VERSION ""

NS_ :

BS_:

BU_: GENERIC_GWMWakeup Generic_BCM TRM GWM _delete APIM SODL RTM FCIM PDM SCMH SCMG HSWM GPSM RSM SODR DDM RBM DSM SCME TSTR

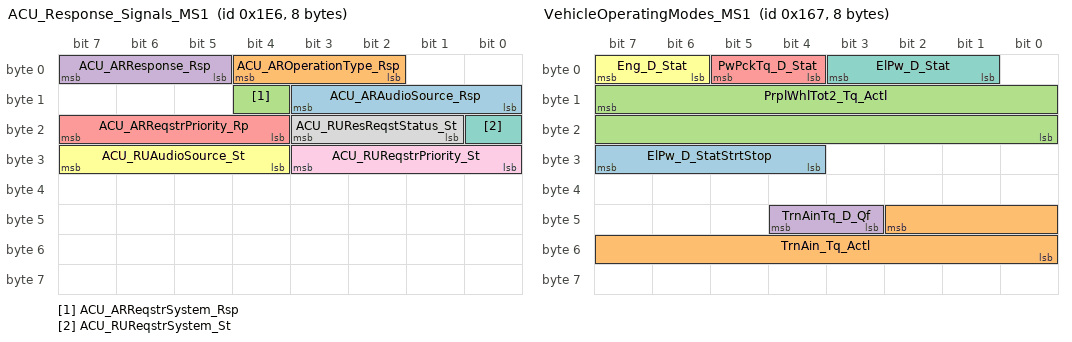
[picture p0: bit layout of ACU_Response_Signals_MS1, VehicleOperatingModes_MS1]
BO_ 486 ACU_Response_Signals_MS1: 8 GWM
 SG_ ACU_ARAudioSource_Rsp : 11|4@0+ (1,0) [0|15] "unitless"  FCIM
 SG_ ACU_AROperationType_Rsp : 4|3@0+ (1,0) [0|7] "unitless"  FCIM
 SG_ ACU_ARReqstrSystem_Rsp : 12|1@0+ (1,0) [0|1] "unitless"  FCIM
 SG_ ACU_ARResponse_Rsp : 7|3@0+ (1,0) [0|6] "unitless"  FCIM
 SG_ ACU_ARReqstrPriority_Rp : 23|4@0+ (1,0) [0|15] "unitless"  FCIM
 SG_ ACU_RUAudioSource_St : 31|4@0+ (1,0) [0|15] "unitless"  FCIM
 SG_ ACU_RUReqstrSystem_St : 16|1@0+ (1,0) [0|1] "unitless"  FCIM
 SG_ ACU_RUResReqstStatus_St : 19|3@0+ (1,0) [0|7] "unitless"  FCIM
 SG_ ACU_RUReqstrPriority_St : 27|4@0+ (1,0) [0|15] "unitless"  FCIM

BO_ 359 VehicleOperatingModes_MS1: 8 GWM
 SG_ ElPw_D_StatStrtStop : 31|4@0+ (1,0) [0|15] "SED" Vector__XXX
 SG_ TrnAin_Tq_Actl : 42|11@0+ (1,-500) [-500|1547] "Nm" Vector__XXX
 SG_ PrplWhlTot2_Tq_Actl : 15|16@0+ (4,-131072) [-131072|131060] "Nm" Vector__XXX
 SG_ TrnAinTq_D_Qf : 44|2@0+ (1,0) [0|3] "SED" Vector__XXX
 SG_ PwPckTq_D_Stat : 5|2@0+ (1,0) [0|3] "SED"  SCME,RSM,HSWM,TRM,SCMH,SCMG,RTM,RBM,PDM,GPSM,FCIM,DSM,DDM
 SG_ Eng_D_Stat : 7|2@0+ (1,0) [0|3] "SED"  FCIM
 SG_ ElPw_D_Stat : 3|3@0+ (1,0) [0|7] "SED"  SCMG,SCMH,TRM,DDM,DSM,FCIM,GPSM,PDM,RBM,RTM

BO_ 131 Yaw_Data_MS1: 8 GWM
 SG_ VehYaw_W_Actl_UB : 40|1@0+ (1,0) [0|1] "SED"  SODL,SODR,GPSM
 SG_ VehYaw_W_Actl : 55|16@0+ (0.0002,-6.5) [-6.5|6.6066] "rad/s"  SODL,SODR,GPSM

BO_ 990 Personality_DDM_Data: 8 DDM
 SG_ FeatNoDdm_No_Actl : 23|16@0+ (1,0) [0|65535] "Number"  GWM
 SG_ FeatConfigDdmActl : 7|16@0+ (1,0) [0|65535] "Undefined"  GWM

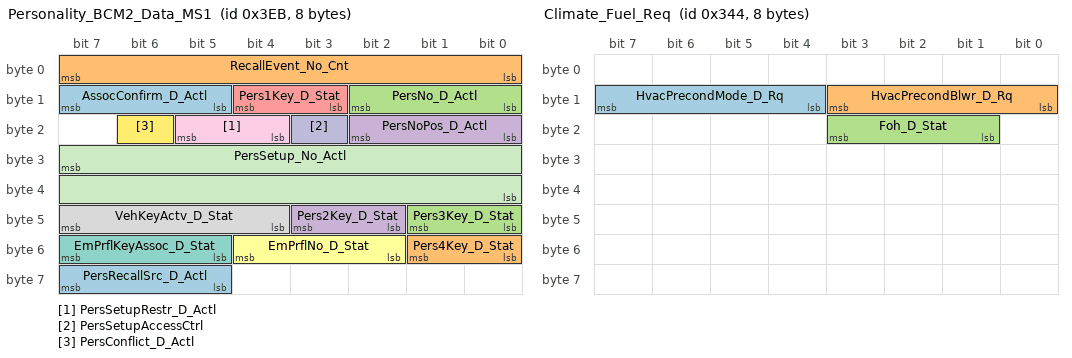
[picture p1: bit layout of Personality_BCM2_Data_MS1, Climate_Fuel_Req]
BO_ 1003 Personality_BCM2_Data_MS1: 8 GWM
 SG_ PersRecallSrc_D_Actl : 63|3@0+ (1,0) [0|7] "SED"  DSM
 SG_ Pers4Key_D_Stat : 49|2@0+ (1,0) [0|3] "SED" Vector__XXX
 SG_ Pers3Key_D_Stat : 41|2@0+ (1,0) [0|3] "SED" Vector__XXX
 SG_ Pers2Key_D_Stat : 43|2@0+ (1,0) [0|3] "SED" Vector__XXX
 SG_ Pers1Key_D_Stat : 12|2@0+ (1,0) [0|3] "SED" Vector__XXX
 SG_ EmPrflNo_D_Stat : 52|3@0+ (1,0) [0|7] "SED" Vector__XXX
 SG_ EmPrflKeyAssoc_D_Stat : 55|3@0+ (1,0) [0|7] "SED" Vector__XXX
 SG_ VehKeyActv_D_Stat : 47|4@0+ (1,0) [0|15] "SED" Vector__XXX
 SG_ PersSetupRestr_D_Actl : 21|2@0+ (1,0) [0|3] "SED"  DDM,DSM,FCIM
 SG_ PersSetupAccessCtrl : 19|1@0+ (1,0) [0|1] "SED"  DDM,FCIM,DSM
 SG_ PersSetup_No_Actl : 31|16@0+ (1,0) [0|65535] "Number"  DDM,DSM,FCIM
 SG_ PersConflict_D_Actl : 22|1@0+ (1,0) [0|1] "SED" Vector__XXX
 SG_ AssocConfirm_D_Actl : 15|3@0+ (1,0) [0|7] "SED" Vector__XXX
 SG_ RecallEvent_No_Cnt : 7|8@0+ (1,0) [0|255] "Counts"  SCMG,SCMH,DDM,DSM,FCIM
 SG_ PersNo_D_Actl : 10|3@0+ (1,0) [0|7] "SED"  DDM,DSM,FCIM,SCMG,SCMH
 SG_ PersNoPos_D_Actl : 18|3@0+ (1,0) [0|7] "SED"  SCMG,SCMH,DSM

BO_ 1945 TesterPhysicalResTRM: 8 TRM
 SG_ TesterPhysicalResTRM : 7|64@0+ (1,0) [0|1.84467E+019] "unitless"  TSTR

BO_ 836 Climate_Fuel_Req: 8 GENERIC_GWMWakeup
 SG_ HvacPrecondMode_D_Rq : 15|4@0+ (1,0) [0|15] "SED"  GWM
 SG_ HvacPrecondBlwr_D_Rq : 11|4@0+ (1,0) [0|15] "SED"  GWM
 SG_ Foh_D_Stat : 19|3@0+ (1,0) [0|7] "SED"  GWM

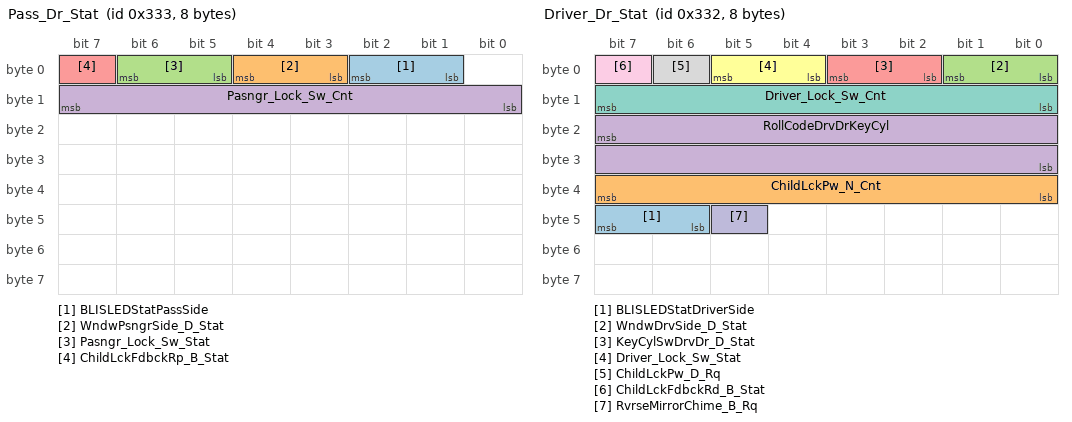
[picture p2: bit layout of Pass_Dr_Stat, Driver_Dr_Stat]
BO_ 819 Pass_Dr_Stat: 8 PDM
 SG_ BLISLEDStatPassSide : 2|2@0+ (1,0) [0|3] "SED"  SODL,SODR
 SG_ WndwPsngrSide_D_Stat : 4|2@0+ (1,0) [0|3] "SED"  GWM
 SG_ Pasngr_Lock_Sw_Stat : 6|2@0+ (1,0) [0|3] "SED"  GWM
 SG_ Pasngr_Lock_Sw_Cnt : 15|8@0+ (1,0) [0|255] "Cnt"  GWM
 SG_ ChildLckFdbckRp_B_Stat : 7|1@0+ (1,0) [0|1] "SED"  GWM

BO_ 818 Driver_Dr_Stat: 8 DDM
 SG_ BLISLEDStatDriverSide : 47|2@0+ (1,0) [0|3] "SED"  SODL,SODR
 SG_ ChildLckPw_N_Cnt : 39|8@0+ (1,0) [0|255] "unitless"  GWM
 SG_ WndwDrvSide_D_Stat : 1|2@0+ (1,0) [0|3] "SED"  GWM
 SG_ RollCodeDrvDrKeyCyl : 23|16@0+ (1,0) [0|65535] "Unitless"  GWM
 SG_ KeyCylSwDrvDr_D_Stat : 3|2@0+ (1,0) [0|3] "SED"  GWM
 SG_ Driver_Lock_Sw_Stat : 5|2@0+ (1,0) [0|3] "SED"  GWM
 SG_ Driver_Lock_Sw_Cnt : 15|8@0+ (1,0) [0|255] "Cnt"  GWM
 SG_ ChildLckPw_D_Rq : 6|1@0+ (1,0) [0|1] "SED"  GWM
 SG_ ChildLckFdbckRd_B_Stat : 7|1@0+ (1,0) [0|1] "SED"  GWM
 SG_ RvrseMirrorChime_B_Rq : 45|1@0+ (1,0) [0|1] "SED"  DSM,GWM

BO_ 817 Locking_Systems_2_MS1: 8 GWM
 SG_ R_Pwr_Sliding_Dr_Rqst : 36|1@0+ (1,0) [0|1] "SED" Vector__XXX
 SG_ L_Pwr_Sliding_Dr_Rqst : 3|1@0+ (1,0) [0|1] "SED" Vector__XXX
 SG_ ChildLckMde_B_Stat : 56|1@0+ (1,0) [0|1] "SED" Vector__XXX
 SG_ VehLckInd_D_Rq : 58|2@0+ (1,0) [0|3] "SED"  DDM,PDM
 SG_ DrTgateOpen_B_Rq : 59|1@0+ (1,0) [0|1] "SED" Vector__XXX
 SG_ DrTgateExtSwMde_B_Stat : 32|1@0+ (1,0) [0|1] "SED" Vector__XXX
 SG_ Remote_Device_Feedback : 50|3@0+ (1,0) [0|7] "SED"  RSM,RTM
 SG_ Power_Liftgate_Rqst : 0|1@0+ (1,0) [0|1] "SED" Vector__XXX
 SG_ Power_Decklid_Rqst : 1|1@0+ (1,0) [0|1] "SED" Vector__XXX
 SG_ Keyfob_Pad_Msg_Count : 15|8@0+ (1,0) [0|255] "Counts" Vector__XXX
 SG_ Veh_Lock_Requestor : 55|5@0+ (1,0) [0|31] "SED"  RSM,DDM,PDM
 SG_ Veh_Lock_EvNum : 47|8@0+ (1,0) [0|255] "unitless"  RSM,DDM,PDM
 SG_ Veh_Lock_Sub_Id : 63|4@0+ (1,0) [0|15] "SED"  RSM,DDM,PDM
 SG_ ChildLck_D_Dsply : 7|2@0+ (1,0) [0|3] "SED"  DDM
 SG_ WindowLockout_B_Stat : 35|1@0+ (1,0) [0|1] "SED"  DDM
 SG_ RollCodeUnlock : 23|16@0+ (1,0) [0|65535] "Unitless"  RSM,DDM
 SG_ Lockmsgtxt_D_Rq : 39|3@0+ (1,0) [0|7] "SED" Vector__XXX
 SG_ LockInhibit : 2|1@0+ (1,0) [0|1] "SED" Vector__XXX
 SG_ Veh_Lock_Status : 34|2@0+ (1,0) [0|3] "SED"  RSM,DDM,PDM
 SG_ FobComm_D_Stat : 5|2@0+ (1,0) [0|3] "SED"  RTM

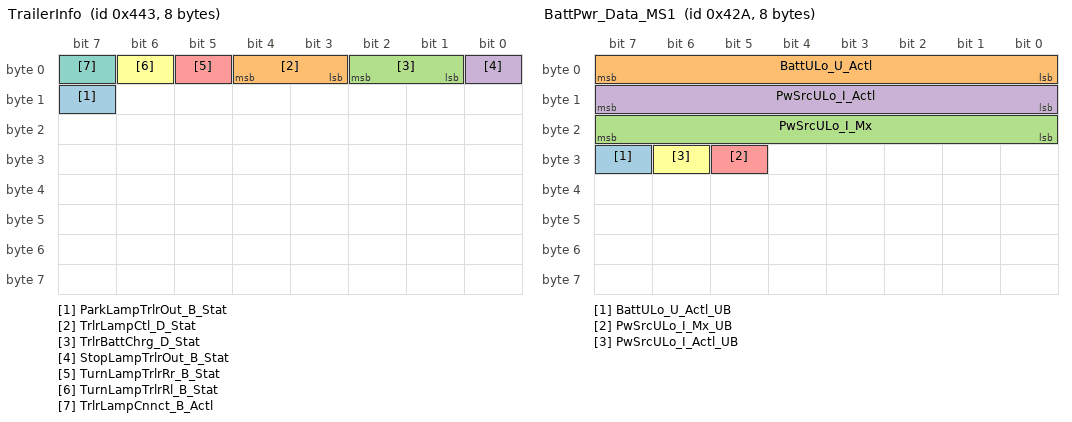
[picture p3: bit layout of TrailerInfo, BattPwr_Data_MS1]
BO_ 1091 TrailerInfo: 8 TRM
 SG_ ParkLampTrlrOut_B_Stat : 15|1@0+ (1,0) [0|1] "SED"  GWM
 SG_ TrlrLampCtl_D_Stat : 4|2@0+ (1,0) [0|3] "SED"  GWM
 SG_ TrlrBattChrg_D_Stat : 2|2@0+ (1,0) [0|3] "SED"  GWM
 SG_ StopLampTrlrOut_B_Stat : 0|1@0+ (1,0) [0|1] "SED"  GWM
 SG_ TurnLampTrlrRr_B_Stat : 5|1@0+ (1,0) [0|1] "SED"  GWM
 SG_ TurnLampTrlrRl_B_Stat : 6|1@0+ (1,0) [0|1] "SED"  GWM
 SG_ TrlrLampCnnct_B_Actl : 7|1@0+ (1,0) [0|1] "SED"  SODL,SODR,GWM

BO_ 1285 PDM_Network_MgmtM: 8 PDM
 SG_ PDM_Network_Mgmt : 7|64@0+ (1,0) [0|1.844674407371E+019] "unitless"  DDM,DSM,FCIM,GPSM,RBM,RTM,SCME,TRM,GWM,APIM

BO_ 1865 TesterPhysicalResPDM: 8 PDM
 SG_ TesterPhysicalResPDM : 7|64@0+ (1,0) [0|1.84467E+019] "unitless"  TSTR

BO_ 1857 TesterPhysicalReqPDM: 8 TSTR
 SG_ TesterPhysicalReqPDM : 7|64@0+ (1,0) [0|1.84467E+019] "unitless"  PDM

BO_ 1819 TesterPhysicalResSCMH: 8 SCMH
 SG_ TesterPhysicalResSCMH : 7|64@0+ (1,0) [0|1.84467E+019] "unitless"  TSTR

BO_ 1818 TesterPhysicalResSCMG: 8 SCMG
 SG_ TesterPhysicalResSCMG : 7|64@0+ (1,0) [0|1.84467E+019] "unitless"  TSTR

BO_ 1811 TesterPhysicalReqSCMH: 8 TSTR
 SG_ TesterPhysicalReqSCMH : 7|64@0+ (1,0) [0|1.84467E+019] "unitless"  SCMH

BO_ 1810 TesterPhysicalReqSCMG: 8 TSTR
 SG_ TesterPhysicalReqSCMG : 7|64@0+ (1,0) [0|1.84467E+019] "unitless"  SCMG

BO_ 1373 FCIM_Network_MgmtM: 8 FCIM
 SG_ FCIM_Network_Mgmt : 7|64@0+ (1,0) [0|1.844674407371E+019] "unitless"  DDM,DSM,GPSM,RBM,RTM,SCME,APIM,PDM,GWM,TRM

BO_ 1339 RTM_Network_MgmtM: 8 RTM
 SG_ RTM_Network_Mgmt : 7|64@0+ (1,0) [0|1.844674407371E+019] "unitless"  APIM,PDM,TRM,SCME,RBM,GPSM,FCIM,DSM,DDM

BO_ 1310 GWM_Network_MgmtM_MS1: 8 GWM
 SG_ GWM_Network_Mgmt_MS1 : 7|64@0+ (1,0) [0|1.844674407371E+019] "unitless"  DDM,DSM,FCIM,GPSM,PDM,RBM,RTM,SCME,TRM

BO_ 1066 BattPwr_Data_MS1: 8 GWM
 SG_ BattULo_U_Actl_UB : 31|1@0+ (1,0) [0|1] "SED"  FCIM
 SG_ BattULo_U_Actl : 7|8@0+ (0.0625,0) [0|15.875] "volt"  FCIM
 SG_ PwSrcULo_I_Mx : 23|8@0+ (1,0) [0|254] "ampere"  FCIM
 SG_ PwSrcULo_I_Actl : 15|8@0+ (1,0) [0|254] "ampere"  FCIM
 SG_ PwSrcULo_I_Mx_UB : 29|1@0+ (1,0) [0|1] "SED"  FCIM
 SG_ PwSrcULo_I_Actl_UB : 30|1@0+ (1,0) [0|1] "SED"  FCIM

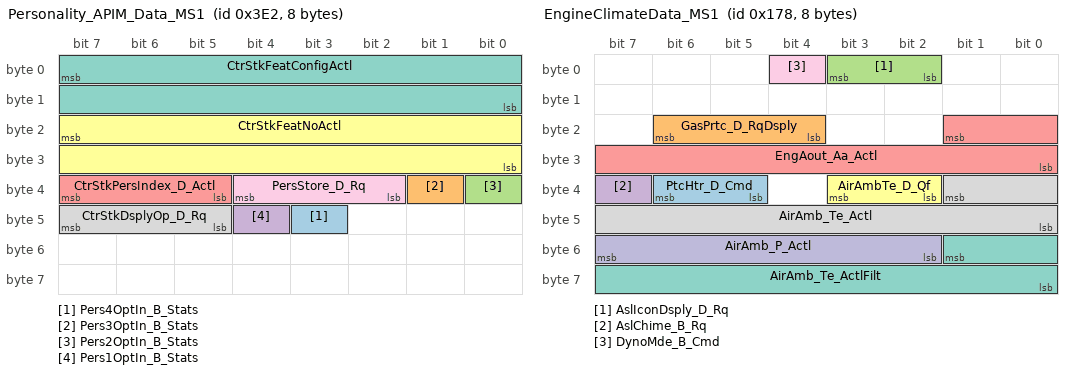
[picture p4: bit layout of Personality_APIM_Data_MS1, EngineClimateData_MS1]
BO_ 994 Personality_APIM_Data_MS1: 8 GWM
 SG_ Pers4OptIn_B_Stats : 43|1@0+ (1,0) [0|1] "SED" Vector__XXX
 SG_ Pers3OptIn_B_Stats : 33|1@0+ (1,0) [0|1] "SED" Vector__XXX
 SG_ Pers2OptIn_B_Stats : 32|1@0+ (1,0) [0|1] "SED" Vector__XXX
 SG_ Pers1OptIn_B_Stats : 44|1@0+ (1,0) [0|1] "SED" Vector__XXX
 SG_ CtrStkPersIndex_D_Actl : 39|3@0+ (1,0) [0|7] "SED"  DDM,DSM,FCIM,SCMG,SCMH
 SG_ CtrStkFeatNoActl : 23|16@0+ (1,0) [0|65535] "Undefined"  DDM,DSM,FCIM
 SG_ CtrStkFeatConfigActl : 7|16@0+ (1,0) [0|65535] "Undefined"  DDM,DSM,FCIM
 SG_ CtrStkDsplyOp_D_Rq : 47|3@0+ (1,0) [0|7] "SED"  DDM,DSM,FCIM,SCMG,SCMH
 SG_ PersStore_D_Rq : 36|3@0+ (1,0) [0|7] "SED"  DSM

BO_ 376 EngineClimateData_MS1: 8 GWM
 SG_ PtcHtr_D_Cmd : 38|2@0+ (1,0) [0|3] "SED" Vector__XXX
 SG_ GasPrtc_D_RqDsply : 22|3@0+ (1,0) [0|7] "SED" Vector__XXX
 SG_ AslIconDsply_D_Rq : 3|2@0+ (1,0) [0|3] "SED" Vector__XXX
 SG_ AslChime_B_Rq : 39|1@0+ (1,0) [0|1] "SED" Vector__XXX
 SG_ EngAout_Aa_Actl : 17|10@0+ (0.05,-25.6) [-25.6|25.55] "rpm/ms" Vector__XXX
 SG_ AirAmbTe_D_Qf : 35|2@0+ (1,0) [0|3] "SED"  FCIM
 SG_ AirAmb_Te_ActlFilt : 49|10@0+ (0.25,-128) [-128|127.75] "deg C"  FCIM
 SG_ AirAmb_Te_Actl : 33|10@0+ (0.25,-128) [-128|127.75] "degC"  FCIM
 SG_ DynoMde_B_Cmd : 4|1@0+ (1,0) [0|1] "SED" Vector__XXX
 SG_ AirAmb_P_Actl : 55|6@0+ (10,500) [500|1110] "mbar" Vector__XXX

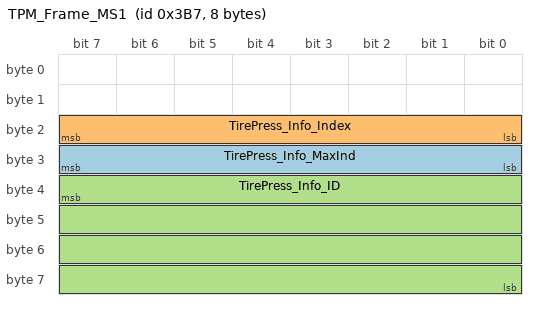
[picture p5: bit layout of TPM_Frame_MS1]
BO_ 951 TPM_Frame_MS1: 8 GWM
 SG_ TirePress_Info_MaxInd : 31|8@0+ (1,0) [0|255] "Unitless"  RTM
 SG_ TirePress_Info_Index : 23|8@0+ (1,0) [0|255] "Unitless"  RTM
 SG_ TirePress_Info_ID : 39|32@0+ (1,0) [0|4294967295] "Unitless"  RTM

BO_ 1068 Batt_Mgmt_Data_MS1: 8 GWM
 SG_ Batt_Lo_SoC_B_UB : 22|1@0+ (1,0) [0|1] "SED"  TRM,FCIM
 SG_ Batt_Lo_SoC_B : 23|1@0+ (1,0) [0|1] "SED"  TRM,FCIM
 SG_ Batt_Crit_SoC_B_UB : 14|1@0+ (1,0) [0|1] "SED"  TRM,FCIM
 SG_ Batt_Crit_SoC_B : 15|1@0+ (1,0) [0|1] "SED"  TRM,FCIM
 SG_ Shed_T_Eng_Off_B_UB : 12|1@0+ (1,0) [0|1] "SED"  TRM,FCIM
 SG_ Shed_T_Eng_Off_B : 13|1@0+ (1,0) [0|1] "SED"  TRM,FCIM
 SG_ Shed_Level_Req_UB : 8|1@0+ (1,0) [0|1] "SED"  DDM,PDM,TRM,FCIM
 SG_ Shed_Level_Req : 11|3@0+ (1,0) [0|7] "SED"  DDM,PDM,TRM,FCIM
 SG_ Shed_Feature_Group_ID_UB : 2|1@0+ (1,0) [0|1] "SED"  TRM,FCIM
 SG_ Shed_Feature_Group_ID : 7|5@0+ (1,0) [0|31] "SED"  TRM,FCIM
 SG_ Shed_Drain_Eng_Off_B_UB : 0|1@0+ (1,0) [0|1] "SED"  TRM,FCIM
 SG_ Shed_Drain_Eng_Off_B : 1|1@0+ (1,0) [0|1] "SED"  TRM,FCIM
 SG_ BSBattSOC_UB : 48|1@0+ (1,0) [0|1] "SED"  FCIM
 SG_ AirCondRec_B_Rq_UB : 44|1@0+ (1,0) [0|1] "SED"  FCIM
 SG_ AirCondFluidHi_P_Actl_UB : 45|1@0+ (1,0) [0|1] "SED"  FCIM
 SG_ BattULoState_D_Qlty_UB : 40|1@0+ (1,0) [0|1] "SED" Vector__XXX
 SG_ AirCondClutch_B_Stats_UB : 43|1@0+ (1,0) [0|1] "SED"  FCIM
 SG_ AirCondRec_B_Rq : 47|1@0+ (1,0) [0|1] "SED"  FCIM
 SG_ BSBattSOC : 55|7@0+ (1,0) [0|127] "%"  FCIM
 SG_ AirCondFluidHi_P_Actl : 39|8@0+ (0.125,0) [0|31.625] "bar"  FCIM
 SG_ AirCondClutch_B_Stats : 46|1@0+ (1,0) [0|1] "SED"  FCIM
 SG_ BattULoState_D_Qlty : 42|2@0+ (1,0) [0|3] "SED" Vector__XXX

BO_ 963 BCM_Lamp_Stat_MS1: 8 GWM
 SG_ WrlssAcsyChrgInhbt_B_Rq : 40|1@0+ (1,0) [0|1] "SED" Vector__XXX
 SG_ PudLampPsngr_D_Rq : 57|2@0+ (1,0) [0|3] "SED" Vector__XXX
 SG_ PudLampDrv_D_Rq : 59|2@0+ (1,0) [0|3] "SED" Vector__XXX
 SG_ DrTgateLck_D_Stat : 61|2@0+ (1,0) [0|3] "SED" Vector__XXX
 SG_ Illuminated_Entry_Stat : 63|2@0+ (1,0) [0|3] "SED" Vector__XXX
 SG_ Dr_Courtesy_Light_Stat : 49|2@0+ (1,0) [0|3] "SED" Vector__XXX
 SG_ ImpactEvntFdbck_D_Stat : 53|2@0+ (1,0) [0|3] "SED" Vector__XXX
 SG_ HeadLampLoOut_B_Stat : 32|1@0+ (1,0) [0|1] "SED" Vector__XXX
 SG_ CrnrLghtRight_Pc_Rq : 47|7@0+ (1,0) [0|100] "percent" Vector__XXX
 SG_ CrnrLghtLeft_Pc_Rq : 39|7@0+ (1,0) [0|100] "percent" Vector__XXX
 SG_ HeadLghtHiFdbck_D_Stat : 55|2@0+ (1,0) [0|3] "SED" Vector__XXX
 SG_ PrkLightChime_B_Rq : 25|1@0+ (1,0) [0|1] "SED" Vector__XXX
 SG_ TrnNotInPrkChime_B_Rq : 24|1@0+ (1,0) [0|1] "SED" Vector__XXX
 SG_ HomeSafeLtChime_B_Rq : 28|1@0+ (1,0) [0|1] "SED" Vector__XXX
 SG_ StopLghtOn_B_Stat : 8|1@0+ (1,0) [0|1] "SED"  RSM,TRM
 SG_ RvrseLghtOn_B_Stat : 9|1@0+ (1,0) [0|1] "SED"  TRM
 SG_ PrkLght_D_Stat : 13|2@0+ (1,0) [0|3] "SED"  TRM
 SG_ HeadLghtSwtch_D_Stat : 15|2@0+ (1,0) [0|3] "SED" Vector__XXX
 SG_ KeyInIgnWarn_B_Cmd : 27|1@0+ (1,0) [0|1] "SED" Vector__XXX
 SG_ HeadLampLoFrOn_B_Stat : 2|1@0+ (1,0) [0|1] "SED" Vector__XXX
 SG_ HeadLampLoFlOn_B_Stat : 3|1@0+ (1,0) [0|1] "SED" Vector__XXX
 SG_ Headlamp_On_Wrning_Cmd : 29|1@0+ (1,0) [0|1] "SED" Vector__XXX
 SG_ HeadLampLoActv_B_Stat : 4|1@0+ (1,0) [0|1] "SED" Vector__XXX
 SG_ HeadLghtHiOn_B_Stat : 1|1@0+ (1,0) [0|1] "SED" Vector__XXX
 SG_ Park_Brake_Chime_Rqst : 26|1@0+ (1,0) [0|1] "SED" Vector__XXX
 SG_ BrkWarnInd_B_Rq : 20|1@0+ (1,0) [0|1] "SED" Vector__XXX
 SG_ Brk_Fluid_Lvl_Low : 31|2@0+ (1,0) [0|3] "SED" Vector__XXX
 SG_ ReducedGuard_D_Stat : 19|2@0+ (1,0) [0|3] "SED" Vector__XXX
 SG_ Courtesy_BSave_Stat : 7|2@0+ (1,0) [0|3] "SED"  DDM,PDM
 SG_ DayRnngLampOn_B_Stat : 5|1@0+ (1,0) [0|1] "SED" Vector__XXX
 SG_ PerimeterAlarmChimeRq : 0|1@0+ (1,0) [0|1] "SED" Vector__XXX
 SG_ Courtesy_Delay_Status : 51|2@0+ (1,0) [0|3] "SED" Vector__XXX
 SG_ Perimeter_Alarm_Status : 17|2@0+ (1,0) [0|3] "SED"  RSM
 SG_ WndwGlbl_D_Cmd : 23|3@0+ (1,0) [0|7] "SED"  DDM,PDM
 SG_ PudLamp_D_Rq : 11|2@0+ (1,0) [0|3] "SED"  DDM,PDM

BO_ 964 BodyInfo_MS1: 8 GWM
 SG_ Cta_D_Rq_UB : 57|1@0+ (1,0) [0|1] "SED"  SODL,SODR
 SG_ Cta_D_Rq : 59|2@0+ (1,0) [0|3] "SED"  SODL,SODR
 SG_ GearRvrse_D_Actl_UB : 48|1@0+ (1,0) [0|1] "SED"  SODL,SODR
 SG_ GearRvrse_D_Actl : 51|3@0+ (1,0) [0|7] "SED"  SODL,SODR
 SG_ TurnLghtSwtch_D_Stat_UB : 52|1@0+ (1,0) [0|1] "SED"  SODL,SODR
 SG_ TurnLghtSwtch_D_Stat : 54|2@0+ (1,0) [0|3] "SED"  SODL,SODR
 SG_ Power_Liftgate_Mode_Cmd_UB : 6|1@0+ (1,0) [0|1] "SED" Vector__XXX
 SG_ Power_Liftgate_Mode_Cmd : 7|1@0+ (1,0) [0|1] "SED" Vector__XXX
 SG_ MetricActvTe_B_Actl_UB : 2|1@0+ (1,0) [0|1] "SED"  FCIM
 SG_ MetricActvTe_B_Actl : 3|1@0+ (1,0) [0|1] "SED"  FCIM
 SG_ EngClntTe_D_Qf : 22|2@0+ (1,0) [0|3] "SED"  FCIM
 SG_ Sod_D_Rq : 1|2@0+ (1,0) [0|3] "SED"  SODL,SODR
 SG_ MetricActv_B_Actl : 5|1@0+ (1,0) [0|1] "SED"  FCIM
 SG_ EngClnt_Te_Actl : 15|8@0+ (1,-60) [-60|195] "degC"  FCIM
 SG_ MetricActv_B_Actl_UB : 4|1@0+ (1,0) [0|1] "SED"  FCIM
 SG_ EngClnt_Te_Actl_UB : 23|1@0+ (1,0) [0|1] "SED"  FCIM
 SG_ OCSSensrDataUpperLim_UB : 28|1@0+ (1,0) [0|1] "SED"  SCMG,SCMH,FCIM
 SG_ OCSSensrDataUpperLim : 47|8@0+ (1,0) [0|254] "SED"  SCMG,SCMH,FCIM
 SG_ OCSSensrDataLowerLim_UB : 29|1@0+ (1,0) [0|1] "SED"  SCMG,SCMH,FCIM
 SG_ PrkAid_D_Falt : 18|3@0+ (1,0) [0|7] "SED" Vector__XXX
 SG_ OCSSensrDataLowerLim : 39|8@0+ (1,0) [0|254] "SED"  SCMG,SCMH,FCIM
 SG_ PrkAid_D_Falt_UB : 63|1@0+ (1,0) [0|1] "SED" Vector__XXX
 SG_ WiprFront_D_Stat_UB : 55|1@0+ (1,0) [0|1] "SED"  FCIM,SODL,SODR
 SG_ WiprFront_D_Stat : 27|4@0+ (1,0) [0|15] "SED"  FCIM,SODL,SODR
 SG_ CamraDefog_B_Req_UB : 30|1@0+ (1,0) [0|1] "SED" Vector__XXX
 SG_ Sod_D_Rq_UB : 19|1@0+ (1,0) [0|1] "SED"  SODL,SODR
 SG_ CamraDefog_B_Req : 31|1@0+ (1,0) [0|1] "SED" Vector__XXX

CM_ SG_ 486 ACU_ARAudioSource_Rsp "Object Audio Management AudioClient.AudioRequest.Requested Audio Source";
CM_ SG_ 486 ACU_AROperationType_Rsp "Object Audio Management AudioClient.AudioRequest.Operation Type";
CM_ SG_ 486 ACU_ARReqstrSystem_Rsp "Object Audio Management AudioClient.AudioRequest.Requester System";
CM_ SG_ 486 ACU_ARResponse_Rsp "Object Audio Management AudioClient.AudioRequest.Response";
CM_ SG_ 486 ACU_ARReqstrPriority_Rp "AR = Audio Request (this signal belongs to the logical signal AudioRequest.Rsp)
Object = AudioClient
Logical Signal = AudioRequest
Parameter = Requester Priority

Disc shall be used for both CD and MC";
CM_ SG_ 486 ACU_RUAudioSource_St "Object Audio Management Audio Client.ResourceUpdate.Requested Audio Source
";
CM_ SG_ 486 ACU_RUReqstrSystem_St "Object Audio Management Audio Client.ResourceUpdate.Requester System";
CM_ SG_ 486 ACU_RUResReqstStatus_St "Object Audio Management Audio Client.ResourceUpdate.Resource Request Status";
CM_ SG_ 486 ACU_RUReqstrPriority_St "Object Audio Management Audio Client.ResourceUpdate.Requester Priority";
CM_ SG_ 359 TrnAin_Tq_Actl "Signal not transmitted on HEV variances.";
CM_ SG_ 359 TrnAinTq_D_Qf "Signal not transmitted on HEV variances.";
CM_ SG_ 131 VehYaw_W_Actl "CCMGenSigTimeoutTime=1000";
CM_ SG_ 836 HvacPrecondMode_D_Rq "Signal not transmitted on vehicles that do not have the Fuel operated heater feature.";
CM_ SG_ 836 HvacPrecondBlwr_D_Rq "Signal not transmitted on vehicles that do not have the Fuel operated heater feature.";
CM_ SG_ 836 Foh_D_Stat "Signal not transmitted on vehicles that do not have the Fuel operated heater feature.";
CM_ SG_ 1091 TrlrLampCnnct_B_Actl "Not supported on CD4 M1";
CM_ SG_ 376 EngAout_Aa_Actl "Signal not transmitted on HEV variants.";
CM_ SG_ 1068 AirCondRec_B_Rq "Signal not transmitted on diesel variants.";
CM_ SG_ 1068 AirCondClutch_B_Stats "Signal not transmitted on diesel variants.";
CM_ SG_ 964 GearRvrse_D_Actl "Do not implement GearRvrse_D_Actl  until eTracker 8804151 is approved, 11/24/09";
CM_ SG_ 964 MetricActv_B_Actl "0 =Inactive(English), 1=Active(Metric)";
BA_DEF_ SG_  "U_V36X_MY18_5_Gas_Rx" ENUM  "No","Yes";
BA_DEF_ SG_  "U_V36X_MY18_5_Hev_Rx" ENUM  "No","Yes";
BA_DEF_ SG_  "U_U55x_MY18_Gas_Rx" ENUM  "No","Yes";
BA_DEF_ SG_  "U_V408_MY18_Gas_Rx" ENUM  "No","Yes";
BA_DEF_ SG_  "U_V408_MY18_Diesel_Rx" ENUM  "No","Yes";
BA_DEF_ SG_  "U_V36X_MY18_5_Diesel_Rx" ENUM  "No","Yes";
BA_DEF_ SG_  "U_V36X_MY19_5_Diesel_Rx" ENUM  "No","Yes";
BA_DEF_ SG_  "U_V363E_N_MY19_5_20_Gas_Rx" ENUM  "No","Yes";
BA_DEF_ SG_  "U_V363E_N_MY19_5_20_Diesel_Rx" ENUM  "No","Yes";
BA_DEF_ SG_  "U_U55x_MY18_Gas_Tx" ENUM  "No","Yes";
BA_DEF_ SG_  "GenSigTimeoutTime_SCMJ" INT 0 100000;
BA_DEF_ BO_  "FrameGatewayNetwork" STRING ;
BA_DEF_ SG_  "U_CD42_MY16_Diesel_Rx" ENUM  "No","Yes";
BA_DEF_ SG_  "U_CD42_MY16_Gas_Rx" ENUM  "No","Yes";
BA_DEF_ SG_  "U_CD43_MY17_Gas_Rx" ENUM  "No","Yes";
BA_DEF_ SG_  "U_P552_MY17_Gas_Rx" ENUM  "No","Yes";
BA_DEF_ SG_  "U_P552_MY17_Gas_Tx" ENUM  "No","Yes";
BA_DEF_ SG_  "GenSigTimeoutTime_SOBDMD_AHCM_F" INT 0 100000;
BA_DEF_ SG_  "GenSigTimeoutTime_SFMA" INT 0 100000;
BA_DEF_ SG_  "GenSigTimeoutTime_SFMB" INT 0 100000;
BA_DEF_ SG_  "GenSigTimeoutTime_SCMD" INT 0 100000;
BA_DEF_ SG_  "GenSigTimeoutTime_DCMH" INT 0 100000;
BA_DEF_ SG_  "GenSigTimeoutTime_DCMG" INT 0 100000;
BA_DEF_ SG_  "GenSigTimeoutTime_DCMF" INT 0 100000;
BA_DEF_ SG_  "GenSigTimeoutTime_DCME" INT 0 100000;
BA_DEF_ SG_  "GenSigTimeoutTime_BCMB_ABM" INT 0 100000;
BA_DEF_ SG_  "GenSigTimeoutTime_SCMC" INT 0 100000;
BA_DEF_ SG_  "GenSigTimeoutTime_BCMB_CAPM" INT 0 100000;
BA_DEF_ SG_  "GenSigTimeoutTime_GFM_ASM" INT 0 100000;
BA_DEF_ SG_  "GenSigTimeoutTime_SCMB_PSM" INT 0 100000;
BA_DEF_ SG_  "GenSigTimeoutTime_BCMB_ALCM" INT 0 100000;
BA_DEF_ SG_  "U_CD42_MY15_Diesel_Rx" ENUM  "No","Yes";
BA_DEF_ SG_  "U_CD42_MY15_Gas_Rx" ENUM  "No","Yes";
BA_DEF_ SG_  "U_U502_MY16_Gas_Rx" ENUM  "No","Yes";
BA_DEF_ SG_  "U_P558_MY17_Gas_Rx" ENUM  "No","Yes";
BA_DEF_ SG_  "U_P558_MY17_Diesel_Rx" ENUM  "No","Yes";
BA_DEF_ SG_  "U_CD42_MY15_Diesel_Tx" ENUM  "No","Yes";
BA_DEF_ SG_  "U_CD42_MY15_Gas_Tx" ENUM  "No","Yes";
BA_DEF_ SG_  "U_CD4_MY15_Diesel_Tx" ENUM  "No","Yes";
BA_DEF_ SG_  "U_CD4_MY15_Gas_Tx" ENUM  "No","Yes";
BA_DEF_ SG_  "U_CD4_MY15_Hev_Tx" ENUM  "No","Yes";
BA_DEF_ SG_  "U_CD4_MY15_Phev_Tx" ENUM  "No","Yes";
BA_DEF_ SG_  "U_P558_MY17_Gas_Tx" ENUM  "No","Yes";
BA_DEF_ SG_  "U_P558_MY17_Diesel_Tx" ENUM  "No","Yes";
BA_DEF_ SG_  "GenSigTimeoutTime_SCMF" INT 0 100000;
BA_DEF_ SG_  "GenSigTimeoutTime_RGTM" INT 0 100000;
BA_DEF_ SG_  "GenSigTimeoutTime_GENERIC" INT 0 100000;
BA_DEF_ SG_  "GenSigTimeoutTime_AHCM_FOH" INT 0 100000;
BA_DEF_ SG_  "GenSigTimeoutTime_RLCMA" INT 0 100000;
BA_DEF_ SG_  "GenSigTimeoutTime_BCMB" INT 0 100000;
BA_DEF_ SG_  "GenSigTimeoutTime_RHVAC" INT 0 100000;
BA_DEF_ SG_  "GenSigTimeoutTime_MRCMB" INT 0 100000;
BA_DEF_ SG_  "GenSigTimeoutTime_MRCMA" INT 0 100000;
BA_DEF_ SG_  "GenSigTimeoutTime_HVAC_RCCM" INT 0 100000;
BA_DEF_ SG_  "Gateway_ID" INT 0 0;
BA_DEF_ SG_  "GenSigTimeoutTime__delete" INT 0 100000;
BA_DEF_ SG_  "GenSigTimeoutTime_APIM" INT 0 100000;
BA_DEF_ SG_  "GenSigTimeoutTime_Generic_BCM" INT 0 100000;
BA_DEF_ SG_  "GenSigTimeoutTime_RSM" INT 0 100000;
BA_DEF_ SG_  "GenSigTimeoutTime_PDM" INT 0 100000;
BA_DEF_ SG_  "GenSigTimeoutTime_TRM" INT 0 100000;
BA_DEF_ SG_  "GenSigTimeoutTime_SCMG" INT 0 100000;
BA_DEF_ SG_  "GenSigTimeoutTime_SCMH" INT 0 100000;
BA_DEF_ SG_  "GenSigTimeoutTime_RTM" INT 0 100000;
BA_DEF_ SG_  "GenSigTimeoutTime_GWM" INT 0 100000;
BA_DEF_ SG_  "GenSigTimeoutTime_FCIM" INT 0 100000;
BA_DEF_ SG_  "GenSigTimeoutTime_HSWM" INT 0 100000;
BA_DEF_ SG_  "GenSigTimeoutTime_GPSM" INT 0 100000;
BA_DEF_ SG_  "GenSigTimeoutTime_RBM" INT 0 100000;
BA_DEF_ SG_  "GenSigTimeoutTime_DDM" INT 0 100000;
BA_DEF_ SG_  "GenSigTimeoutTime_DSM" INT 0 100000;
BA_DEF_ SG_  "GenSigTimeoutTime_SODR" INT 0 100000;
BA_DEF_ SG_  "GenSigTimeoutTime_SODL" INT 0 100000;
BA_DEF_ SG_  "GenSigTimeoutTime_TSTR" INT 0 100000;
BA_DEF_ SG_  "GenSigTimeoutTime_SCME" INT 0 100000;
BA_DEF_ BO_  "FrameGatewayMS1" HEX 0 1407;
BA_DEF_ BO_  "FrameGatewayHS3" HEX 0 1407;
BA_DEF_ BO_  "FrameGatewayHS2" HEX 0 1407;
BA_DEF_ BO_  "FrameGatewayHS1" HEX 0 1407;
BA_DEF_ BO_  "NetworkInitialization" ENUM  "No","Yes";
BA_DEF_ BO_  "FrameGatewayId" HEX 0 1407;
BA_DEF_ BO_  "EventRateOfChange" INT 10 10000;
BA_DEF_ BO_  "GenMsgStartDelayTime" INT 0 10000;
BA_DEF_ BO_  "GenMsgNrOfRepetition" INT 0 100;
BA_DEF_ BO_  "GenMsgDelayTime" INT 0 1000;
BA_DEF_ BO_  "GenMsgCycleTime" INT 0 100000;
BA_DEF_ BO_  "GenMsgSendType" ENUM  "FixedPeriodic","Event","EnabledPeriodic","NotUsed","NotUsed","EventPeriodic","NotUsed","NotUsed","NoMsgSendType";
BA_DEF_ SG_  "U_CD4_MY14_Phev_Tx" ENUM  "No","Yes";
BA_DEF_ SG_  "U_CD4_MY14_Hev_Tx" ENUM  "No","Yes";
BA_DEF_ SG_  "U_CD4_MY14_Gas_Tx" ENUM  "No","Yes";
BA_DEF_ SG_  "U_CD4_MY14_Diesel_Tx" ENUM  "No","Yes";
BA_DEF_ SG_  "U_CD43_MY16_Gas_Tx" ENUM  "No","Yes";
BA_DEF_ SG_  "U_UP375_MY15_Diesel_Tx" ENUM  "No","Yes";
BA_DEF_ SG_  "U_UP375_MY15_Gas_Tx" ENUM  "No","Yes";
BA_DEF_ SG_  "U_U502_MY15_Gas_Tx" ENUM  "No","Yes";
BA_DEF_ SG_  "U_B562LC_MY14_Gas_Tx" ENUM  "No","Yes";
BA_DEF_ SG_  "U_B562LC_MY14_Diesel_Tx" ENUM  "No","Yes";
BA_DEF_ SG_  "U_C489_MY14_Gas_Tx" ENUM  "No","Yes";
BA_DEF_ SG_  "U_S550_MY15_Gas_Tx" ENUM  "No","Yes";
BA_DEF_ SG_  "U_P552_MY15_Gas_Tx" ENUM  "No","Yes";
BA_DEF_ SG_  "U_CD42_MY14_Gas_Tx" ENUM  "No","Yes";
BA_DEF_ SG_  "U_CD42_MY14_Diesel_Tx" ENUM  "No","Yes";
BA_DEF_ SG_  "U_CD4_MY13_Phev_Tx" ENUM  "No","Yes";
BA_DEF_ SG_  "U_CD4_MY13_Hev_Tx" ENUM  "No","Yes";
BA_DEF_ SG_  "U_CD4_MY13_Gas_Tx" ENUM  "No","Yes";
BA_DEF_ SG_  "U_CD4_MY13_Diesel_Tx" ENUM  "No","Yes";
BA_DEF_ SG_  "U_CD4_MY14_Phev_Rx" ENUM  "No","Yes";
BA_DEF_ SG_  "U_CD4_MY14_Hev_Rx" ENUM  "No","Yes";
BA_DEF_ SG_  "U_CD4_MY14_Gas_Rx" ENUM  "No","Yes";
BA_DEF_ SG_  "U_CD4_MY14_Diesel_Rx" ENUM  "No","Yes";
BA_DEF_ SG_  "U_CD43_MY16_Gas_Rx" ENUM  "No","Yes";
BA_DEF_ SG_  "U_UP375_MY15_Diesel_Rx" ENUM  "No","Yes";
BA_DEF_ SG_  "U_UP375_MY15_Gas_Rx" ENUM  "No","Yes";
BA_DEF_ SG_  "U_B479_MY15_Gas_Rx" ENUM  "No","Yes";
BA_DEF_ SG_  "U_U502_MY15_Gas_Rx" ENUM  "No","Yes";
BA_DEF_ SG_  "U_B562LC_MY14_Gas_Rx" ENUM  "No","Yes";
BA_DEF_ SG_  "U_B562LC_MY14_Diesel_Rx" ENUM  "No","Yes";
BA_DEF_ SG_  "U_C489_MY14_Gas_Rx" ENUM  "No","Yes";
BA_DEF_ SG_  "U_S550_MY15_Gas_Rx" ENUM  "No","Yes";
BA_DEF_ SG_  "U_P552_MY15_Gas_Rx" ENUM  "No","Yes";
BA_DEF_ SG_  "U_CD42_MY14_Gas_Rx" ENUM  "No","Yes";
BA_DEF_ SG_  "U_CD42_MY14_Diesel_Rx" ENUM  "No","Yes";
BA_DEF_ SG_  "U_CD4_MY13_Phev_Rx" ENUM  "No","Yes";
BA_DEF_ SG_  "U_CD4_MY13_Hev_Rx" ENUM  "No","Yes";
BA_DEF_ SG_  "U_CD4_MY13_Gas_Rx" ENUM  "No","Yes";
BA_DEF_ SG_  "U_CD4_MY13_Diesel_Rx" ENUM  "No","Yes";
BA_DEF_ SG_  "ContentDependant" ENUM  "No","Yes";
BA_DEF_ SG_  "GenSigStartValue" INT 0 1000000000;
BA_DEF_ SG_  "UsedOnPgmDBC" ENUM  "No","Yes";
BA_DEF_ SG_  "CrossOver_LIN" ENUM  "No","Yes";
BA_DEF_ SG_  "CrossOver_InfoCAN" ENUM  "No","Yes";
BA_DEF_ SG_  "WakeupSignal" ENUM  "No","Yes";
BA_DEF_ SG_  "FMC_SIG_SSPEC" STRING ;
BA_DEF_ SG_  "GenSigMissingSourceValue" INT 0 1000000000;
BA_DEF_ SG_  "GenSigInactiveValue" INT 0 100000;
BA_DEF_ SG_  "GenSigSendType" ENUM  "Cyclic","OnWrite","vector_leerstring","OnChange","vector_leerstring","IfActive","vector_leerstring","NoSigSendType";
BA_DEF_ BO_  "DiagState" ENUM  "No","Yes";
BA_DEF_ BO_  "TpTxIndex" INT 0 255;
BA_DEF_ BO_  "DiagRequest" ENUM  "No","Yes";
BA_DEF_ BO_  "DiagResponse" ENUM  "No","Yes";
BA_DEF_ BO_  "NmMessage" ENUM  "No","Yes";
BA_DEF_ BO_  "GenMsgILSupport" ENUM  "No","Yes";
BA_DEF_DEF_  "U_V36X_MY18_5_Gas_Rx" "No";
BA_DEF_DEF_  "U_V36X_MY18_5_Hev_Rx" "No";
BA_DEF_DEF_  "U_U55x_MY18_Gas_Rx" "No";
BA_DEF_DEF_  "U_V408_MY18_Gas_Rx" "No";
BA_DEF_DEF_  "U_V408_MY18_Diesel_Rx" "No";
BA_DEF_DEF_  "U_V36X_MY18_5_Diesel_Rx" "No";
BA_DEF_DEF_  "U_V36X_MY19_5_Diesel_Rx" "No";
BA_DEF_DEF_  "U_V363E_N_MY19_5_20_Gas_Rx" "No";
BA_DEF_DEF_  "U_V363E_N_MY19_5_20_Diesel_Rx" "No";
BA_DEF_DEF_  "U_U55x_MY18_Gas_Tx" "No";
BA_DEF_DEF_  "GenSigTimeoutTime_SCMJ" 5000;
BA_DEF_DEF_  "FrameGatewayNetwork" "NONE";
BA_DEF_DEF_  "U_CD42_MY16_Diesel_Rx" "No";
BA_DEF_DEF_  "U_CD42_MY16_Gas_Rx" "No";
BA_DEF_DEF_  "U_CD43_MY17_Gas_Rx" "No";
BA_DEF_DEF_  "U_P552_MY17_Gas_Rx" "No";
BA_DEF_DEF_  "U_P552_MY17_Gas_Tx" "No";
BA_DEF_DEF_  "GenSigTimeoutTime_SOBDMD_AHCM_F" 5000;
BA_DEF_DEF_  "GenSigTimeoutTime_SFMA" 5000;
BA_DEF_DEF_  "GenSigTimeoutTime_SFMB" 5000;
BA_DEF_DEF_  "GenSigTimeoutTime_SCMD" 5000;
BA_DEF_DEF_  "GenSigTimeoutTime_DCMH" 5000;
BA_DEF_DEF_  "GenSigTimeoutTime_DCMG" 5000;
BA_DEF_DEF_  "GenSigTimeoutTime_DCMF" 5000;
BA_DEF_DEF_  "GenSigTimeoutTime_DCME" 5000;
BA_DEF_DEF_  "GenSigTimeoutTime_BCMB_ABM" 5000;
BA_DEF_DEF_  "GenSigTimeoutTime_SCMC" 5000;
BA_DEF_DEF_  "GenSigTimeoutTime_BCMB_CAPM" 5000;
BA_DEF_DEF_  "GenSigTimeoutTime_GFM_ASM" 5000;
BA_DEF_DEF_  "GenSigTimeoutTime_SCMB_PSM" 5000;
BA_DEF_DEF_  "GenSigTimeoutTime_BCMB_ALCM" 5000;
BA_DEF_DEF_  "U_CD42_MY15_Diesel_Rx" "No";
BA_DEF_DEF_  "U_CD42_MY15_Gas_Rx" "No";
BA_DEF_DEF_  "U_U502_MY16_Gas_Rx" "No";
BA_DEF_DEF_  "U_P558_MY17_Gas_Rx" "No";
BA_DEF_DEF_  "U_P558_MY17_Diesel_Rx" "No";
BA_DEF_DEF_  "U_CD42_MY15_Diesel_Tx" "No";
BA_DEF_DEF_  "U_CD42_MY15_Gas_Tx" "No";
BA_DEF_DEF_  "U_CD4_MY15_Diesel_Tx" "No";
BA_DEF_DEF_  "U_CD4_MY15_Gas_Tx" "No";
BA_DEF_DEF_  "U_CD4_MY15_Hev_Tx" "No";
BA_DEF_DEF_  "U_CD4_MY15_Phev_Tx" "No";
BA_DEF_DEF_  "U_P558_MY17_Gas_Tx" "No";
BA_DEF_DEF_  "U_P558_MY17_Diesel_Tx" "No";
BA_DEF_DEF_  "GenSigTimeoutTime_SCMF" 5000;
BA_DEF_DEF_  "GenSigTimeoutTime_RGTM" 5000;
BA_DEF_DEF_  "GenSigTimeoutTime_GENERIC" 5000;
BA_DEF_DEF_  "GenSigTimeoutTime_AHCM_FOH" 5000;
BA_DEF_DEF_  "GenSigTimeoutTime_RLCMA" 5000;
BA_DEF_DEF_  "GenSigTimeoutTime_BCMB" 5000;
BA_DEF_DEF_  "GenSigTimeoutTime_RHVAC" 5000;
BA_DEF_DEF_  "GenSigTimeoutTime_MRCMB" 5000;
BA_DEF_DEF_  "GenSigTimeoutTime_MRCMA" 5000;
BA_DEF_DEF_  "GenSigTimeoutTime_HVAC_RCCM" 5000;
BA_DEF_DEF_  "Gateway_ID" 0;
BA_DEF_DEF_  "GenSigTimeoutTime__delete" 5000;
BA_DEF_DEF_  "GenSigTimeoutTime_APIM" 5000;
BA_DEF_DEF_  "GenSigTimeoutTime_Generic_BCM" 5000;
BA_DEF_DEF_  "GenSigTimeoutTime_RSM" 5000;
BA_DEF_DEF_  "GenSigTimeoutTime_PDM" 5000;
BA_DEF_DEF_  "GenSigTimeoutTime_TRM" 5000;
BA_DEF_DEF_  "GenSigTimeoutTime_SCMG" 5000;
BA_DEF_DEF_  "GenSigTimeoutTime_SCMH" 5000;
BA_DEF_DEF_  "GenSigTimeoutTime_RTM" 5000;
BA_DEF_DEF_  "GenSigTimeoutTime_GWM" 5000;
BA_DEF_DEF_  "GenSigTimeoutTime_FCIM" 5000;
BA_DEF_DEF_  "GenSigTimeoutTime_HSWM" 5000;
BA_DEF_DEF_  "GenSigTimeoutTime_GPSM" 5000;
BA_DEF_DEF_  "GenSigTimeoutTime_RBM" 5000;
BA_DEF_DEF_  "GenSigTimeoutTime_DDM" 5000;
BA_DEF_DEF_  "GenSigTimeoutTime_DSM" 5000;
BA_DEF_DEF_  "GenSigTimeoutTime_SODR" 5000;
BA_DEF_DEF_  "GenSigTimeoutTime_SODL" 5000;
BA_DEF_DEF_  "GenSigTimeoutTime_TSTR" 5000;
BA_DEF_DEF_  "GenSigTimeoutTime_SCME" 5000;
BA_DEF_DEF_  "FrameGatewayMS1" 0;
BA_DEF_DEF_  "FrameGatewayHS3" 0;
BA_DEF_DEF_  "FrameGatewayHS2" 0;
BA_DEF_DEF_  "FrameGatewayHS1" 0;
BA_DEF_DEF_  "NetworkInitialization" "No";
BA_DEF_DEF_  "FrameGatewayId" 0;
BA_DEF_DEF_  "EventRateOfChange" 10000;
BA_DEF_DEF_  "GenMsgStartDelayTime" 0;
BA_DEF_DEF_  "GenMsgNrOfRepetition" 1;
BA_DEF_DEF_  "GenMsgDelayTime" 20;
BA_DEF_DEF_  "GenMsgCycleTime" 0;
BA_DEF_DEF_  "GenMsgSendType" "NoMsgSendType";
BA_DEF_DEF_  "U_CD4_MY14_Phev_Tx" "No";
BA_DEF_DEF_  "U_CD4_MY14_Hev_Tx" "No";
BA_DEF_DEF_  "U_CD4_MY14_Gas_Tx" "No";
BA_DEF_DEF_  "U_CD4_MY14_Diesel_Tx" "No";
BA_DEF_DEF_  "U_CD43_MY16_Gas_Tx" "No";
BA_DEF_DEF_  "U_UP375_MY15_Diesel_Tx" "No";
BA_DEF_DEF_  "U_UP375_MY15_Gas_Tx" "No";
BA_DEF_DEF_  "U_U502_MY15_Gas_Tx" "No";
BA_DEF_DEF_  "U_B562LC_MY14_Gas_Tx" "No";
BA_DEF_DEF_  "U_B562LC_MY14_Diesel_Tx" "No";
BA_DEF_DEF_  "U_C489_MY14_Gas_Tx" "No";
BA_DEF_DEF_  "U_S550_MY15_Gas_Tx" "No";
BA_DEF_DEF_  "U_P552_MY15_Gas_Tx" "No";
BA_DEF_DEF_  "U_CD42_MY14_Gas_Tx" "No";
BA_DEF_DEF_  "U_CD42_MY14_Diesel_Tx" "No";
BA_DEF_DEF_  "U_CD4_MY13_Phev_Tx" "No";
BA_DEF_DEF_  "U_CD4_MY13_Hev_Tx" "No";
BA_DEF_DEF_  "U_CD4_MY13_Gas_Tx" "No";
BA_DEF_DEF_  "U_CD4_MY13_Diesel_Tx" "No";
BA_DEF_DEF_  "U_CD4_MY14_Phev_Rx" "No";
BA_DEF_DEF_  "U_CD4_MY14_Hev_Rx" "No";
BA_DEF_DEF_  "U_CD4_MY14_Gas_Rx" "No";
BA_DEF_DEF_  "U_CD4_MY14_Diesel_Rx" "No";
BA_DEF_DEF_  "U_CD43_MY16_Gas_Rx" "No";
BA_DEF_DEF_  "U_UP375_MY15_Diesel_Rx" "No";
BA_DEF_DEF_  "U_UP375_MY15_Gas_Rx" "No";
BA_DEF_DEF_  "U_B479_MY15_Gas_Rx" "No";
BA_DEF_DEF_  "U_U502_MY15_Gas_Rx" "No";
BA_DEF_DEF_  "U_B562LC_MY14_Gas_Rx" "No";
BA_DEF_DEF_  "U_B562LC_MY14_Diesel_Rx" "No";
BA_DEF_DEF_  "U_C489_MY14_Gas_Rx" "No";
BA_DEF_DEF_  "U_S550_MY15_Gas_Rx" "No";
BA_DEF_DEF_  "U_P552_MY15_Gas_Rx" "No";
BA_DEF_DEF_  "U_CD42_MY14_Gas_Rx" "No";
BA_DEF_DEF_  "U_CD42_MY14_Diesel_Rx" "No";
BA_DEF_DEF_  "U_CD4_MY13_Phev_Rx" "No";
BA_DEF_DEF_  "U_CD4_MY13_Hev_Rx" "No";
BA_DEF_DEF_  "U_CD4_MY13_Gas_Rx" "No";
BA_DEF_DEF_  "U_CD4_MY13_Diesel_Rx" "No";
BA_DEF_DEF_  "ContentDependant" "No";
BA_DEF_DEF_  "GenSigStartValue" 0;
BA_DEF_DEF_  "UsedOnPgmDBC" "Yes";
BA_DEF_DEF_  "CrossOver_LIN" "No";
BA_DEF_DEF_  "CrossOver_InfoCAN" "No";
BA_DEF_DEF_  "WakeupSignal" "No";
BA_DEF_DEF_  "FMC_SIG_SSPEC" "Unknown";
BA_DEF_DEF_  "GenSigMissingSourceValue" 0;
BA_DEF_DEF_  "GenSigInactiveValue" 0;
BA_DEF_DEF_  "GenSigSendType" "NoSigSendType";
BA_DEF_DEF_  "DiagState" "No";
BA_DEF_DEF_  "TpTxIndex" 0;
BA_DEF_DEF_  "DiagRequest" "No";
BA_DEF_DEF_  "DiagResponse" "No";
BA_DEF_DEF_  "NmMessage" "No";
BA_DEF_DEF_  "GenMsgILSupport" "Yes";
BA_ "FrameGatewayNetwork" BO_ 486 "HS3_CAN";
BA_ "FrameGatewayId" BO_ 486 486;
BA_ "FrameGatewayHS3" BO_ 486 486;
BA_ "FrameGatewayNetwork" BO_ 359 "HS1_CAN";
BA_ "FrameGatewayId" BO_ 359 359;
BA_ "FrameGatewayHS1" BO_ 359 359;
BA_ "GenMsgSendType" BO_ 131 0;
BA_ "GenMsgCycleTime" BO_ 131 50;
BA_ "GenMsgSendType" BO_ 990 5;
BA_ "GenMsgCycleTime" BO_ 990 1000;
BA_ "FrameGatewayNetwork" BO_ 1003 "HS1_CAN";
BA_ "FrameGatewayId" BO_ 1003 1003;
BA_ "FrameGatewayHS1" BO_ 1003 1003;
BA_ "NetworkInitialization" BO_ 1003 1;
BA_ "GenMsgILSupport" BO_ 1945 0;
BA_ "DiagResponse" BO_ 1945 1;
BA_ "GenMsgSendType" BO_ 1945 1;
BA_ "GenMsgDelayTime" BO_ 1945 0;
BA_ "GenMsgSendType" BO_ 836 0;
BA_ "GenMsgCycleTime" BO_ 836 1000;
BA_ "GenMsgSendType" BO_ 819 5;
BA_ "GenMsgCycleTime" BO_ 819 100;
BA_ "GenMsgSendType" BO_ 818 5;
BA_ "GenMsgCycleTime" BO_ 818 100;
BA_ "GenMsgStartDelayTime" BO_ 818 100;
BA_ "FrameGatewayNetwork" BO_ 817 "HS1_CAN";
BA_ "FrameGatewayId" BO_ 817 817;
BA_ "FrameGatewayHS1" BO_ 817 817;
BA_ "NetworkInitialization" BO_ 817 1;
BA_ "GenMsgSendType" BO_ 1091 5;
BA_ "GenMsgCycleTime" BO_ 1091 1000;
BA_ "GenMsgILSupport" BO_ 1285 0;
BA_ "NmMessage" BO_ 1285 1;
BA_ "GenMsgSendType" BO_ 1285 1;
BA_ "GenMsgILSupport" BO_ 1865 0;
BA_ "DiagResponse" BO_ 1865 1;
BA_ "GenMsgSendType" BO_ 1865 1;
BA_ "GenMsgDelayTime" BO_ 1865 0;
BA_ "GenMsgILSupport" BO_ 1857 0;
BA_ "DiagRequest" BO_ 1857 1;
BA_ "GenMsgSendType" BO_ 1857 1;
BA_ "GenMsgDelayTime" BO_ 1857 0;
BA_ "GenMsgILSupport" BO_ 1819 0;
BA_ "DiagResponse" BO_ 1819 1;
BA_ "GenMsgSendType" BO_ 1819 1;
BA_ "GenMsgDelayTime" BO_ 1819 0;
BA_ "GenMsgILSupport" BO_ 1818 0;
BA_ "DiagResponse" BO_ 1818 1;
BA_ "GenMsgSendType" BO_ 1818 1;
BA_ "GenMsgDelayTime" BO_ 1818 0;
BA_ "GenMsgILSupport" BO_ 1811 0;
BA_ "DiagRequest" BO_ 1811 1;
BA_ "GenMsgSendType" BO_ 1811 1;
BA_ "GenMsgDelayTime" BO_ 1811 0;
BA_ "GenMsgILSupport" BO_ 1810 0;
BA_ "DiagRequest" BO_ 1810 1;
BA_ "GenMsgSendType" BO_ 1810 1;
BA_ "GenMsgDelayTime" BO_ 1810 0;
BA_ "GenMsgILSupport" BO_ 1373 0;
BA_ "NmMessage" BO_ 1373 1;
BA_ "GenMsgSendType" BO_ 1373 1;
BA_ "GenMsgILSupport" BO_ 1339 0;
BA_ "NmMessage" BO_ 1339 1;
BA_ "GenMsgSendType" BO_ 1339 1;
BA_ "GenMsgILSupport" BO_ 1310 0;
BA_ "NmMessage" BO_ 1310 1;
BA_ "GenMsgSendType" BO_ 1310 1;
BA_ "GenMsgSendType" BO_ 1066 0;
BA_ "GenMsgCycleTime" BO_ 1066 50;
BA_ "FrameGatewayHS3" BO_ 994 987;
BA_ "FrameGatewayHS1" BO_ 994 994;
BA_ "NetworkInitialization" BO_ 994 1;
BA_ "NetworkInitialization" BO_ 376 1;
BA_ "FrameGatewayNetwork" BO_ 376 "HS1_CAN";
BA_ "FrameGatewayId" BO_ 376 376;
BA_ "FrameGatewayHS1" BO_ 376 376;
BA_ "FrameGatewayNetwork" BO_ 951 "HS1_CAN";
BA_ "FrameGatewayId" BO_ 951 951;
BA_ "FrameGatewayHS1" BO_ 951 951;
BA_ "GenMsgSendType" BO_ 1068 0;
BA_ "GenMsgCycleTime" BO_ 1068 50;
BA_ "NetworkInitialization" BO_ 963 1;
BA_ "FrameGatewayNetwork" BO_ 963 "HS1_CAN";
BA_ "GenMsgStartDelayTime" BO_ 963 50;
BA_ "FrameGatewayId" BO_ 963 963;
BA_ "FrameGatewayHS1" BO_ 963 963;
BA_ "GenMsgSendType" BO_ 964 5;
BA_ "GenMsgCycleTime" BO_ 964 200;
BA_ "CrossOver_InfoCAN" SG_ 486 ACU_ARAudioSource_Rsp 1;
BA_ "U_CD4_MY13_Diesel_Rx" SG_ 486 ACU_ARAudioSource_Rsp 1;
BA_ "U_CD4_MY13_Gas_Rx" SG_ 486 ACU_ARAudioSource_Rsp 1;
BA_ "U_CD4_MY13_Hev_Rx" SG_ 486 ACU_ARAudioSource_Rsp 1;
BA_ "U_CD4_MY13_Phev_Rx" SG_ 486 ACU_ARAudioSource_Rsp 1;
BA_ "U_CD42_MY14_Diesel_Rx" SG_ 486 ACU_ARAudioSource_Rsp 1;
BA_ "U_CD42_MY14_Gas_Rx" SG_ 486 ACU_ARAudioSource_Rsp 1;
BA_ "U_P552_MY15_Gas_Rx" SG_ 486 ACU_ARAudioSource_Rsp 1;
BA_ "U_S550_MY15_Gas_Rx" SG_ 486 ACU_ARAudioSource_Rsp 1;
BA_ "U_C489_MY14_Gas_Rx" SG_ 486 ACU_ARAudioSource_Rsp 1;
BA_ "U_U502_MY15_Gas_Rx" SG_ 486 ACU_ARAudioSource_Rsp 1;
BA_ "U_UP375_MY15_Gas_Rx" SG_ 486 ACU_ARAudioSource_Rsp 1;
BA_ "U_UP375_MY15_Diesel_Rx" SG_ 486 ACU_ARAudioSource_Rsp 1;
BA_ "U_CD43_MY16_Gas_Rx" SG_ 486 ACU_ARAudioSource_Rsp 1;
BA_ "CrossOver_InfoCAN" SG_ 486 ACU_AROperationType_Rsp 1;
BA_ "U_CD4_MY13_Diesel_Rx" SG_ 486 ACU_AROperationType_Rsp 1;
BA_ "U_CD4_MY13_Gas_Rx" SG_ 486 ACU_AROperationType_Rsp 1;
BA_ "U_CD4_MY13_Hev_Rx" SG_ 486 ACU_AROperationType_Rsp 1;
BA_ "U_CD4_MY13_Phev_Rx" SG_ 486 ACU_AROperationType_Rsp 1;
BA_ "U_CD42_MY14_Diesel_Rx" SG_ 486 ACU_AROperationType_Rsp 1;
BA_ "U_CD42_MY14_Gas_Rx" SG_ 486 ACU_AROperationType_Rsp 1;
BA_ "U_P552_MY15_Gas_Rx" SG_ 486 ACU_AROperationType_Rsp 1;
BA_ "U_S550_MY15_Gas_Rx" SG_ 486 ACU_AROperationType_Rsp 1;
BA_ "U_C489_MY14_Gas_Rx" SG_ 486 ACU_AROperationType_Rsp 1;
BA_ "U_U502_MY15_Gas_Rx" SG_ 486 ACU_AROperationType_Rsp 1;
BA_ "U_UP375_MY15_Gas_Rx" SG_ 486 ACU_AROperationType_Rsp 1;
BA_ "U_UP375_MY15_Diesel_Rx" SG_ 486 ACU_AROperationType_Rsp 1;
BA_ "U_CD43_MY16_Gas_Rx" SG_ 486 ACU_AROperationType_Rsp 1;
BA_ "CrossOver_InfoCAN" SG_ 486 ACU_ARReqstrSystem_Rsp 1;
BA_ "U_CD4_MY13_Diesel_Rx" SG_ 486 ACU_ARReqstrSystem_Rsp 1;
BA_ "U_CD4_MY13_Gas_Rx" SG_ 486 ACU_ARReqstrSystem_Rsp 1;
BA_ "U_CD4_MY13_Hev_Rx" SG_ 486 ACU_ARReqstrSystem_Rsp 1;
BA_ "U_CD4_MY13_Phev_Rx" SG_ 486 ACU_ARReqstrSystem_Rsp 1;
BA_ "U_CD42_MY14_Diesel_Rx" SG_ 486 ACU_ARReqstrSystem_Rsp 1;
BA_ "U_CD42_MY14_Gas_Rx" SG_ 486 ACU_ARReqstrSystem_Rsp 1;
BA_ "U_P552_MY15_Gas_Rx" SG_ 486 ACU_ARReqstrSystem_Rsp 1;
BA_ "U_S550_MY15_Gas_Rx" SG_ 486 ACU_ARReqstrSystem_Rsp 1;
BA_ "U_C489_MY14_Gas_Rx" SG_ 486 ACU_ARReqstrSystem_Rsp 1;
BA_ "U_U502_MY15_Gas_Rx" SG_ 486 ACU_ARReqstrSystem_Rsp 1;
BA_ "U_UP375_MY15_Gas_Rx" SG_ 486 ACU_ARReqstrSystem_Rsp 1;
BA_ "U_UP375_MY15_Diesel_Rx" SG_ 486 ACU_ARReqstrSystem_Rsp 1;
BA_ "U_CD43_MY16_Gas_Rx" SG_ 486 ACU_ARReqstrSystem_Rsp 1;
BA_ "CrossOver_InfoCAN" SG_ 486 ACU_ARResponse_Rsp 1;
BA_ "U_CD4_MY13_Diesel_Rx" SG_ 486 ACU_ARResponse_Rsp 1;
BA_ "U_CD4_MY13_Gas_Rx" SG_ 486 ACU_ARResponse_Rsp 1;
BA_ "U_CD4_MY13_Hev_Rx" SG_ 486 ACU_ARResponse_Rsp 1;
BA_ "U_CD4_MY13_Phev_Rx" SG_ 486 ACU_ARResponse_Rsp 1;
BA_ "U_CD42_MY14_Diesel_Rx" SG_ 486 ACU_ARResponse_Rsp 1;
BA_ "U_CD42_MY14_Gas_Rx" SG_ 486 ACU_ARResponse_Rsp 1;
BA_ "U_P552_MY15_Gas_Rx" SG_ 486 ACU_ARResponse_Rsp 1;
BA_ "U_S550_MY15_Gas_Rx" SG_ 486 ACU_ARResponse_Rsp 1;
BA_ "U_C489_MY14_Gas_Rx" SG_ 486 ACU_ARResponse_Rsp 1;
BA_ "U_U502_MY15_Gas_Rx" SG_ 486 ACU_ARResponse_Rsp 1;
BA_ "U_UP375_MY15_Gas_Rx" SG_ 486 ACU_ARResponse_Rsp 1;
BA_ "U_UP375_MY15_Diesel_Rx" SG_ 486 ACU_ARResponse_Rsp 1;
BA_ "U_CD43_MY16_Gas_Rx" SG_ 486 ACU_ARResponse_Rsp 1;
BA_ "CrossOver_InfoCAN" SG_ 486 ACU_ARReqstrPriority_Rp 1;
BA_ "U_CD4_MY13_Diesel_Rx" SG_ 486 ACU_ARReqstrPriority_Rp 1;
BA_ "U_CD4_MY13_Gas_Rx" SG_ 486 ACU_ARReqstrPriority_Rp 1;
BA_ "U_CD4_MY13_Hev_Rx" SG_ 486 ACU_ARReqstrPriority_Rp 1;
BA_ "U_CD4_MY13_Phev_Rx" SG_ 486 ACU_ARReqstrPriority_Rp 1;
BA_ "U_CD42_MY14_Diesel_Rx" SG_ 486 ACU_ARReqstrPriority_Rp 1;
BA_ "U_CD42_MY14_Gas_Rx" SG_ 486 ACU_ARReqstrPriority_Rp 1;
BA_ "U_P552_MY15_Gas_Rx" SG_ 486 ACU_ARReqstrPriority_Rp 1;
BA_ "U_S550_MY15_Gas_Rx" SG_ 486 ACU_ARReqstrPriority_Rp 1;
BA_ "U_C489_MY14_Gas_Rx" SG_ 486 ACU_ARReqstrPriority_Rp 1;
BA_ "U_U502_MY15_Gas_Rx" SG_ 486 ACU_ARReqstrPriority_Rp 1;
BA_ "U_UP375_MY15_Gas_Rx" SG_ 486 ACU_ARReqstrPriority_Rp 1;
BA_ "U_UP375_MY15_Diesel_Rx" SG_ 486 ACU_ARReqstrPriority_Rp 1;
BA_ "U_CD43_MY16_Gas_Rx" SG_ 486 ACU_ARReqstrPriority_Rp 1;
BA_ "CrossOver_InfoCAN" SG_ 486 ACU_RUAudioSource_St 1;
BA_ "U_CD4_MY13_Diesel_Rx" SG_ 486 ACU_RUAudioSource_St 1;
BA_ "U_CD4_MY13_Gas_Rx" SG_ 486 ACU_RUAudioSource_St 1;
BA_ "U_CD4_MY13_Hev_Rx" SG_ 486 ACU_RUAudioSource_St 1;
BA_ "U_CD4_MY13_Phev_Rx" SG_ 486 ACU_RUAudioSource_St 1;
BA_ "U_CD42_MY14_Diesel_Rx" SG_ 486 ACU_RUAudioSource_St 1;
BA_ "U_CD42_MY14_Gas_Rx" SG_ 486 ACU_RUAudioSource_St 1;
BA_ "U_P552_MY15_Gas_Rx" SG_ 486 ACU_RUAudioSource_St 1;
BA_ "U_S550_MY15_Gas_Rx" SG_ 486 ACU_RUAudioSource_St 1;
BA_ "U_C489_MY14_Gas_Rx" SG_ 486 ACU_RUAudioSource_St 1;
BA_ "U_U502_MY15_Gas_Rx" SG_ 486 ACU_RUAudioSource_St 1;
BA_ "U_UP375_MY15_Gas_Rx" SG_ 486 ACU_RUAudioSource_St 1;
BA_ "U_UP375_MY15_Diesel_Rx" SG_ 486 ACU_RUAudioSource_St 1;
BA_ "U_CD43_MY16_Gas_Rx" SG_ 486 ACU_RUAudioSource_St 1;
BA_ "CrossOver_InfoCAN" SG_ 486 ACU_RUReqstrSystem_St 1;
BA_ "U_CD4_MY13_Diesel_Rx" SG_ 486 ACU_RUReqstrSystem_St 1;
BA_ "U_CD4_MY13_Gas_Rx" SG_ 486 ACU_RUReqstrSystem_St 1;
BA_ "U_CD4_MY13_Hev_Rx" SG_ 486 ACU_RUReqstrSystem_St 1;
BA_ "U_CD4_MY13_Phev_Rx" SG_ 486 ACU_RUReqstrSystem_St 1;
BA_ "U_CD42_MY14_Diesel_Rx" SG_ 486 ACU_RUReqstrSystem_St 1;
BA_ "U_CD42_MY14_Gas_Rx" SG_ 486 ACU_RUReqstrSystem_St 1;
BA_ "U_P552_MY15_Gas_Rx" SG_ 486 ACU_RUReqstrSystem_St 1;
BA_ "U_S550_MY15_Gas_Rx" SG_ 486 ACU_RUReqstrSystem_St 1;
BA_ "U_C489_MY14_Gas_Rx" SG_ 486 ACU_RUReqstrSystem_St 1;
BA_ "U_U502_MY15_Gas_Rx" SG_ 486 ACU_RUReqstrSystem_St 1;
BA_ "U_UP375_MY15_Gas_Rx" SG_ 486 ACU_RUReqstrSystem_St 1;
BA_ "U_UP375_MY15_Diesel_Rx" SG_ 486 ACU_RUReqstrSystem_St 1;
BA_ "U_CD43_MY16_Gas_Rx" SG_ 486 ACU_RUReqstrSystem_St 1;
BA_ "CrossOver_InfoCAN" SG_ 486 ACU_RUResReqstStatus_St 1;
BA_ "U_CD4_MY13_Diesel_Rx" SG_ 486 ACU_RUResReqstStatus_St 1;
BA_ "U_CD4_MY13_Gas_Rx" SG_ 486 ACU_RUResReqstStatus_St 1;
BA_ "U_CD4_MY13_Hev_Rx" SG_ 486 ACU_RUResReqstStatus_St 1;
BA_ "U_CD4_MY13_Phev_Rx" SG_ 486 ACU_RUResReqstStatus_St 1;
BA_ "U_CD42_MY14_Diesel_Rx" SG_ 486 ACU_RUResReqstStatus_St 1;
BA_ "U_CD42_MY14_Gas_Rx" SG_ 486 ACU_RUResReqstStatus_St 1;
BA_ "U_P552_MY15_Gas_Rx" SG_ 486 ACU_RUResReqstStatus_St 1;
BA_ "U_S550_MY15_Gas_Rx" SG_ 486 ACU_RUResReqstStatus_St 1;
BA_ "U_C489_MY14_Gas_Rx" SG_ 486 ACU_RUResReqstStatus_St 1;
BA_ "U_U502_MY15_Gas_Rx" SG_ 486 ACU_RUResReqstStatus_St 1;
BA_ "U_UP375_MY15_Gas_Rx" SG_ 486 ACU_RUResReqstStatus_St 1;
BA_ "U_UP375_MY15_Diesel_Rx" SG_ 486 ACU_RUResReqstStatus_St 1;
BA_ "U_CD43_MY16_Gas_Rx" SG_ 486 ACU_RUResReqstStatus_St 1;
BA_ "CrossOver_InfoCAN" SG_ 486 ACU_RUReqstrPriority_St 1;
BA_ "U_CD4_MY13_Diesel_Rx" SG_ 486 ACU_RUReqstrPriority_St 1;
BA_ "U_CD4_MY13_Gas_Rx" SG_ 486 ACU_RUReqstrPriority_St 1;
BA_ "U_CD4_MY13_Hev_Rx" SG_ 486 ACU_RUReqstrPriority_St 1;
BA_ "U_CD4_MY13_Phev_Rx" SG_ 486 ACU_RUReqstrPriority_St 1;
BA_ "U_CD42_MY14_Diesel_Rx" SG_ 486 ACU_RUReqstrPriority_St 1;
BA_ "U_CD42_MY14_Gas_Rx" SG_ 486 ACU_RUReqstrPriority_St 1;
BA_ "U_P552_MY15_Gas_Rx" SG_ 486 ACU_RUReqstrPriority_St 1;
BA_ "U_S550_MY15_Gas_Rx" SG_ 486 ACU_RUReqstrPriority_St 1;
BA_ "U_C489_MY14_Gas_Rx" SG_ 486 ACU_RUReqstrPriority_St 1;
BA_ "U_U502_MY15_Gas_Rx" SG_ 486 ACU_RUReqstrPriority_St 1;
BA_ "U_UP375_MY15_Gas_Rx" SG_ 486 ACU_RUReqstrPriority_St 1;
BA_ "U_UP375_MY15_Diesel_Rx" SG_ 486 ACU_RUReqstrPriority_St 1;
BA_ "U_CD43_MY16_Gas_Rx" SG_ 486 ACU_RUReqstrPriority_St 1;
BA_ "CrossOver_InfoCAN" SG_ 359 ElPw_D_StatStrtStop 1;
BA_ "CrossOver_InfoCAN" SG_ 359 TrnAin_Tq_Actl 1;
BA_ "ContentDependant" SG_ 359 TrnAin_Tq_Actl 1;
BA_ "CrossOver_InfoCAN" SG_ 359 PrplWhlTot2_Tq_Actl 1;
BA_ "CrossOver_InfoCAN" SG_ 359 TrnAinTq_D_Qf 1;
BA_ "ContentDependant" SG_ 359 TrnAinTq_D_Qf 1;
BA_ "CrossOver_InfoCAN" SG_ 359 PwPckTq_D_Stat 1;
BA_ "U_CD4_MY13_Diesel_Rx" SG_ 359 PwPckTq_D_Stat 1;
BA_ "U_CD4_MY13_Gas_Rx" SG_ 359 PwPckTq_D_Stat 1;
BA_ "U_CD4_MY13_Hev_Rx" SG_ 359 PwPckTq_D_Stat 1;
BA_ "U_CD4_MY13_Phev_Rx" SG_ 359 PwPckTq_D_Stat 1;
BA_ "U_CD42_MY14_Diesel_Rx" SG_ 359 PwPckTq_D_Stat 1;
BA_ "U_CD42_MY14_Gas_Rx" SG_ 359 PwPckTq_D_Stat 1;
BA_ "U_P552_MY15_Gas_Rx" SG_ 359 PwPckTq_D_Stat 1;
BA_ "U_S550_MY15_Gas_Rx" SG_ 359 PwPckTq_D_Stat 1;
BA_ "U_C489_MY14_Gas_Rx" SG_ 359 PwPckTq_D_Stat 1;
BA_ "U_U502_MY15_Gas_Rx" SG_ 359 PwPckTq_D_Stat 1;
BA_ "U_UP375_MY15_Gas_Rx" SG_ 359 PwPckTq_D_Stat 1;
BA_ "U_UP375_MY15_Diesel_Rx" SG_ 359 PwPckTq_D_Stat 1;
BA_ "U_CD43_MY16_Gas_Rx" SG_ 359 PwPckTq_D_Stat 1;
BA_ "U_CD4_MY14_Diesel_Rx" SG_ 359 PwPckTq_D_Stat 1;
BA_ "U_CD4_MY14_Gas_Rx" SG_ 359 PwPckTq_D_Stat 1;
BA_ "U_CD4_MY14_Hev_Rx" SG_ 359 PwPckTq_D_Stat 1;
BA_ "U_CD4_MY14_Phev_Rx" SG_ 359 PwPckTq_D_Stat 1;
BA_ "CrossOver_InfoCAN" SG_ 359 Eng_D_Stat 1;
BA_ "U_CD4_MY13_Diesel_Rx" SG_ 359 Eng_D_Stat 1;
BA_ "U_CD4_MY13_Gas_Rx" SG_ 359 Eng_D_Stat 1;
BA_ "U_CD4_MY13_Hev_Rx" SG_ 359 Eng_D_Stat 1;
BA_ "U_CD4_MY13_Phev_Rx" SG_ 359 Eng_D_Stat 1;
BA_ "U_CD42_MY14_Diesel_Rx" SG_ 359 Eng_D_Stat 1;
BA_ "U_CD42_MY14_Gas_Rx" SG_ 359 Eng_D_Stat 1;
BA_ "U_P552_MY15_Gas_Rx" SG_ 359 Eng_D_Stat 1;
BA_ "U_S550_MY15_Gas_Rx" SG_ 359 Eng_D_Stat 1;
BA_ "U_C489_MY14_Gas_Rx" SG_ 359 Eng_D_Stat 1;
BA_ "U_U502_MY15_Gas_Rx" SG_ 359 Eng_D_Stat 1;
BA_ "U_UP375_MY15_Gas_Rx" SG_ 359 Eng_D_Stat 1;
BA_ "U_UP375_MY15_Diesel_Rx" SG_ 359 Eng_D_Stat 1;
BA_ "U_CD43_MY16_Gas_Rx" SG_ 359 Eng_D_Stat 1;
BA_ "CrossOver_InfoCAN" SG_ 359 ElPw_D_Stat 1;
BA_ "U_CD4_MY13_Diesel_Rx" SG_ 359 ElPw_D_Stat 1;
BA_ "U_CD4_MY13_Gas_Rx" SG_ 359 ElPw_D_Stat 1;
BA_ "U_CD4_MY13_Hev_Rx" SG_ 359 ElPw_D_Stat 1;
BA_ "U_CD4_MY13_Phev_Rx" SG_ 359 ElPw_D_Stat 1;
BA_ "U_CD42_MY14_Diesel_Rx" SG_ 359 ElPw_D_Stat 1;
BA_ "U_CD42_MY14_Gas_Rx" SG_ 359 ElPw_D_Stat 1;
BA_ "U_P552_MY15_Gas_Rx" SG_ 359 ElPw_D_Stat 1;
BA_ "U_S550_MY15_Gas_Rx" SG_ 359 ElPw_D_Stat 1;
BA_ "U_U502_MY15_Gas_Rx" SG_ 359 ElPw_D_Stat 1;
BA_ "U_UP375_MY15_Gas_Rx" SG_ 359 ElPw_D_Stat 1;
BA_ "U_UP375_MY15_Diesel_Rx" SG_ 359 ElPw_D_Stat 1;
BA_ "U_CD43_MY16_Gas_Rx" SG_ 359 ElPw_D_Stat 1;
BA_ "U_CD4_MY14_Diesel_Rx" SG_ 359 ElPw_D_Stat 1;
BA_ "U_CD4_MY14_Gas_Rx" SG_ 359 ElPw_D_Stat 1;
BA_ "U_CD4_MY14_Hev_Rx" SG_ 359 ElPw_D_Stat 1;
BA_ "U_CD4_MY14_Phev_Rx" SG_ 359 ElPw_D_Stat 1;
BA_ "U_CD4_MY13_Diesel_Rx" SG_ 131 VehYaw_W_Actl_UB 1;
BA_ "U_CD4_MY13_Gas_Rx" SG_ 131 VehYaw_W_Actl_UB 1;
BA_ "U_CD4_MY13_Hev_Rx" SG_ 131 VehYaw_W_Actl_UB 1;
BA_ "U_CD4_MY13_Phev_Rx" SG_ 131 VehYaw_W_Actl_UB 1;
BA_ "U_CD42_MY14_Diesel_Rx" SG_ 131 VehYaw_W_Actl_UB 1;
BA_ "U_CD42_MY14_Gas_Rx" SG_ 131 VehYaw_W_Actl_UB 1;
BA_ "U_P552_MY15_Gas_Rx" SG_ 131 VehYaw_W_Actl_UB 1;
BA_ "U_S550_MY15_Gas_Rx" SG_ 131 VehYaw_W_Actl_UB 1;
BA_ "U_C489_MY14_Gas_Rx" SG_ 131 VehYaw_W_Actl_UB 1;
BA_ "U_U502_MY15_Gas_Rx" SG_ 131 VehYaw_W_Actl_UB 1;
BA_ "U_UP375_MY15_Gas_Rx" SG_ 131 VehYaw_W_Actl_UB 1;
BA_ "U_UP375_MY15_Diesel_Rx" SG_ 131 VehYaw_W_Actl_UB 1;
BA_ "U_CD43_MY16_Gas_Rx" SG_ 131 VehYaw_W_Actl_UB 1;
BA_ "GenSigStartValue" SG_ 131 VehYaw_W_Actl 65534;
BA_ "U_CD4_MY13_Diesel_Rx" SG_ 131 VehYaw_W_Actl 1;
BA_ "U_CD4_MY13_Gas_Rx" SG_ 131 VehYaw_W_Actl 1;
BA_ "U_CD4_MY13_Hev_Rx" SG_ 131 VehYaw_W_Actl 1;
BA_ "U_CD4_MY13_Phev_Rx" SG_ 131 VehYaw_W_Actl 1;
BA_ "U_CD42_MY14_Diesel_Rx" SG_ 131 VehYaw_W_Actl 1;
BA_ "U_CD42_MY14_Gas_Rx" SG_ 131 VehYaw_W_Actl 1;
BA_ "U_P552_MY15_Gas_Rx" SG_ 131 VehYaw_W_Actl 1;
BA_ "U_S550_MY15_Gas_Rx" SG_ 131 VehYaw_W_Actl 1;
BA_ "U_C489_MY14_Gas_Rx" SG_ 131 VehYaw_W_Actl 1;
BA_ "U_U502_MY15_Gas_Rx" SG_ 131 VehYaw_W_Actl 1;
BA_ "U_UP375_MY15_Gas_Rx" SG_ 131 VehYaw_W_Actl 1;
BA_ "U_UP375_MY15_Diesel_Rx" SG_ 131 VehYaw_W_Actl 1;
BA_ "U_CD43_MY16_Gas_Rx" SG_ 131 VehYaw_W_Actl 1;
BA_ "CrossOver_InfoCAN" SG_ 990 FeatNoDdm_No_Actl 1;
BA_ "GenSigSendType" SG_ 990 FeatNoDdm_No_Actl 3;
BA_ "U_CD4_MY13_Diesel_Tx" SG_ 990 FeatNoDdm_No_Actl 1;
BA_ "U_CD4_MY13_Gas_Tx" SG_ 990 FeatNoDdm_No_Actl 1;
BA_ "U_CD4_MY13_Hev_Tx" SG_ 990 FeatNoDdm_No_Actl 1;
BA_ "U_CD4_MY13_Phev_Tx" SG_ 990 FeatNoDdm_No_Actl 1;
BA_ "U_CD42_MY14_Diesel_Tx" SG_ 990 FeatNoDdm_No_Actl 1;
BA_ "U_CD42_MY14_Gas_Tx" SG_ 990 FeatNoDdm_No_Actl 1;
BA_ "U_P552_MY15_Gas_Tx" SG_ 990 FeatNoDdm_No_Actl 1;
BA_ "U_S550_MY15_Gas_Tx" SG_ 990 FeatNoDdm_No_Actl 1;
BA_ "U_C489_MY14_Gas_Tx" SG_ 990 FeatNoDdm_No_Actl 1;
BA_ "U_U502_MY15_Gas_Tx" SG_ 990 FeatNoDdm_No_Actl 1;
BA_ "U_UP375_MY15_Gas_Tx" SG_ 990 FeatNoDdm_No_Actl 1;
BA_ "U_UP375_MY15_Diesel_Tx" SG_ 990 FeatNoDdm_No_Actl 1;
BA_ "U_CD43_MY16_Gas_Tx" SG_ 990 FeatNoDdm_No_Actl 1;
BA_ "U_CD4_MY14_Diesel_Tx" SG_ 990 FeatNoDdm_No_Actl 1;
BA_ "U_CD4_MY14_Gas_Tx" SG_ 990 FeatNoDdm_No_Actl 1;
BA_ "U_CD4_MY14_Hev_Tx" SG_ 990 FeatNoDdm_No_Actl 1;
BA_ "U_CD4_MY14_Phev_Tx" SG_ 990 FeatNoDdm_No_Actl 1;
BA_ "CrossOver_InfoCAN" SG_ 990 FeatConfigDdmActl 1;
BA_ "GenSigSendType" SG_ 990 FeatConfigDdmActl 3;
BA_ "U_CD4_MY13_Diesel_Tx" SG_ 990 FeatConfigDdmActl 1;
BA_ "U_CD4_MY13_Gas_Tx" SG_ 990 FeatConfigDdmActl 1;
BA_ "U_CD4_MY13_Hev_Tx" SG_ 990 FeatConfigDdmActl 1;
BA_ "U_CD4_MY13_Phev_Tx" SG_ 990 FeatConfigDdmActl 1;
BA_ "U_CD42_MY14_Diesel_Tx" SG_ 990 FeatConfigDdmActl 1;
BA_ "U_CD42_MY14_Gas_Tx" SG_ 990 FeatConfigDdmActl 1;
BA_ "U_P552_MY15_Gas_Tx" SG_ 990 FeatConfigDdmActl 1;
BA_ "U_S550_MY15_Gas_Tx" SG_ 990 FeatConfigDdmActl 1;
BA_ "U_C489_MY14_Gas_Tx" SG_ 990 FeatConfigDdmActl 1;
BA_ "U_U502_MY15_Gas_Tx" SG_ 990 FeatConfigDdmActl 1;
BA_ "U_UP375_MY15_Gas_Tx" SG_ 990 FeatConfigDdmActl 1;
BA_ "U_UP375_MY15_Diesel_Tx" SG_ 990 FeatConfigDdmActl 1;
BA_ "U_CD43_MY16_Gas_Tx" SG_ 990 FeatConfigDdmActl 1;
BA_ "U_CD4_MY14_Diesel_Tx" SG_ 990 FeatConfigDdmActl 1;
BA_ "U_CD4_MY14_Gas_Tx" SG_ 990 FeatConfigDdmActl 1;
BA_ "U_CD4_MY14_Hev_Tx" SG_ 990 FeatConfigDdmActl 1;
BA_ "U_CD4_MY14_Phev_Tx" SG_ 990 FeatConfigDdmActl 1;
BA_ "U_U55x_MY18_Gas_Rx" SG_ 1003 PersRecallSrc_D_Actl 1;
BA_ "CrossOver_InfoCAN" SG_ 1003 PersSetupRestr_D_Actl 1;
BA_ "U_CD4_MY13_Diesel_Rx" SG_ 1003 PersSetupRestr_D_Actl 1;
BA_ "U_CD4_MY13_Gas_Rx" SG_ 1003 PersSetupRestr_D_Actl 1;
BA_ "U_CD4_MY13_Hev_Rx" SG_ 1003 PersSetupRestr_D_Actl 1;
BA_ "U_CD4_MY13_Phev_Rx" SG_ 1003 PersSetupRestr_D_Actl 1;
BA_ "U_CD42_MY14_Diesel_Rx" SG_ 1003 PersSetupRestr_D_Actl 1;
BA_ "U_CD42_MY14_Gas_Rx" SG_ 1003 PersSetupRestr_D_Actl 1;
BA_ "U_P552_MY15_Gas_Rx" SG_ 1003 PersSetupRestr_D_Actl 1;
BA_ "U_S550_MY15_Gas_Rx" SG_ 1003 PersSetupRestr_D_Actl 1;
BA_ "U_C489_MY14_Gas_Rx" SG_ 1003 PersSetupRestr_D_Actl 1;
BA_ "U_U502_MY15_Gas_Rx" SG_ 1003 PersSetupRestr_D_Actl 1;
BA_ "U_UP375_MY15_Gas_Rx" SG_ 1003 PersSetupRestr_D_Actl 1;
BA_ "U_UP375_MY15_Diesel_Rx" SG_ 1003 PersSetupRestr_D_Actl 1;
BA_ "U_CD43_MY16_Gas_Rx" SG_ 1003 PersSetupRestr_D_Actl 1;
BA_ "U_CD4_MY14_Diesel_Rx" SG_ 1003 PersSetupRestr_D_Actl 1;
BA_ "U_CD4_MY14_Gas_Rx" SG_ 1003 PersSetupRestr_D_Actl 1;
BA_ "U_CD4_MY14_Hev_Rx" SG_ 1003 PersSetupRestr_D_Actl 1;
BA_ "U_CD4_MY14_Phev_Rx" SG_ 1003 PersSetupRestr_D_Actl 1;
BA_ "CrossOver_InfoCAN" SG_ 1003 PersSetupAccessCtrl 1;
BA_ "U_CD4_MY13_Diesel_Rx" SG_ 1003 PersSetupAccessCtrl 1;
BA_ "U_CD4_MY13_Gas_Rx" SG_ 1003 PersSetupAccessCtrl 1;
BA_ "U_CD4_MY13_Hev_Rx" SG_ 1003 PersSetupAccessCtrl 1;
BA_ "U_CD4_MY13_Phev_Rx" SG_ 1003 PersSetupAccessCtrl 1;
BA_ "U_CD42_MY14_Diesel_Rx" SG_ 1003 PersSetupAccessCtrl 1;
BA_ "U_CD42_MY14_Gas_Rx" SG_ 1003 PersSetupAccessCtrl 1;
BA_ "U_P552_MY15_Gas_Rx" SG_ 1003 PersSetupAccessCtrl 1;
BA_ "U_S550_MY15_Gas_Rx" SG_ 1003 PersSetupAccessCtrl 1;
BA_ "U_C489_MY14_Gas_Rx" SG_ 1003 PersSetupAccessCtrl 1;
BA_ "U_U502_MY15_Gas_Rx" SG_ 1003 PersSetupAccessCtrl 1;
BA_ "U_UP375_MY15_Gas_Rx" SG_ 1003 PersSetupAccessCtrl 1;
BA_ "U_UP375_MY15_Diesel_Rx" SG_ 1003 PersSetupAccessCtrl 1;
BA_ "U_CD43_MY16_Gas_Rx" SG_ 1003 PersSetupAccessCtrl 1;
BA_ "U_CD4_MY14_Diesel_Rx" SG_ 1003 PersSetupAccessCtrl 1;
BA_ "U_CD4_MY14_Gas_Rx" SG_ 1003 PersSetupAccessCtrl 1;
BA_ "U_CD4_MY14_Hev_Rx" SG_ 1003 PersSetupAccessCtrl 1;
BA_ "U_CD4_MY14_Phev_Rx" SG_ 1003 PersSetupAccessCtrl 1;
BA_ "CrossOver_InfoCAN" SG_ 1003 PersSetup_No_Actl 1;
BA_ "U_CD4_MY13_Diesel_Rx" SG_ 1003 PersSetup_No_Actl 1;
BA_ "U_CD4_MY13_Gas_Rx" SG_ 1003 PersSetup_No_Actl 1;
BA_ "U_CD4_MY13_Hev_Rx" SG_ 1003 PersSetup_No_Actl 1;
BA_ "U_CD4_MY13_Phev_Rx" SG_ 1003 PersSetup_No_Actl 1;
BA_ "U_CD42_MY14_Diesel_Rx" SG_ 1003 PersSetup_No_Actl 1;
BA_ "U_CD42_MY14_Gas_Rx" SG_ 1003 PersSetup_No_Actl 1;
BA_ "U_P552_MY15_Gas_Rx" SG_ 1003 PersSetup_No_Actl 1;
BA_ "U_S550_MY15_Gas_Rx" SG_ 1003 PersSetup_No_Actl 1;
BA_ "U_C489_MY14_Gas_Rx" SG_ 1003 PersSetup_No_Actl 1;
BA_ "U_U502_MY15_Gas_Rx" SG_ 1003 PersSetup_No_Actl 1;
BA_ "U_UP375_MY15_Gas_Rx" SG_ 1003 PersSetup_No_Actl 1;
BA_ "U_UP375_MY15_Diesel_Rx" SG_ 1003 PersSetup_No_Actl 1;
BA_ "U_CD43_MY16_Gas_Rx" SG_ 1003 PersSetup_No_Actl 1;
BA_ "U_CD4_MY14_Diesel_Rx" SG_ 1003 PersSetup_No_Actl 1;
BA_ "U_CD4_MY14_Gas_Rx" SG_ 1003 PersSetup_No_Actl 1;
BA_ "U_CD4_MY14_Hev_Rx" SG_ 1003 PersSetup_No_Actl 1;
BA_ "U_CD4_MY14_Phev_Rx" SG_ 1003 PersSetup_No_Actl 1;
BA_ "CrossOver_InfoCAN" SG_ 1003 PersConflict_D_Actl 1;
BA_ "GenSigStartValue" SG_ 1003 PersConflict_D_Actl 1;
BA_ "CrossOver_InfoCAN" SG_ 1003 AssocConfirm_D_Actl 1;
BA_ "CrossOver_InfoCAN" SG_ 1003 RecallEvent_No_Cnt 1;
BA_ "U_CD4_MY13_Diesel_Rx" SG_ 1003 RecallEvent_No_Cnt 1;
BA_ "U_CD4_MY13_Gas_Rx" SG_ 1003 RecallEvent_No_Cnt 1;
BA_ "U_CD4_MY13_Hev_Rx" SG_ 1003 RecallEvent_No_Cnt 1;
BA_ "U_CD4_MY13_Phev_Rx" SG_ 1003 RecallEvent_No_Cnt 1;
BA_ "U_CD42_MY14_Diesel_Rx" SG_ 1003 RecallEvent_No_Cnt 1;
BA_ "U_CD42_MY14_Gas_Rx" SG_ 1003 RecallEvent_No_Cnt 1;
BA_ "U_P552_MY15_Gas_Rx" SG_ 1003 RecallEvent_No_Cnt 1;
BA_ "U_S550_MY15_Gas_Rx" SG_ 1003 RecallEvent_No_Cnt 1;
BA_ "U_U502_MY15_Gas_Rx" SG_ 1003 RecallEvent_No_Cnt 1;
BA_ "U_UP375_MY15_Gas_Rx" SG_ 1003 RecallEvent_No_Cnt 1;
BA_ "U_UP375_MY15_Diesel_Rx" SG_ 1003 RecallEvent_No_Cnt 1;
BA_ "U_CD43_MY16_Gas_Rx" SG_ 1003 RecallEvent_No_Cnt 1;
BA_ "U_CD4_MY14_Diesel_Rx" SG_ 1003 RecallEvent_No_Cnt 1;
BA_ "U_CD4_MY14_Gas_Rx" SG_ 1003 RecallEvent_No_Cnt 1;
BA_ "U_CD4_MY14_Hev_Rx" SG_ 1003 RecallEvent_No_Cnt 1;
BA_ "U_CD4_MY14_Phev_Rx" SG_ 1003 RecallEvent_No_Cnt 1;
BA_ "CrossOver_InfoCAN" SG_ 1003 PersNo_D_Actl 1;
BA_ "GenSigStartValue" SG_ 1003 PersNo_D_Actl 4;
BA_ "U_CD4_MY13_Diesel_Rx" SG_ 1003 PersNo_D_Actl 1;
BA_ "U_CD4_MY13_Gas_Rx" SG_ 1003 PersNo_D_Actl 1;
BA_ "U_CD4_MY13_Hev_Rx" SG_ 1003 PersNo_D_Actl 1;
BA_ "U_CD4_MY13_Phev_Rx" SG_ 1003 PersNo_D_Actl 1;
BA_ "U_CD42_MY14_Diesel_Rx" SG_ 1003 PersNo_D_Actl 1;
BA_ "U_CD42_MY14_Gas_Rx" SG_ 1003 PersNo_D_Actl 1;
BA_ "U_P552_MY15_Gas_Rx" SG_ 1003 PersNo_D_Actl 1;
BA_ "U_C489_MY14_Gas_Rx" SG_ 1003 PersNo_D_Actl 1;
BA_ "U_U502_MY15_Gas_Rx" SG_ 1003 PersNo_D_Actl 1;
BA_ "U_CD43_MY16_Gas_Rx" SG_ 1003 PersNo_D_Actl 1;
BA_ "U_S550_MY15_Gas_Rx" SG_ 1003 PersNo_D_Actl 1;
BA_ "U_UP375_MY15_Gas_Rx" SG_ 1003 PersNo_D_Actl 1;
BA_ "U_UP375_MY15_Diesel_Rx" SG_ 1003 PersNo_D_Actl 1;
BA_ "U_CD4_MY14_Diesel_Rx" SG_ 1003 PersNo_D_Actl 1;
BA_ "U_CD4_MY14_Gas_Rx" SG_ 1003 PersNo_D_Actl 1;
BA_ "U_CD4_MY14_Hev_Rx" SG_ 1003 PersNo_D_Actl 1;
BA_ "U_CD4_MY14_Phev_Rx" SG_ 1003 PersNo_D_Actl 1;
BA_ "CrossOver_InfoCAN" SG_ 1003 PersNoPos_D_Actl 1;
BA_ "GenSigStartValue" SG_ 1003 PersNoPos_D_Actl 4;
BA_ "U_CD4_MY13_Diesel_Rx" SG_ 1003 PersNoPos_D_Actl 1;
BA_ "U_CD4_MY13_Gas_Rx" SG_ 1003 PersNoPos_D_Actl 1;
BA_ "U_CD4_MY13_Hev_Rx" SG_ 1003 PersNoPos_D_Actl 1;
BA_ "U_CD4_MY13_Phev_Rx" SG_ 1003 PersNoPos_D_Actl 1;
BA_ "U_CD42_MY14_Diesel_Rx" SG_ 1003 PersNoPos_D_Actl 1;
BA_ "U_CD42_MY14_Gas_Rx" SG_ 1003 PersNoPos_D_Actl 1;
BA_ "U_P552_MY15_Gas_Rx" SG_ 1003 PersNoPos_D_Actl 1;
BA_ "U_S550_MY15_Gas_Rx" SG_ 1003 PersNoPos_D_Actl 1;
BA_ "U_U502_MY15_Gas_Rx" SG_ 1003 PersNoPos_D_Actl 1;
BA_ "U_CD43_MY16_Gas_Rx" SG_ 1003 PersNoPos_D_Actl 1;
BA_ "GenSigSendType" SG_ 1945 TesterPhysicalResTRM 3;
BA_ "U_CD4_MY13_Diesel_Tx" SG_ 1945 TesterPhysicalResTRM 1;
BA_ "U_CD4_MY13_Gas_Tx" SG_ 1945 TesterPhysicalResTRM 1;
BA_ "U_CD4_MY13_Hev_Tx" SG_ 1945 TesterPhysicalResTRM 1;
BA_ "U_CD4_MY13_Phev_Tx" SG_ 1945 TesterPhysicalResTRM 1;
BA_ "U_CD42_MY14_Diesel_Tx" SG_ 1945 TesterPhysicalResTRM 1;
BA_ "U_CD42_MY14_Gas_Tx" SG_ 1945 TesterPhysicalResTRM 1;
BA_ "U_P552_MY15_Gas_Tx" SG_ 1945 TesterPhysicalResTRM 1;
BA_ "U_C489_MY14_Gas_Tx" SG_ 1945 TesterPhysicalResTRM 1;
BA_ "U_UP375_MY15_Gas_Tx" SG_ 1945 TesterPhysicalResTRM 1;
BA_ "U_UP375_MY15_Diesel_Tx" SG_ 1945 TesterPhysicalResTRM 1;
BA_ "WakeupSignal" SG_ 836 HvacPrecondMode_D_Rq 1;
BA_ "ContentDependant" SG_ 836 HvacPrecondMode_D_Rq 1;
BA_ "U_CD4_MY13_Diesel_Rx" SG_ 836 HvacPrecondMode_D_Rq 1;
BA_ "U_CD4_MY13_Gas_Rx" SG_ 836 HvacPrecondMode_D_Rq 1;
BA_ "U_CD4_MY13_Hev_Rx" SG_ 836 HvacPrecondMode_D_Rq 1;
BA_ "U_CD4_MY13_Phev_Rx" SG_ 836 HvacPrecondMode_D_Rq 1;
BA_ "U_CD42_MY14_Diesel_Rx" SG_ 836 HvacPrecondMode_D_Rq 1;
BA_ "U_CD42_MY14_Gas_Rx" SG_ 836 HvacPrecondMode_D_Rq 1;
BA_ "U_P552_MY15_Gas_Rx" SG_ 836 HvacPrecondMode_D_Rq 1;
BA_ "U_S550_MY15_Gas_Rx" SG_ 836 HvacPrecondMode_D_Rq 1;
BA_ "U_C489_MY14_Gas_Rx" SG_ 836 HvacPrecondMode_D_Rq 1;
BA_ "U_U502_MY15_Gas_Rx" SG_ 836 HvacPrecondMode_D_Rq 1;
BA_ "U_B479_MY15_Gas_Rx" SG_ 836 HvacPrecondMode_D_Rq 1;
BA_ "U_UP375_MY15_Gas_Rx" SG_ 836 HvacPrecondMode_D_Rq 1;
BA_ "U_UP375_MY15_Diesel_Rx" SG_ 836 HvacPrecondMode_D_Rq 1;
BA_ "WakeupSignal" SG_ 836 HvacPrecondBlwr_D_Rq 1;
BA_ "ContentDependant" SG_ 836 HvacPrecondBlwr_D_Rq 1;
BA_ "U_CD4_MY13_Diesel_Rx" SG_ 836 HvacPrecondBlwr_D_Rq 1;
BA_ "U_CD4_MY13_Gas_Rx" SG_ 836 HvacPrecondBlwr_D_Rq 1;
BA_ "U_CD4_MY13_Hev_Rx" SG_ 836 HvacPrecondBlwr_D_Rq 1;
BA_ "U_CD4_MY13_Phev_Rx" SG_ 836 HvacPrecondBlwr_D_Rq 1;
BA_ "U_CD42_MY14_Diesel_Rx" SG_ 836 HvacPrecondBlwr_D_Rq 1;
BA_ "U_CD42_MY14_Gas_Rx" SG_ 836 HvacPrecondBlwr_D_Rq 1;
BA_ "U_P552_MY15_Gas_Rx" SG_ 836 HvacPrecondBlwr_D_Rq 1;
BA_ "U_S550_MY15_Gas_Rx" SG_ 836 HvacPrecondBlwr_D_Rq 1;
BA_ "U_C489_MY14_Gas_Rx" SG_ 836 HvacPrecondBlwr_D_Rq 1;
BA_ "U_U502_MY15_Gas_Rx" SG_ 836 HvacPrecondBlwr_D_Rq 1;
BA_ "U_B479_MY15_Gas_Rx" SG_ 836 HvacPrecondBlwr_D_Rq 1;
BA_ "U_UP375_MY15_Gas_Rx" SG_ 836 HvacPrecondBlwr_D_Rq 1;
BA_ "U_UP375_MY15_Diesel_Rx" SG_ 836 HvacPrecondBlwr_D_Rq 1;
BA_ "WakeupSignal" SG_ 836 Foh_D_Stat 1;
BA_ "ContentDependant" SG_ 836 Foh_D_Stat 1;
BA_ "U_CD4_MY13_Diesel_Rx" SG_ 836 Foh_D_Stat 1;
BA_ "U_CD4_MY13_Gas_Rx" SG_ 836 Foh_D_Stat 1;
BA_ "U_CD4_MY13_Hev_Rx" SG_ 836 Foh_D_Stat 1;
BA_ "U_CD4_MY13_Phev_Rx" SG_ 836 Foh_D_Stat 1;
BA_ "U_CD42_MY14_Diesel_Rx" SG_ 836 Foh_D_Stat 1;
BA_ "U_CD42_MY14_Gas_Rx" SG_ 836 Foh_D_Stat 1;
BA_ "U_P552_MY15_Gas_Rx" SG_ 836 Foh_D_Stat 1;
BA_ "U_S550_MY15_Gas_Rx" SG_ 836 Foh_D_Stat 1;
BA_ "U_C489_MY14_Gas_Rx" SG_ 836 Foh_D_Stat 1;
BA_ "U_U502_MY15_Gas_Rx" SG_ 836 Foh_D_Stat 1;
BA_ "U_B479_MY15_Gas_Rx" SG_ 836 Foh_D_Stat 1;
BA_ "U_UP375_MY15_Gas_Rx" SG_ 836 Foh_D_Stat 1;
BA_ "U_UP375_MY15_Diesel_Rx" SG_ 836 Foh_D_Stat 1;
BA_ "GenSigSendType" SG_ 819 BLISLEDStatPassSide 3;
BA_ "U_CD4_MY13_Diesel_Rx" SG_ 819 BLISLEDStatPassSide 1;
BA_ "U_CD4_MY13_Gas_Rx" SG_ 819 BLISLEDStatPassSide 1;
BA_ "U_CD4_MY13_Hev_Rx" SG_ 819 BLISLEDStatPassSide 1;
BA_ "U_CD4_MY13_Phev_Rx" SG_ 819 BLISLEDStatPassSide 1;
BA_ "U_CD42_MY14_Diesel_Rx" SG_ 819 BLISLEDStatPassSide 1;
BA_ "U_CD42_MY14_Gas_Rx" SG_ 819 BLISLEDStatPassSide 1;
BA_ "U_P552_MY15_Gas_Rx" SG_ 819 BLISLEDStatPassSide 1;
BA_ "U_C489_MY14_Gas_Rx" SG_ 819 BLISLEDStatPassSide 1;
BA_ "U_B562LC_MY14_Gas_Rx" SG_ 819 BLISLEDStatPassSide 1;
BA_ "U_U502_MY15_Gas_Rx" SG_ 819 BLISLEDStatPassSide 1;
BA_ "U_UP375_MY15_Gas_Rx" SG_ 819 BLISLEDStatPassSide 1;
BA_ "U_UP375_MY15_Diesel_Rx" SG_ 819 BLISLEDStatPassSide 1;
BA_ "U_CD43_MY16_Gas_Rx" SG_ 819 BLISLEDStatPassSide 1;
BA_ "U_CD4_MY13_Diesel_Tx" SG_ 819 BLISLEDStatPassSide 1;
BA_ "U_CD4_MY13_Gas_Tx" SG_ 819 BLISLEDStatPassSide 1;
BA_ "U_CD4_MY13_Hev_Tx" SG_ 819 BLISLEDStatPassSide 1;
BA_ "U_CD4_MY13_Phev_Tx" SG_ 819 BLISLEDStatPassSide 1;
BA_ "U_CD42_MY14_Diesel_Tx" SG_ 819 BLISLEDStatPassSide 1;
BA_ "U_CD42_MY14_Gas_Tx" SG_ 819 BLISLEDStatPassSide 1;
BA_ "U_P552_MY15_Gas_Tx" SG_ 819 BLISLEDStatPassSide 1;
BA_ "U_S550_MY15_Gas_Tx" SG_ 819 BLISLEDStatPassSide 1;
BA_ "U_C489_MY14_Gas_Tx" SG_ 819 BLISLEDStatPassSide 1;
BA_ "U_U502_MY15_Gas_Tx" SG_ 819 BLISLEDStatPassSide 1;
BA_ "U_UP375_MY15_Gas_Tx" SG_ 819 BLISLEDStatPassSide 1;
BA_ "U_UP375_MY15_Diesel_Tx" SG_ 819 BLISLEDStatPassSide 1;
BA_ "U_CD43_MY16_Gas_Tx" SG_ 819 BLISLEDStatPassSide 1;
BA_ "U_CD4_MY14_Diesel_Tx" SG_ 819 BLISLEDStatPassSide 1;
BA_ "U_CD4_MY14_Gas_Tx" SG_ 819 BLISLEDStatPassSide 1;
BA_ "U_CD4_MY14_Hev_Tx" SG_ 819 BLISLEDStatPassSide 1;
BA_ "U_CD4_MY14_Phev_Tx" SG_ 819 BLISLEDStatPassSide 1;
BA_ "GenSigSendType" SG_ 819 WndwPsngrSide_D_Stat 3;
BA_ "U_CD4_MY13_Diesel_Tx" SG_ 819 WndwPsngrSide_D_Stat 1;
BA_ "U_CD4_MY13_Gas_Tx" SG_ 819 WndwPsngrSide_D_Stat 1;
BA_ "U_CD4_MY13_Hev_Tx" SG_ 819 WndwPsngrSide_D_Stat 1;
BA_ "U_CD4_MY13_Phev_Tx" SG_ 819 WndwPsngrSide_D_Stat 1;
BA_ "U_CD42_MY14_Diesel_Tx" SG_ 819 WndwPsngrSide_D_Stat 1;
BA_ "U_CD42_MY14_Gas_Tx" SG_ 819 WndwPsngrSide_D_Stat 1;
BA_ "U_P552_MY15_Gas_Tx" SG_ 819 WndwPsngrSide_D_Stat 1;
BA_ "U_S550_MY15_Gas_Tx" SG_ 819 WndwPsngrSide_D_Stat 1;
BA_ "U_C489_MY14_Gas_Tx" SG_ 819 WndwPsngrSide_D_Stat 1;
BA_ "U_U502_MY15_Gas_Tx" SG_ 819 WndwPsngrSide_D_Stat 1;
BA_ "U_UP375_MY15_Gas_Tx" SG_ 819 WndwPsngrSide_D_Stat 1;
BA_ "U_UP375_MY15_Diesel_Tx" SG_ 819 WndwPsngrSide_D_Stat 1;
BA_ "U_CD43_MY16_Gas_Tx" SG_ 819 WndwPsngrSide_D_Stat 1;
BA_ "U_CD4_MY14_Diesel_Tx" SG_ 819 WndwPsngrSide_D_Stat 1;
BA_ "U_CD4_MY14_Gas_Tx" SG_ 819 WndwPsngrSide_D_Stat 1;
BA_ "U_CD4_MY14_Hev_Tx" SG_ 819 WndwPsngrSide_D_Stat 1;
BA_ "U_CD4_MY14_Phev_Tx" SG_ 819 WndwPsngrSide_D_Stat 1;
BA_ "WakeupSignal" SG_ 819 Pasngr_Lock_Sw_Stat 1;
BA_ "GenSigSendType" SG_ 819 Pasngr_Lock_Sw_Stat 3;
BA_ "U_CD4_MY13_Diesel_Rx" SG_ 819 Pasngr_Lock_Sw_Stat 1;
BA_ "U_CD4_MY13_Gas_Rx" SG_ 819 Pasngr_Lock_Sw_Stat 1;
BA_ "U_CD4_MY13_Hev_Rx" SG_ 819 Pasngr_Lock_Sw_Stat 1;
BA_ "U_CD4_MY13_Phev_Rx" SG_ 819 Pasngr_Lock_Sw_Stat 1;
BA_ "U_CD42_MY14_Diesel_Rx" SG_ 819 Pasngr_Lock_Sw_Stat 1;
BA_ "U_CD42_MY14_Gas_Rx" SG_ 819 Pasngr_Lock_Sw_Stat 1;
BA_ "U_P552_MY15_Gas_Rx" SG_ 819 Pasngr_Lock_Sw_Stat 1;
BA_ "U_S550_MY15_Gas_Rx" SG_ 819 Pasngr_Lock_Sw_Stat 1;
BA_ "U_C489_MY14_Gas_Rx" SG_ 819 Pasngr_Lock_Sw_Stat 1;
BA_ "U_U502_MY15_Gas_Rx" SG_ 819 Pasngr_Lock_Sw_Stat 1;
BA_ "U_B479_MY15_Gas_Rx" SG_ 819 Pasngr_Lock_Sw_Stat 1;
BA_ "U_UP375_MY15_Gas_Rx" SG_ 819 Pasngr_Lock_Sw_Stat 1;
BA_ "U_UP375_MY15_Diesel_Rx" SG_ 819 Pasngr_Lock_Sw_Stat 1;
BA_ "U_CD4_MY13_Diesel_Tx" SG_ 819 Pasngr_Lock_Sw_Stat 1;
BA_ "U_CD4_MY13_Gas_Tx" SG_ 819 Pasngr_Lock_Sw_Stat 1;
BA_ "U_CD4_MY13_Hev_Tx" SG_ 819 Pasngr_Lock_Sw_Stat 1;
BA_ "U_CD4_MY13_Phev_Tx" SG_ 819 Pasngr_Lock_Sw_Stat 1;
BA_ "U_CD42_MY14_Diesel_Tx" SG_ 819 Pasngr_Lock_Sw_Stat 1;
BA_ "U_CD42_MY14_Gas_Tx" SG_ 819 Pasngr_Lock_Sw_Stat 1;
BA_ "U_P552_MY15_Gas_Tx" SG_ 819 Pasngr_Lock_Sw_Stat 1;
BA_ "U_S550_MY15_Gas_Tx" SG_ 819 Pasngr_Lock_Sw_Stat 1;
BA_ "U_C489_MY14_Gas_Tx" SG_ 819 Pasngr_Lock_Sw_Stat 1;
BA_ "U_U502_MY15_Gas_Tx" SG_ 819 Pasngr_Lock_Sw_Stat 1;
BA_ "U_UP375_MY15_Gas_Tx" SG_ 819 Pasngr_Lock_Sw_Stat 1;
BA_ "U_UP375_MY15_Diesel_Tx" SG_ 819 Pasngr_Lock_Sw_Stat 1;
BA_ "U_CD43_MY16_Gas_Tx" SG_ 819 Pasngr_Lock_Sw_Stat 1;
BA_ "U_CD4_MY14_Diesel_Tx" SG_ 819 Pasngr_Lock_Sw_Stat 1;
BA_ "U_CD4_MY14_Gas_Tx" SG_ 819 Pasngr_Lock_Sw_Stat 1;
BA_ "U_CD4_MY14_Hev_Tx" SG_ 819 Pasngr_Lock_Sw_Stat 1;
BA_ "U_CD4_MY14_Phev_Tx" SG_ 819 Pasngr_Lock_Sw_Stat 1;
BA_ "WakeupSignal" SG_ 819 Pasngr_Lock_Sw_Cnt 1;
BA_ "GenSigSendType" SG_ 819 Pasngr_Lock_Sw_Cnt 3;
BA_ "U_CD4_MY13_Diesel_Rx" SG_ 819 Pasngr_Lock_Sw_Cnt 1;
BA_ "U_CD4_MY13_Gas_Rx" SG_ 819 Pasngr_Lock_Sw_Cnt 1;
BA_ "U_CD4_MY13_Hev_Rx" SG_ 819 Pasngr_Lock_Sw_Cnt 1;
BA_ "U_CD4_MY13_Phev_Rx" SG_ 819 Pasngr_Lock_Sw_Cnt 1;
BA_ "U_CD42_MY14_Diesel_Rx" SG_ 819 Pasngr_Lock_Sw_Cnt 1;
BA_ "U_CD42_MY14_Gas_Rx" SG_ 819 Pasngr_Lock_Sw_Cnt 1;
BA_ "U_P552_MY15_Gas_Rx" SG_ 819 Pasngr_Lock_Sw_Cnt 1;
BA_ "U_S550_MY15_Gas_Rx" SG_ 819 Pasngr_Lock_Sw_Cnt 1;
BA_ "U_C489_MY14_Gas_Rx" SG_ 819 Pasngr_Lock_Sw_Cnt 1;
BA_ "U_U502_MY15_Gas_Rx" SG_ 819 Pasngr_Lock_Sw_Cnt 1;
BA_ "U_B479_MY15_Gas_Rx" SG_ 819 Pasngr_Lock_Sw_Cnt 1;
BA_ "U_UP375_MY15_Gas_Rx" SG_ 819 Pasngr_Lock_Sw_Cnt 1;
BA_ "U_UP375_MY15_Diesel_Rx" SG_ 819 Pasngr_Lock_Sw_Cnt 1;
BA_ "U_CD4_MY13_Diesel_Tx" SG_ 819 Pasngr_Lock_Sw_Cnt 1;
BA_ "U_CD4_MY13_Gas_Tx" SG_ 819 Pasngr_Lock_Sw_Cnt 1;
BA_ "U_CD4_MY13_Hev_Tx" SG_ 819 Pasngr_Lock_Sw_Cnt 1;
BA_ "U_CD4_MY13_Phev_Tx" SG_ 819 Pasngr_Lock_Sw_Cnt 1;
BA_ "U_CD42_MY14_Diesel_Tx" SG_ 819 Pasngr_Lock_Sw_Cnt 1;
BA_ "U_CD42_MY14_Gas_Tx" SG_ 819 Pasngr_Lock_Sw_Cnt 1;
BA_ "U_P552_MY15_Gas_Tx" SG_ 819 Pasngr_Lock_Sw_Cnt 1;
BA_ "U_S550_MY15_Gas_Tx" SG_ 819 Pasngr_Lock_Sw_Cnt 1;
BA_ "U_C489_MY14_Gas_Tx" SG_ 819 Pasngr_Lock_Sw_Cnt 1;
BA_ "U_U502_MY15_Gas_Tx" SG_ 819 Pasngr_Lock_Sw_Cnt 1;
BA_ "U_UP375_MY15_Gas_Tx" SG_ 819 Pasngr_Lock_Sw_Cnt 1;
BA_ "U_UP375_MY15_Diesel_Tx" SG_ 819 Pasngr_Lock_Sw_Cnt 1;
BA_ "U_CD43_MY16_Gas_Tx" SG_ 819 Pasngr_Lock_Sw_Cnt 1;
BA_ "U_CD4_MY14_Diesel_Tx" SG_ 819 Pasngr_Lock_Sw_Cnt 1;
BA_ "U_CD4_MY14_Gas_Tx" SG_ 819 Pasngr_Lock_Sw_Cnt 1;
BA_ "U_CD4_MY14_Hev_Tx" SG_ 819 Pasngr_Lock_Sw_Cnt 1;
BA_ "U_CD4_MY14_Phev_Tx" SG_ 819 Pasngr_Lock_Sw_Cnt 1;
BA_ "WakeupSignal" SG_ 819 ChildLckFdbckRp_B_Stat 1;
BA_ "GenSigSendType" SG_ 819 ChildLckFdbckRp_B_Stat 3;
BA_ "U_CD4_MY13_Diesel_Rx" SG_ 819 ChildLckFdbckRp_B_Stat 1;
BA_ "U_CD4_MY13_Gas_Rx" SG_ 819 ChildLckFdbckRp_B_Stat 1;
BA_ "U_CD4_MY13_Hev_Rx" SG_ 819 ChildLckFdbckRp_B_Stat 1;
BA_ "U_CD4_MY13_Phev_Rx" SG_ 819 ChildLckFdbckRp_B_Stat 1;
BA_ "U_CD42_MY14_Diesel_Rx" SG_ 819 ChildLckFdbckRp_B_Stat 1;
BA_ "U_CD42_MY14_Gas_Rx" SG_ 819 ChildLckFdbckRp_B_Stat 1;
BA_ "U_P552_MY15_Gas_Rx" SG_ 819 ChildLckFdbckRp_B_Stat 1;
BA_ "U_S550_MY15_Gas_Rx" SG_ 819 ChildLckFdbckRp_B_Stat 1;
BA_ "U_C489_MY14_Gas_Rx" SG_ 819 ChildLckFdbckRp_B_Stat 1;
BA_ "U_U502_MY15_Gas_Rx" SG_ 819 ChildLckFdbckRp_B_Stat 1;
BA_ "U_B479_MY15_Gas_Rx" SG_ 819 ChildLckFdbckRp_B_Stat 1;
BA_ "U_UP375_MY15_Gas_Rx" SG_ 819 ChildLckFdbckRp_B_Stat 1;
BA_ "U_UP375_MY15_Diesel_Rx" SG_ 819 ChildLckFdbckRp_B_Stat 1;
BA_ "U_CD4_MY13_Diesel_Tx" SG_ 819 ChildLckFdbckRp_B_Stat 1;
BA_ "U_CD4_MY13_Gas_Tx" SG_ 819 ChildLckFdbckRp_B_Stat 1;
BA_ "U_CD4_MY13_Hev_Tx" SG_ 819 ChildLckFdbckRp_B_Stat 1;
BA_ "U_CD4_MY13_Phev_Tx" SG_ 819 ChildLckFdbckRp_B_Stat 1;
BA_ "U_CD42_MY14_Diesel_Tx" SG_ 819 ChildLckFdbckRp_B_Stat 1;
BA_ "U_CD42_MY14_Gas_Tx" SG_ 819 ChildLckFdbckRp_B_Stat 1;
BA_ "U_P552_MY15_Gas_Tx" SG_ 819 ChildLckFdbckRp_B_Stat 1;
BA_ "U_S550_MY15_Gas_Tx" SG_ 819 ChildLckFdbckRp_B_Stat 1;
BA_ "U_C489_MY14_Gas_Tx" SG_ 819 ChildLckFdbckRp_B_Stat 1;
BA_ "U_U502_MY15_Gas_Tx" SG_ 819 ChildLckFdbckRp_B_Stat 1;
BA_ "U_UP375_MY15_Gas_Tx" SG_ 819 ChildLckFdbckRp_B_Stat 1;
BA_ "U_UP375_MY15_Diesel_Tx" SG_ 819 ChildLckFdbckRp_B_Stat 1;
BA_ "U_CD43_MY16_Gas_Tx" SG_ 819 ChildLckFdbckRp_B_Stat 1;
BA_ "U_CD4_MY14_Diesel_Tx" SG_ 819 ChildLckFdbckRp_B_Stat 1;
BA_ "U_CD4_MY14_Gas_Tx" SG_ 819 ChildLckFdbckRp_B_Stat 1;
BA_ "U_CD4_MY14_Hev_Tx" SG_ 819 ChildLckFdbckRp_B_Stat 1;
BA_ "U_CD4_MY14_Phev_Tx" SG_ 819 ChildLckFdbckRp_B_Stat 1;
BA_ "GenSigSendType" SG_ 818 BLISLEDStatDriverSide 3;
BA_ "U_CD4_MY13_Diesel_Rx" SG_ 818 BLISLEDStatDriverSide 1;
BA_ "U_CD4_MY13_Gas_Rx" SG_ 818 BLISLEDStatDriverSide 1;
BA_ "U_CD4_MY13_Hev_Rx" SG_ 818 BLISLEDStatDriverSide 1;
BA_ "U_CD4_MY13_Phev_Rx" SG_ 818 BLISLEDStatDriverSide 1;
BA_ "U_CD42_MY14_Diesel_Rx" SG_ 818 BLISLEDStatDriverSide 1;
BA_ "U_CD42_MY14_Gas_Rx" SG_ 818 BLISLEDStatDriverSide 1;
BA_ "U_P552_MY15_Gas_Rx" SG_ 818 BLISLEDStatDriverSide 1;
BA_ "U_C489_MY14_Gas_Rx" SG_ 818 BLISLEDStatDriverSide 1;
BA_ "U_B562LC_MY14_Gas_Rx" SG_ 818 BLISLEDStatDriverSide 1;
BA_ "U_U502_MY15_Gas_Rx" SG_ 818 BLISLEDStatDriverSide 1;
BA_ "U_UP375_MY15_Gas_Rx" SG_ 818 BLISLEDStatDriverSide 1;
BA_ "U_UP375_MY15_Diesel_Rx" SG_ 818 BLISLEDStatDriverSide 1;
BA_ "U_CD43_MY16_Gas_Rx" SG_ 818 BLISLEDStatDriverSide 1;
BA_ "U_CD4_MY13_Diesel_Tx" SG_ 818 BLISLEDStatDriverSide 1;
BA_ "U_CD4_MY13_Gas_Tx" SG_ 818 BLISLEDStatDriverSide 1;
BA_ "U_CD4_MY13_Hev_Tx" SG_ 818 BLISLEDStatDriverSide 1;
BA_ "U_CD4_MY13_Phev_Tx" SG_ 818 BLISLEDStatDriverSide 1;
BA_ "U_CD42_MY14_Diesel_Tx" SG_ 818 BLISLEDStatDriverSide 1;
BA_ "U_CD42_MY14_Gas_Tx" SG_ 818 BLISLEDStatDriverSide 1;
BA_ "U_P552_MY15_Gas_Tx" SG_ 818 BLISLEDStatDriverSide 1;
BA_ "U_S550_MY15_Gas_Tx" SG_ 818 BLISLEDStatDriverSide 1;
BA_ "U_C489_MY14_Gas_Tx" SG_ 818 BLISLEDStatDriverSide 1;
BA_ "U_U502_MY15_Gas_Tx" SG_ 818 BLISLEDStatDriverSide 1;
BA_ "U_UP375_MY15_Gas_Tx" SG_ 818 BLISLEDStatDriverSide 1;
BA_ "U_UP375_MY15_Diesel_Tx" SG_ 818 BLISLEDStatDriverSide 1;
BA_ "U_CD43_MY16_Gas_Tx" SG_ 818 BLISLEDStatDriverSide 1;
BA_ "U_CD4_MY14_Diesel_Tx" SG_ 818 BLISLEDStatDriverSide 1;
BA_ "U_CD4_MY14_Gas_Tx" SG_ 818 BLISLEDStatDriverSide 1;
BA_ "U_CD4_MY14_Hev_Tx" SG_ 818 BLISLEDStatDriverSide 1;
BA_ "U_CD4_MY14_Phev_Tx" SG_ 818 BLISLEDStatDriverSide 1;
BA_ "WakeupSignal" SG_ 818 ChildLckPw_N_Cnt 1;
BA_ "GenSigSendType" SG_ 818 ChildLckPw_N_Cnt 3;
BA_ "U_CD4_MY13_Diesel_Rx" SG_ 818 ChildLckPw_N_Cnt 1;
BA_ "U_CD4_MY13_Gas_Rx" SG_ 818 ChildLckPw_N_Cnt 1;
BA_ "U_CD4_MY13_Hev_Rx" SG_ 818 ChildLckPw_N_Cnt 1;
BA_ "U_CD4_MY13_Phev_Rx" SG_ 818 ChildLckPw_N_Cnt 1;
BA_ "U_CD42_MY14_Diesel_Rx" SG_ 818 ChildLckPw_N_Cnt 1;
BA_ "U_CD42_MY14_Gas_Rx" SG_ 818 ChildLckPw_N_Cnt 1;
BA_ "U_P552_MY15_Gas_Rx" SG_ 818 ChildLckPw_N_Cnt 1;
BA_ "U_S550_MY15_Gas_Rx" SG_ 818 ChildLckPw_N_Cnt 1;
BA_ "U_C489_MY14_Gas_Rx" SG_ 818 ChildLckPw_N_Cnt 1;
BA_ "U_U502_MY15_Gas_Rx" SG_ 818 ChildLckPw_N_Cnt 1;
BA_ "U_B479_MY15_Gas_Rx" SG_ 818 ChildLckPw_N_Cnt 1;
BA_ "U_UP375_MY15_Gas_Rx" SG_ 818 ChildLckPw_N_Cnt 1;
BA_ "U_UP375_MY15_Diesel_Rx" SG_ 818 ChildLckPw_N_Cnt 1;
BA_ "U_CD4_MY13_Diesel_Tx" SG_ 818 ChildLckPw_N_Cnt 1;
BA_ "U_CD4_MY13_Gas_Tx" SG_ 818 ChildLckPw_N_Cnt 1;
BA_ "U_CD4_MY13_Hev_Tx" SG_ 818 ChildLckPw_N_Cnt 1;
BA_ "U_CD4_MY13_Phev_Tx" SG_ 818 ChildLckPw_N_Cnt 1;
BA_ "U_CD42_MY14_Diesel_Tx" SG_ 818 ChildLckPw_N_Cnt 1;
BA_ "U_CD42_MY14_Gas_Tx" SG_ 818 ChildLckPw_N_Cnt 1;
BA_ "U_P552_MY15_Gas_Tx" SG_ 818 ChildLckPw_N_Cnt 1;
BA_ "U_S550_MY15_Gas_Tx" SG_ 818 ChildLckPw_N_Cnt 1;
BA_ "U_C489_MY14_Gas_Tx" SG_ 818 ChildLckPw_N_Cnt 1;
BA_ "U_U502_MY15_Gas_Tx" SG_ 818 ChildLckPw_N_Cnt 1;
BA_ "U_UP375_MY15_Gas_Tx" SG_ 818 ChildLckPw_N_Cnt 1;
BA_ "U_UP375_MY15_Diesel_Tx" SG_ 818 ChildLckPw_N_Cnt 1;
BA_ "U_CD43_MY16_Gas_Tx" SG_ 818 ChildLckPw_N_Cnt 1;
BA_ "U_CD4_MY14_Diesel_Tx" SG_ 818 ChildLckPw_N_Cnt 1;
BA_ "U_CD4_MY14_Gas_Tx" SG_ 818 ChildLckPw_N_Cnt 1;
BA_ "U_CD4_MY14_Hev_Tx" SG_ 818 ChildLckPw_N_Cnt 1;
BA_ "U_CD4_MY14_Phev_Tx" SG_ 818 ChildLckPw_N_Cnt 1;
BA_ "GenSigSendType" SG_ 818 WndwDrvSide_D_Stat 3;
BA_ "U_CD4_MY13_Diesel_Tx" SG_ 818 WndwDrvSide_D_Stat 1;
BA_ "U_CD4_MY13_Gas_Tx" SG_ 818 WndwDrvSide_D_Stat 1;
BA_ "U_CD4_MY13_Hev_Tx" SG_ 818 WndwDrvSide_D_Stat 1;
BA_ "U_CD4_MY13_Phev_Tx" SG_ 818 WndwDrvSide_D_Stat 1;
BA_ "U_CD42_MY14_Diesel_Tx" SG_ 818 WndwDrvSide_D_Stat 1;
BA_ "U_CD42_MY14_Gas_Tx" SG_ 818 WndwDrvSide_D_Stat 1;
BA_ "U_P552_MY15_Gas_Tx" SG_ 818 WndwDrvSide_D_Stat 1;
BA_ "U_S550_MY15_Gas_Tx" SG_ 818 WndwDrvSide_D_Stat 1;
BA_ "U_C489_MY14_Gas_Tx" SG_ 818 WndwDrvSide_D_Stat 1;
BA_ "U_U502_MY15_Gas_Tx" SG_ 818 WndwDrvSide_D_Stat 1;
BA_ "U_UP375_MY15_Gas_Tx" SG_ 818 WndwDrvSide_D_Stat 1;
BA_ "U_UP375_MY15_Diesel_Tx" SG_ 818 WndwDrvSide_D_Stat 1;
BA_ "U_CD43_MY16_Gas_Tx" SG_ 818 WndwDrvSide_D_Stat 1;
BA_ "U_CD4_MY14_Diesel_Tx" SG_ 818 WndwDrvSide_D_Stat 1;
BA_ "U_CD4_MY14_Gas_Tx" SG_ 818 WndwDrvSide_D_Stat 1;
BA_ "U_CD4_MY14_Hev_Tx" SG_ 818 WndwDrvSide_D_Stat 1;
BA_ "U_CD4_MY14_Phev_Tx" SG_ 818 WndwDrvSide_D_Stat 1;
BA_ "GenSigSendType" SG_ 818 RollCodeDrvDrKeyCyl 3;
BA_ "U_CD4_MY13_Diesel_Tx" SG_ 818 RollCodeDrvDrKeyCyl 1;
BA_ "U_CD4_MY13_Gas_Tx" SG_ 818 RollCodeDrvDrKeyCyl 1;
BA_ "U_CD4_MY13_Hev_Tx" SG_ 818 RollCodeDrvDrKeyCyl 1;
BA_ "U_CD4_MY13_Phev_Tx" SG_ 818 RollCodeDrvDrKeyCyl 1;
BA_ "U_CD42_MY14_Diesel_Tx" SG_ 818 RollCodeDrvDrKeyCyl 1;
BA_ "U_CD42_MY14_Gas_Tx" SG_ 818 RollCodeDrvDrKeyCyl 1;
BA_ "U_P552_MY15_Gas_Tx" SG_ 818 RollCodeDrvDrKeyCyl 1;
BA_ "U_S550_MY15_Gas_Tx" SG_ 818 RollCodeDrvDrKeyCyl 1;
BA_ "U_C489_MY14_Gas_Tx" SG_ 818 RollCodeDrvDrKeyCyl 1;
BA_ "U_U502_MY15_Gas_Tx" SG_ 818 RollCodeDrvDrKeyCyl 1;
BA_ "U_UP375_MY15_Gas_Tx" SG_ 818 RollCodeDrvDrKeyCyl 1;
BA_ "U_UP375_MY15_Diesel_Tx" SG_ 818 RollCodeDrvDrKeyCyl 1;
BA_ "U_CD43_MY16_Gas_Tx" SG_ 818 RollCodeDrvDrKeyCyl 1;
BA_ "U_CD4_MY14_Diesel_Tx" SG_ 818 RollCodeDrvDrKeyCyl 1;
BA_ "U_CD4_MY14_Gas_Tx" SG_ 818 RollCodeDrvDrKeyCyl 1;
BA_ "U_CD4_MY14_Hev_Tx" SG_ 818 RollCodeDrvDrKeyCyl 1;
BA_ "U_CD4_MY14_Phev_Tx" SG_ 818 RollCodeDrvDrKeyCyl 1;
BA_ "WakeupSignal" SG_ 818 KeyCylSwDrvDr_D_Stat 1;
BA_ "GenSigSendType" SG_ 818 KeyCylSwDrvDr_D_Stat 3;
BA_ "U_CD4_MY13_Diesel_Rx" SG_ 818 KeyCylSwDrvDr_D_Stat 1;
BA_ "U_CD4_MY13_Gas_Rx" SG_ 818 KeyCylSwDrvDr_D_Stat 1;
BA_ "U_CD4_MY13_Hev_Rx" SG_ 818 KeyCylSwDrvDr_D_Stat 1;
BA_ "U_CD4_MY13_Phev_Rx" SG_ 818 KeyCylSwDrvDr_D_Stat 1;
BA_ "U_CD42_MY14_Diesel_Rx" SG_ 818 KeyCylSwDrvDr_D_Stat 1;
BA_ "U_CD42_MY14_Gas_Rx" SG_ 818 KeyCylSwDrvDr_D_Stat 1;
BA_ "U_P552_MY15_Gas_Rx" SG_ 818 KeyCylSwDrvDr_D_Stat 1;
BA_ "U_S550_MY15_Gas_Rx" SG_ 818 KeyCylSwDrvDr_D_Stat 1;
BA_ "U_C489_MY14_Gas_Rx" SG_ 818 KeyCylSwDrvDr_D_Stat 1;
BA_ "U_U502_MY15_Gas_Rx" SG_ 818 KeyCylSwDrvDr_D_Stat 1;
BA_ "U_B479_MY15_Gas_Rx" SG_ 818 KeyCylSwDrvDr_D_Stat 1;
BA_ "U_UP375_MY15_Gas_Rx" SG_ 818 KeyCylSwDrvDr_D_Stat 1;
BA_ "U_UP375_MY15_Diesel_Rx" SG_ 818 KeyCylSwDrvDr_D_Stat 1;
BA_ "U_CD4_MY13_Diesel_Tx" SG_ 818 KeyCylSwDrvDr_D_Stat 1;
BA_ "U_CD4_MY13_Gas_Tx" SG_ 818 KeyCylSwDrvDr_D_Stat 1;
BA_ "U_CD4_MY13_Hev_Tx" SG_ 818 KeyCylSwDrvDr_D_Stat 1;
BA_ "U_CD4_MY13_Phev_Tx" SG_ 818 KeyCylSwDrvDr_D_Stat 1;
BA_ "U_CD42_MY14_Diesel_Tx" SG_ 818 KeyCylSwDrvDr_D_Stat 1;
BA_ "U_CD42_MY14_Gas_Tx" SG_ 818 KeyCylSwDrvDr_D_Stat 1;
BA_ "U_P552_MY15_Gas_Tx" SG_ 818 KeyCylSwDrvDr_D_Stat 1;
BA_ "U_S550_MY15_Gas_Tx" SG_ 818 KeyCylSwDrvDr_D_Stat 1;
BA_ "U_C489_MY14_Gas_Tx" SG_ 818 KeyCylSwDrvDr_D_Stat 1;
BA_ "U_U502_MY15_Gas_Tx" SG_ 818 KeyCylSwDrvDr_D_Stat 1;
BA_ "U_UP375_MY15_Gas_Tx" SG_ 818 KeyCylSwDrvDr_D_Stat 1;
BA_ "U_UP375_MY15_Diesel_Tx" SG_ 818 KeyCylSwDrvDr_D_Stat 1;
BA_ "U_CD43_MY16_Gas_Tx" SG_ 818 KeyCylSwDrvDr_D_Stat 1;
BA_ "U_CD4_MY14_Diesel_Tx" SG_ 818 KeyCylSwDrvDr_D_Stat 1;
BA_ "U_CD4_MY14_Gas_Tx" SG_ 818 KeyCylSwDrvDr_D_Stat 1;
BA_ "U_CD4_MY14_Hev_Tx" SG_ 818 KeyCylSwDrvDr_D_Stat 1;
BA_ "U_CD4_MY14_Phev_Tx" SG_ 818 KeyCylSwDrvDr_D_Stat 1;
BA_ "WakeupSignal" SG_ 818 Driver_Lock_Sw_Stat 1;
BA_ "GenSigSendType" SG_ 818 Driver_Lock_Sw_Stat 3;
BA_ "U_CD4_MY13_Diesel_Rx" SG_ 818 Driver_Lock_Sw_Stat 1;
BA_ "U_CD4_MY13_Gas_Rx" SG_ 818 Driver_Lock_Sw_Stat 1;
BA_ "U_CD4_MY13_Hev_Rx" SG_ 818 Driver_Lock_Sw_Stat 1;
BA_ "U_CD4_MY13_Phev_Rx" SG_ 818 Driver_Lock_Sw_Stat 1;
BA_ "U_CD42_MY14_Diesel_Rx" SG_ 818 Driver_Lock_Sw_Stat 1;
BA_ "U_CD42_MY14_Gas_Rx" SG_ 818 Driver_Lock_Sw_Stat 1;
BA_ "U_P552_MY15_Gas_Rx" SG_ 818 Driver_Lock_Sw_Stat 1;
BA_ "U_S550_MY15_Gas_Rx" SG_ 818 Driver_Lock_Sw_Stat 1;
BA_ "U_C489_MY14_Gas_Rx" SG_ 818 Driver_Lock_Sw_Stat 1;
BA_ "U_U502_MY15_Gas_Rx" SG_ 818 Driver_Lock_Sw_Stat 1;
BA_ "U_B479_MY15_Gas_Rx" SG_ 818 Driver_Lock_Sw_Stat 1;
BA_ "U_UP375_MY15_Gas_Rx" SG_ 818 Driver_Lock_Sw_Stat 1;
BA_ "U_UP375_MY15_Diesel_Rx" SG_ 818 Driver_Lock_Sw_Stat 1;
BA_ "U_CD4_MY13_Diesel_Tx" SG_ 818 Driver_Lock_Sw_Stat 1;
BA_ "U_CD4_MY13_Gas_Tx" SG_ 818 Driver_Lock_Sw_Stat 1;
BA_ "U_CD4_MY13_Hev_Tx" SG_ 818 Driver_Lock_Sw_Stat 1;
BA_ "U_CD4_MY13_Phev_Tx" SG_ 818 Driver_Lock_Sw_Stat 1;
BA_ "U_CD42_MY14_Diesel_Tx" SG_ 818 Driver_Lock_Sw_Stat 1;
BA_ "U_CD42_MY14_Gas_Tx" SG_ 818 Driver_Lock_Sw_Stat 1;
BA_ "U_P552_MY15_Gas_Tx" SG_ 818 Driver_Lock_Sw_Stat 1;
BA_ "U_S550_MY15_Gas_Tx" SG_ 818 Driver_Lock_Sw_Stat 1;
BA_ "U_C489_MY14_Gas_Tx" SG_ 818 Driver_Lock_Sw_Stat 1;
BA_ "U_U502_MY15_Gas_Tx" SG_ 818 Driver_Lock_Sw_Stat 1;
BA_ "U_UP375_MY15_Gas_Tx" SG_ 818 Driver_Lock_Sw_Stat 1;
BA_ "U_UP375_MY15_Diesel_Tx" SG_ 818 Driver_Lock_Sw_Stat 1;
BA_ "U_CD43_MY16_Gas_Tx" SG_ 818 Driver_Lock_Sw_Stat 1;
BA_ "U_CD4_MY14_Diesel_Tx" SG_ 818 Driver_Lock_Sw_Stat 1;
BA_ "U_CD4_MY14_Gas_Tx" SG_ 818 Driver_Lock_Sw_Stat 1;
BA_ "U_CD4_MY14_Hev_Tx" SG_ 818 Driver_Lock_Sw_Stat 1;
BA_ "U_CD4_MY14_Phev_Tx" SG_ 818 Driver_Lock_Sw_Stat 1;
BA_ "WakeupSignal" SG_ 818 Driver_Lock_Sw_Cnt 1;
BA_ "GenSigSendType" SG_ 818 Driver_Lock_Sw_Cnt 3;
BA_ "U_CD4_MY13_Diesel_Rx" SG_ 818 Driver_Lock_Sw_Cnt 1;
BA_ "U_CD4_MY13_Gas_Rx" SG_ 818 Driver_Lock_Sw_Cnt 1;
BA_ "U_CD4_MY13_Hev_Rx" SG_ 818 Driver_Lock_Sw_Cnt 1;
BA_ "U_CD4_MY13_Phev_Rx" SG_ 818 Driver_Lock_Sw_Cnt 1;
BA_ "U_CD42_MY14_Diesel_Rx" SG_ 818 Driver_Lock_Sw_Cnt 1;
BA_ "U_CD42_MY14_Gas_Rx" SG_ 818 Driver_Lock_Sw_Cnt 1;
BA_ "U_P552_MY15_Gas_Rx" SG_ 818 Driver_Lock_Sw_Cnt 1;
BA_ "U_S550_MY15_Gas_Rx" SG_ 818 Driver_Lock_Sw_Cnt 1;
BA_ "U_C489_MY14_Gas_Rx" SG_ 818 Driver_Lock_Sw_Cnt 1;
BA_ "U_U502_MY15_Gas_Rx" SG_ 818 Driver_Lock_Sw_Cnt 1;
BA_ "U_B479_MY15_Gas_Rx" SG_ 818 Driver_Lock_Sw_Cnt 1;
BA_ "U_UP375_MY15_Gas_Rx" SG_ 818 Driver_Lock_Sw_Cnt 1;
BA_ "U_UP375_MY15_Diesel_Rx" SG_ 818 Driver_Lock_Sw_Cnt 1;
BA_ "U_CD4_MY13_Diesel_Tx" SG_ 818 Driver_Lock_Sw_Cnt 1;
BA_ "U_CD4_MY13_Gas_Tx" SG_ 818 Driver_Lock_Sw_Cnt 1;
BA_ "U_CD4_MY13_Hev_Tx" SG_ 818 Driver_Lock_Sw_Cnt 1;
BA_ "U_CD4_MY13_Phev_Tx" SG_ 818 Driver_Lock_Sw_Cnt 1;
BA_ "U_CD42_MY14_Diesel_Tx" SG_ 818 Driver_Lock_Sw_Cnt 1;
BA_ "U_CD42_MY14_Gas_Tx" SG_ 818 Driver_Lock_Sw_Cnt 1;
BA_ "U_P552_MY15_Gas_Tx" SG_ 818 Driver_Lock_Sw_Cnt 1;
BA_ "U_S550_MY15_Gas_Tx" SG_ 818 Driver_Lock_Sw_Cnt 1;
BA_ "U_C489_MY14_Gas_Tx" SG_ 818 Driver_Lock_Sw_Cnt 1;
BA_ "U_U502_MY15_Gas_Tx" SG_ 818 Driver_Lock_Sw_Cnt 1;
BA_ "U_UP375_MY15_Gas_Tx" SG_ 818 Driver_Lock_Sw_Cnt 1;
BA_ "U_UP375_MY15_Diesel_Tx" SG_ 818 Driver_Lock_Sw_Cnt 1;
BA_ "U_CD43_MY16_Gas_Tx" SG_ 818 Driver_Lock_Sw_Cnt 1;
BA_ "U_CD4_MY14_Diesel_Tx" SG_ 818 Driver_Lock_Sw_Cnt 1;
BA_ "U_CD4_MY14_Gas_Tx" SG_ 818 Driver_Lock_Sw_Cnt 1;
BA_ "U_CD4_MY14_Hev_Tx" SG_ 818 Driver_Lock_Sw_Cnt 1;
BA_ "U_CD4_MY14_Phev_Tx" SG_ 818 Driver_Lock_Sw_Cnt 1;
BA_ "WakeupSignal" SG_ 818 ChildLckPw_D_Rq 1;
BA_ "GenSigSendType" SG_ 818 ChildLckPw_D_Rq 3;
BA_ "U_CD4_MY13_Diesel_Rx" SG_ 818 ChildLckPw_D_Rq 1;
BA_ "U_CD4_MY13_Gas_Rx" SG_ 818 ChildLckPw_D_Rq 1;
BA_ "U_CD4_MY13_Hev_Rx" SG_ 818 ChildLckPw_D_Rq 1;
BA_ "U_CD4_MY13_Phev_Rx" SG_ 818 ChildLckPw_D_Rq 1;
BA_ "U_CD42_MY14_Diesel_Rx" SG_ 818 ChildLckPw_D_Rq 1;
BA_ "U_CD42_MY14_Gas_Rx" SG_ 818 ChildLckPw_D_Rq 1;
BA_ "U_P552_MY15_Gas_Rx" SG_ 818 ChildLckPw_D_Rq 1;
BA_ "U_S550_MY15_Gas_Rx" SG_ 818 ChildLckPw_D_Rq 1;
BA_ "U_C489_MY14_Gas_Rx" SG_ 818 ChildLckPw_D_Rq 1;
BA_ "U_U502_MY15_Gas_Rx" SG_ 818 ChildLckPw_D_Rq 1;
BA_ "U_B479_MY15_Gas_Rx" SG_ 818 ChildLckPw_D_Rq 1;
BA_ "U_UP375_MY15_Gas_Rx" SG_ 818 ChildLckPw_D_Rq 1;
BA_ "U_UP375_MY15_Diesel_Rx" SG_ 818 ChildLckPw_D_Rq 1;
BA_ "U_CD4_MY13_Diesel_Tx" SG_ 818 ChildLckPw_D_Rq 1;
BA_ "U_CD4_MY13_Gas_Tx" SG_ 818 ChildLckPw_D_Rq 1;
BA_ "U_CD4_MY13_Hev_Tx" SG_ 818 ChildLckPw_D_Rq 1;
BA_ "U_CD4_MY13_Phev_Tx" SG_ 818 ChildLckPw_D_Rq 1;
BA_ "U_CD42_MY14_Diesel_Tx" SG_ 818 ChildLckPw_D_Rq 1;
BA_ "U_CD42_MY14_Gas_Tx" SG_ 818 ChildLckPw_D_Rq 1;
BA_ "U_P552_MY15_Gas_Tx" SG_ 818 ChildLckPw_D_Rq 1;
BA_ "U_S550_MY15_Gas_Tx" SG_ 818 ChildLckPw_D_Rq 1;
BA_ "U_C489_MY14_Gas_Tx" SG_ 818 ChildLckPw_D_Rq 1;
BA_ "U_U502_MY15_Gas_Tx" SG_ 818 ChildLckPw_D_Rq 1;
BA_ "U_UP375_MY15_Gas_Tx" SG_ 818 ChildLckPw_D_Rq 1;
BA_ "U_UP375_MY15_Diesel_Tx" SG_ 818 ChildLckPw_D_Rq 1;
BA_ "U_CD43_MY16_Gas_Tx" SG_ 818 ChildLckPw_D_Rq 1;
BA_ "U_CD4_MY14_Diesel_Tx" SG_ 818 ChildLckPw_D_Rq 1;
BA_ "U_CD4_MY14_Gas_Tx" SG_ 818 ChildLckPw_D_Rq 1;
BA_ "U_CD4_MY14_Hev_Tx" SG_ 818 ChildLckPw_D_Rq 1;
BA_ "U_CD4_MY14_Phev_Tx" SG_ 818 ChildLckPw_D_Rq 1;
BA_ "WakeupSignal" SG_ 818 ChildLckFdbckRd_B_Stat 1;
BA_ "GenSigSendType" SG_ 818 ChildLckFdbckRd_B_Stat 3;
BA_ "U_CD4_MY13_Diesel_Rx" SG_ 818 ChildLckFdbckRd_B_Stat 1;
BA_ "U_CD4_MY13_Gas_Rx" SG_ 818 ChildLckFdbckRd_B_Stat 1;
BA_ "U_CD4_MY13_Hev_Rx" SG_ 818 ChildLckFdbckRd_B_Stat 1;
BA_ "U_CD4_MY13_Phev_Rx" SG_ 818 ChildLckFdbckRd_B_Stat 1;
BA_ "U_CD42_MY14_Diesel_Rx" SG_ 818 ChildLckFdbckRd_B_Stat 1;
BA_ "U_CD42_MY14_Gas_Rx" SG_ 818 ChildLckFdbckRd_B_Stat 1;
BA_ "U_P552_MY15_Gas_Rx" SG_ 818 ChildLckFdbckRd_B_Stat 1;
BA_ "U_S550_MY15_Gas_Rx" SG_ 818 ChildLckFdbckRd_B_Stat 1;
BA_ "U_C489_MY14_Gas_Rx" SG_ 818 ChildLckFdbckRd_B_Stat 1;
BA_ "U_U502_MY15_Gas_Rx" SG_ 818 ChildLckFdbckRd_B_Stat 1;
BA_ "U_B479_MY15_Gas_Rx" SG_ 818 ChildLckFdbckRd_B_Stat 1;
BA_ "U_UP375_MY15_Gas_Rx" SG_ 818 ChildLckFdbckRd_B_Stat 1;
BA_ "U_UP375_MY15_Diesel_Rx" SG_ 818 ChildLckFdbckRd_B_Stat 1;
BA_ "U_CD4_MY13_Diesel_Tx" SG_ 818 ChildLckFdbckRd_B_Stat 1;
BA_ "U_CD4_MY13_Gas_Tx" SG_ 818 ChildLckFdbckRd_B_Stat 1;
BA_ "U_CD4_MY13_Hev_Tx" SG_ 818 ChildLckFdbckRd_B_Stat 1;
BA_ "U_CD4_MY13_Phev_Tx" SG_ 818 ChildLckFdbckRd_B_Stat 1;
BA_ "U_CD42_MY14_Diesel_Tx" SG_ 818 ChildLckFdbckRd_B_Stat 1;
BA_ "U_CD42_MY14_Gas_Tx" SG_ 818 ChildLckFdbckRd_B_Stat 1;
BA_ "U_P552_MY15_Gas_Tx" SG_ 818 ChildLckFdbckRd_B_Stat 1;
BA_ "U_S550_MY15_Gas_Tx" SG_ 818 ChildLckFdbckRd_B_Stat 1;
BA_ "U_C489_MY14_Gas_Tx" SG_ 818 ChildLckFdbckRd_B_Stat 1;
BA_ "U_U502_MY15_Gas_Tx" SG_ 818 ChildLckFdbckRd_B_Stat 1;
BA_ "U_UP375_MY15_Gas_Tx" SG_ 818 ChildLckFdbckRd_B_Stat 1;
BA_ "U_UP375_MY15_Diesel_Tx" SG_ 818 ChildLckFdbckRd_B_Stat 1;
BA_ "U_CD43_MY16_Gas_Tx" SG_ 818 ChildLckFdbckRd_B_Stat 1;
BA_ "U_CD4_MY14_Diesel_Tx" SG_ 818 ChildLckFdbckRd_B_Stat 1;
BA_ "U_CD4_MY14_Gas_Tx" SG_ 818 ChildLckFdbckRd_B_Stat 1;
BA_ "U_CD4_MY14_Hev_Tx" SG_ 818 ChildLckFdbckRd_B_Stat 1;
BA_ "U_CD4_MY14_Phev_Tx" SG_ 818 ChildLckFdbckRd_B_Stat 1;
BA_ "CrossOver_InfoCAN" SG_ 818 RvrseMirrorChime_B_Rq 1;
BA_ "GenSigSendType" SG_ 818 RvrseMirrorChime_B_Rq 3;
BA_ "U_CD4_MY13_Diesel_Tx" SG_ 818 RvrseMirrorChime_B_Rq 1;
BA_ "U_CD4_MY13_Gas_Tx" SG_ 818 RvrseMirrorChime_B_Rq 1;
BA_ "U_CD4_MY13_Hev_Tx" SG_ 818 RvrseMirrorChime_B_Rq 1;
BA_ "U_CD4_MY13_Phev_Tx" SG_ 818 RvrseMirrorChime_B_Rq 1;
BA_ "U_CD42_MY14_Diesel_Tx" SG_ 818 RvrseMirrorChime_B_Rq 1;
BA_ "U_CD42_MY14_Gas_Tx" SG_ 818 RvrseMirrorChime_B_Rq 1;
BA_ "U_P552_MY15_Gas_Tx" SG_ 818 RvrseMirrorChime_B_Rq 1;
BA_ "U_S550_MY15_Gas_Tx" SG_ 818 RvrseMirrorChime_B_Rq 1;
BA_ "U_C489_MY14_Gas_Tx" SG_ 818 RvrseMirrorChime_B_Rq 1;
BA_ "U_U502_MY15_Gas_Tx" SG_ 818 RvrseMirrorChime_B_Rq 1;
BA_ "U_UP375_MY15_Gas_Tx" SG_ 818 RvrseMirrorChime_B_Rq 1;
BA_ "U_UP375_MY15_Diesel_Tx" SG_ 818 RvrseMirrorChime_B_Rq 1;
BA_ "U_CD43_MY16_Gas_Tx" SG_ 818 RvrseMirrorChime_B_Rq 1;
BA_ "U_CD4_MY14_Diesel_Tx" SG_ 818 RvrseMirrorChime_B_Rq 1;
BA_ "U_CD4_MY14_Gas_Tx" SG_ 818 RvrseMirrorChime_B_Rq 1;
BA_ "U_CD4_MY14_Hev_Tx" SG_ 818 RvrseMirrorChime_B_Rq 1;
BA_ "U_CD4_MY14_Phev_Tx" SG_ 818 RvrseMirrorChime_B_Rq 1;
BA_ "WakeupSignal" SG_ 817 R_Pwr_Sliding_Dr_Rqst 1;
BA_ "WakeupSignal" SG_ 817 L_Pwr_Sliding_Dr_Rqst 1;
BA_ "U_CD43_MY17_Gas_Rx" SG_ 817 ChildLckMde_B_Stat 1;
BA_ "WakeupSignal" SG_ 817 ChildLckMde_B_Stat 1;
BA_ "U_P552_MY15_Gas_Rx" SG_ 817 VehLckInd_D_Rq 1;
BA_ "U_S550_MY15_Gas_Rx" SG_ 817 VehLckInd_D_Rq 1;
BA_ "U_C489_MY14_Gas_Rx" SG_ 817 VehLckInd_D_Rq 1;
BA_ "U_UP375_MY15_Gas_Rx" SG_ 817 VehLckInd_D_Rq 1;
BA_ "U_UP375_MY15_Diesel_Rx" SG_ 817 VehLckInd_D_Rq 1;
BA_ "WakeupSignal" SG_ 817 DrTgateOpen_B_Rq 1;
BA_ "WakeupSignal" SG_ 817 DrTgateExtSwMde_B_Stat 1;
BA_ "WakeupSignal" SG_ 817 Remote_Device_Feedback 1;
BA_ "U_CD4_MY13_Diesel_Rx" SG_ 817 Remote_Device_Feedback 1;
BA_ "U_CD4_MY13_Gas_Rx" SG_ 817 Remote_Device_Feedback 1;
BA_ "U_CD4_MY13_Hev_Rx" SG_ 817 Remote_Device_Feedback 1;
BA_ "U_CD4_MY13_Phev_Rx" SG_ 817 Remote_Device_Feedback 1;
BA_ "U_CD42_MY14_Diesel_Rx" SG_ 817 Remote_Device_Feedback 1;
BA_ "U_CD42_MY14_Gas_Rx" SG_ 817 Remote_Device_Feedback 1;
BA_ "U_P552_MY15_Gas_Rx" SG_ 817 Remote_Device_Feedback 1;
BA_ "U_S550_MY15_Gas_Rx" SG_ 817 Remote_Device_Feedback 1;
BA_ "U_C489_MY14_Gas_Rx" SG_ 817 Remote_Device_Feedback 1;
BA_ "U_U502_MY15_Gas_Rx" SG_ 817 Remote_Device_Feedback 1;
BA_ "U_UP375_MY15_Gas_Rx" SG_ 817 Remote_Device_Feedback 1;
BA_ "U_UP375_MY15_Diesel_Rx" SG_ 817 Remote_Device_Feedback 1;
BA_ "U_CD43_MY16_Gas_Rx" SG_ 817 Remote_Device_Feedback 1;
BA_ "U_CD4_MY14_Diesel_Rx" SG_ 817 Remote_Device_Feedback 1;
BA_ "U_CD4_MY14_Gas_Rx" SG_ 817 Remote_Device_Feedback 1;
BA_ "U_CD4_MY14_Hev_Rx" SG_ 817 Remote_Device_Feedback 1;
BA_ "U_CD4_MY14_Phev_Rx" SG_ 817 Remote_Device_Feedback 1;
BA_ "WakeupSignal" SG_ 817 Power_Liftgate_Rqst 1;
BA_ "WakeupSignal" SG_ 817 Power_Decklid_Rqst 1;
BA_ "WakeupSignal" SG_ 817 Keyfob_Pad_Msg_Count 1;
BA_ "WakeupSignal" SG_ 817 Veh_Lock_Requestor 1;
BA_ "U_CD4_MY13_Diesel_Rx" SG_ 817 Veh_Lock_Requestor 1;
BA_ "U_CD4_MY13_Gas_Rx" SG_ 817 Veh_Lock_Requestor 1;
BA_ "U_CD4_MY13_Hev_Rx" SG_ 817 Veh_Lock_Requestor 1;
BA_ "U_CD4_MY13_Phev_Rx" SG_ 817 Veh_Lock_Requestor 1;
BA_ "U_CD42_MY14_Diesel_Rx" SG_ 817 Veh_Lock_Requestor 1;
BA_ "U_CD42_MY14_Gas_Rx" SG_ 817 Veh_Lock_Requestor 1;
BA_ "U_P552_MY15_Gas_Rx" SG_ 817 Veh_Lock_Requestor 1;
BA_ "U_S550_MY15_Gas_Rx" SG_ 817 Veh_Lock_Requestor 1;
BA_ "U_C489_MY14_Gas_Rx" SG_ 817 Veh_Lock_Requestor 1;
BA_ "U_U502_MY15_Gas_Rx" SG_ 817 Veh_Lock_Requestor 1;
BA_ "U_UP375_MY15_Gas_Rx" SG_ 817 Veh_Lock_Requestor 1;
BA_ "U_UP375_MY15_Diesel_Rx" SG_ 817 Veh_Lock_Requestor 1;
BA_ "U_CD43_MY16_Gas_Rx" SG_ 817 Veh_Lock_Requestor 1;
BA_ "U_CD4_MY14_Diesel_Rx" SG_ 817 Veh_Lock_Requestor 1;
BA_ "U_CD4_MY14_Gas_Rx" SG_ 817 Veh_Lock_Requestor 1;
BA_ "U_CD4_MY14_Hev_Rx" SG_ 817 Veh_Lock_Requestor 1;
BA_ "U_CD4_MY14_Phev_Rx" SG_ 817 Veh_Lock_Requestor 1;
BA_ "WakeupSignal" SG_ 817 Veh_Lock_EvNum 1;
BA_ "U_CD4_MY13_Diesel_Rx" SG_ 817 Veh_Lock_EvNum 1;
BA_ "U_CD4_MY13_Gas_Rx" SG_ 817 Veh_Lock_EvNum 1;
BA_ "U_CD4_MY13_Hev_Rx" SG_ 817 Veh_Lock_EvNum 1;
BA_ "U_CD4_MY13_Phev_Rx" SG_ 817 Veh_Lock_EvNum 1;
BA_ "U_CD42_MY14_Diesel_Rx" SG_ 817 Veh_Lock_EvNum 1;
BA_ "U_CD42_MY14_Gas_Rx" SG_ 817 Veh_Lock_EvNum 1;
BA_ "U_P552_MY15_Gas_Rx" SG_ 817 Veh_Lock_EvNum 1;
BA_ "U_S550_MY15_Gas_Rx" SG_ 817 Veh_Lock_EvNum 1;
BA_ "U_C489_MY14_Gas_Rx" SG_ 817 Veh_Lock_EvNum 1;
BA_ "U_U502_MY15_Gas_Rx" SG_ 817 Veh_Lock_EvNum 1;
BA_ "U_UP375_MY15_Gas_Rx" SG_ 817 Veh_Lock_EvNum 1;
BA_ "U_UP375_MY15_Diesel_Rx" SG_ 817 Veh_Lock_EvNum 1;
BA_ "U_CD43_MY16_Gas_Rx" SG_ 817 Veh_Lock_EvNum 1;
BA_ "U_CD4_MY14_Diesel_Rx" SG_ 817 Veh_Lock_EvNum 1;
BA_ "U_CD4_MY14_Gas_Rx" SG_ 817 Veh_Lock_EvNum 1;
BA_ "U_CD4_MY14_Hev_Rx" SG_ 817 Veh_Lock_EvNum 1;
BA_ "U_CD4_MY14_Phev_Rx" SG_ 817 Veh_Lock_EvNum 1;
BA_ "U_CD4_MY13_Diesel_Rx" SG_ 817 Veh_Lock_Sub_Id 1;
BA_ "U_CD4_MY13_Gas_Rx" SG_ 817 Veh_Lock_Sub_Id 1;
BA_ "U_CD4_MY13_Hev_Rx" SG_ 817 Veh_Lock_Sub_Id 1;
BA_ "U_CD4_MY13_Phev_Rx" SG_ 817 Veh_Lock_Sub_Id 1;
BA_ "U_CD42_MY14_Diesel_Rx" SG_ 817 Veh_Lock_Sub_Id 1;
BA_ "U_CD42_MY14_Gas_Rx" SG_ 817 Veh_Lock_Sub_Id 1;
BA_ "U_P552_MY15_Gas_Rx" SG_ 817 Veh_Lock_Sub_Id 1;
BA_ "U_S550_MY15_Gas_Rx" SG_ 817 Veh_Lock_Sub_Id 1;
BA_ "U_C489_MY14_Gas_Rx" SG_ 817 Veh_Lock_Sub_Id 1;
BA_ "U_U502_MY15_Gas_Rx" SG_ 817 Veh_Lock_Sub_Id 1;
BA_ "U_UP375_MY15_Gas_Rx" SG_ 817 Veh_Lock_Sub_Id 1;
BA_ "U_UP375_MY15_Diesel_Rx" SG_ 817 Veh_Lock_Sub_Id 1;
BA_ "U_CD43_MY16_Gas_Rx" SG_ 817 Veh_Lock_Sub_Id 1;
BA_ "U_CD4_MY14_Diesel_Rx" SG_ 817 Veh_Lock_Sub_Id 1;
BA_ "U_CD4_MY14_Gas_Rx" SG_ 817 Veh_Lock_Sub_Id 1;
BA_ "U_CD4_MY14_Hev_Rx" SG_ 817 Veh_Lock_Sub_Id 1;
BA_ "U_CD4_MY14_Phev_Rx" SG_ 817 Veh_Lock_Sub_Id 1;
BA_ "WakeupSignal" SG_ 817 ChildLck_D_Dsply 1;
BA_ "GenSigStartValue" SG_ 817 ChildLck_D_Dsply 1;
BA_ "U_CD4_MY13_Diesel_Rx" SG_ 817 ChildLck_D_Dsply 1;
BA_ "U_CD4_MY13_Gas_Rx" SG_ 817 ChildLck_D_Dsply 1;
BA_ "U_CD4_MY13_Hev_Rx" SG_ 817 ChildLck_D_Dsply 1;
BA_ "U_CD4_MY13_Phev_Rx" SG_ 817 ChildLck_D_Dsply 1;
BA_ "U_CD42_MY14_Diesel_Rx" SG_ 817 ChildLck_D_Dsply 1;
BA_ "U_CD42_MY14_Gas_Rx" SG_ 817 ChildLck_D_Dsply 1;
BA_ "U_P552_MY15_Gas_Rx" SG_ 817 ChildLck_D_Dsply 1;
BA_ "U_S550_MY15_Gas_Rx" SG_ 817 ChildLck_D_Dsply 1;
BA_ "U_C489_MY14_Gas_Rx" SG_ 817 ChildLck_D_Dsply 1;
BA_ "U_U502_MY15_Gas_Rx" SG_ 817 ChildLck_D_Dsply 1;
BA_ "U_UP375_MY15_Gas_Rx" SG_ 817 ChildLck_D_Dsply 1;
BA_ "U_UP375_MY15_Diesel_Rx" SG_ 817 ChildLck_D_Dsply 1;
BA_ "U_CD43_MY16_Gas_Rx" SG_ 817 ChildLck_D_Dsply 1;
BA_ "U_CD4_MY14_Diesel_Rx" SG_ 817 ChildLck_D_Dsply 1;
BA_ "U_CD4_MY14_Gas_Rx" SG_ 817 ChildLck_D_Dsply 1;
BA_ "U_CD4_MY14_Hev_Rx" SG_ 817 ChildLck_D_Dsply 1;
BA_ "U_CD4_MY14_Phev_Rx" SG_ 817 ChildLck_D_Dsply 1;
BA_ "U_CD4_MY13_Diesel_Rx" SG_ 817 WindowLockout_B_Stat 1;
BA_ "U_CD4_MY13_Gas_Rx" SG_ 817 WindowLockout_B_Stat 1;
BA_ "U_CD4_MY13_Hev_Rx" SG_ 817 WindowLockout_B_Stat 1;
BA_ "U_CD4_MY13_Phev_Rx" SG_ 817 WindowLockout_B_Stat 1;
BA_ "U_CD42_MY14_Diesel_Rx" SG_ 817 WindowLockout_B_Stat 1;
BA_ "U_CD42_MY14_Gas_Rx" SG_ 817 WindowLockout_B_Stat 1;
BA_ "U_P552_MY15_Gas_Rx" SG_ 817 WindowLockout_B_Stat 1;
BA_ "U_S550_MY15_Gas_Rx" SG_ 817 WindowLockout_B_Stat 1;
BA_ "U_C489_MY14_Gas_Rx" SG_ 817 WindowLockout_B_Stat 1;
BA_ "U_U502_MY15_Gas_Rx" SG_ 817 WindowLockout_B_Stat 1;
BA_ "U_UP375_MY15_Gas_Rx" SG_ 817 WindowLockout_B_Stat 1;
BA_ "U_UP375_MY15_Diesel_Rx" SG_ 817 WindowLockout_B_Stat 1;
BA_ "U_CD43_MY16_Gas_Rx" SG_ 817 WindowLockout_B_Stat 1;
BA_ "U_CD4_MY14_Diesel_Rx" SG_ 817 WindowLockout_B_Stat 1;
BA_ "U_CD4_MY14_Gas_Rx" SG_ 817 WindowLockout_B_Stat 1;
BA_ "U_CD4_MY14_Hev_Rx" SG_ 817 WindowLockout_B_Stat 1;
BA_ "U_CD4_MY14_Phev_Rx" SG_ 817 WindowLockout_B_Stat 1;
BA_ "CrossOver_InfoCAN" SG_ 817 RollCodeUnlock 1;
BA_ "U_CD4_MY13_Diesel_Rx" SG_ 817 RollCodeUnlock 1;
BA_ "U_CD4_MY13_Gas_Rx" SG_ 817 RollCodeUnlock 1;
BA_ "U_CD4_MY13_Hev_Rx" SG_ 817 RollCodeUnlock 1;
BA_ "U_CD4_MY13_Phev_Rx" SG_ 817 RollCodeUnlock 1;
BA_ "U_CD42_MY14_Diesel_Rx" SG_ 817 RollCodeUnlock 1;
BA_ "U_CD42_MY14_Gas_Rx" SG_ 817 RollCodeUnlock 1;
BA_ "U_P552_MY15_Gas_Rx" SG_ 817 RollCodeUnlock 1;
BA_ "U_S550_MY15_Gas_Rx" SG_ 817 RollCodeUnlock 1;
BA_ "U_C489_MY14_Gas_Rx" SG_ 817 RollCodeUnlock 1;
BA_ "U_U502_MY15_Gas_Rx" SG_ 817 RollCodeUnlock 1;
BA_ "U_UP375_MY15_Gas_Rx" SG_ 817 RollCodeUnlock 1;
BA_ "U_UP375_MY15_Diesel_Rx" SG_ 817 RollCodeUnlock 1;
BA_ "U_CD43_MY16_Gas_Rx" SG_ 817 RollCodeUnlock 1;
BA_ "U_CD4_MY14_Diesel_Rx" SG_ 817 RollCodeUnlock 1;
BA_ "U_CD4_MY14_Gas_Rx" SG_ 817 RollCodeUnlock 1;
BA_ "U_CD4_MY14_Hev_Rx" SG_ 817 RollCodeUnlock 1;
BA_ "U_CD4_MY14_Phev_Rx" SG_ 817 RollCodeUnlock 1;
BA_ "WakeupSignal" SG_ 817 Lockmsgtxt_D_Rq 1;
BA_ "CrossOver_InfoCAN" SG_ 817 Lockmsgtxt_D_Rq 1;
BA_ "WakeupSignal" SG_ 817 LockInhibit 1;
BA_ "WakeupSignal" SG_ 817 Veh_Lock_Status 1;
BA_ "GenSigStartValue" SG_ 817 Veh_Lock_Status 1;
BA_ "U_CD4_MY13_Diesel_Rx" SG_ 817 Veh_Lock_Status 1;
BA_ "U_CD4_MY13_Gas_Rx" SG_ 817 Veh_Lock_Status 1;
BA_ "U_CD4_MY13_Hev_Rx" SG_ 817 Veh_Lock_Status 1;
BA_ "U_CD4_MY13_Phev_Rx" SG_ 817 Veh_Lock_Status 1;
BA_ "U_CD42_MY14_Diesel_Rx" SG_ 817 Veh_Lock_Status 1;
BA_ "U_CD42_MY14_Gas_Rx" SG_ 817 Veh_Lock_Status 1;
BA_ "U_P552_MY15_Gas_Rx" SG_ 817 Veh_Lock_Status 1;
BA_ "U_S550_MY15_Gas_Rx" SG_ 817 Veh_Lock_Status 1;
BA_ "U_C489_MY14_Gas_Rx" SG_ 817 Veh_Lock_Status 1;
BA_ "U_U502_MY15_Gas_Rx" SG_ 817 Veh_Lock_Status 1;
BA_ "U_UP375_MY15_Gas_Rx" SG_ 817 Veh_Lock_Status 1;
BA_ "U_UP375_MY15_Diesel_Rx" SG_ 817 Veh_Lock_Status 1;
BA_ "U_CD43_MY16_Gas_Rx" SG_ 817 Veh_Lock_Status 1;
BA_ "U_CD4_MY14_Diesel_Rx" SG_ 817 Veh_Lock_Status 1;
BA_ "U_CD4_MY14_Gas_Rx" SG_ 817 Veh_Lock_Status 1;
BA_ "U_CD4_MY14_Hev_Rx" SG_ 817 Veh_Lock_Status 1;
BA_ "U_CD4_MY14_Phev_Rx" SG_ 817 Veh_Lock_Status 1;
BA_ "U_CD4_MY13_Diesel_Rx" SG_ 817 FobComm_D_Stat 1;
BA_ "U_CD4_MY13_Gas_Rx" SG_ 817 FobComm_D_Stat 1;
BA_ "U_CD4_MY13_Hev_Rx" SG_ 817 FobComm_D_Stat 1;
BA_ "U_CD4_MY13_Phev_Rx" SG_ 817 FobComm_D_Stat 1;
BA_ "U_CD42_MY14_Diesel_Rx" SG_ 817 FobComm_D_Stat 1;
BA_ "U_CD42_MY14_Gas_Rx" SG_ 817 FobComm_D_Stat 1;
BA_ "U_P552_MY15_Gas_Rx" SG_ 817 FobComm_D_Stat 1;
BA_ "U_S550_MY15_Gas_Rx" SG_ 817 FobComm_D_Stat 1;
BA_ "U_C489_MY14_Gas_Rx" SG_ 817 FobComm_D_Stat 1;
BA_ "U_U502_MY15_Gas_Rx" SG_ 817 FobComm_D_Stat 1;
BA_ "U_UP375_MY15_Gas_Rx" SG_ 817 FobComm_D_Stat 1;
BA_ "U_UP375_MY15_Diesel_Rx" SG_ 817 FobComm_D_Stat 1;
BA_ "U_CD43_MY16_Gas_Rx" SG_ 817 FobComm_D_Stat 1;
BA_ "CrossOver_InfoCAN" SG_ 1091 ParkLampTrlrOut_B_Stat 1;
BA_ "GenSigSendType" SG_ 1091 ParkLampTrlrOut_B_Stat 3;
BA_ "U_CD4_MY13_Diesel_Tx" SG_ 1091 ParkLampTrlrOut_B_Stat 1;
BA_ "U_CD4_MY13_Gas_Tx" SG_ 1091 ParkLampTrlrOut_B_Stat 1;
BA_ "U_CD4_MY13_Hev_Tx" SG_ 1091 ParkLampTrlrOut_B_Stat 1;
BA_ "U_CD4_MY13_Phev_Tx" SG_ 1091 ParkLampTrlrOut_B_Stat 1;
BA_ "U_CD42_MY14_Diesel_Tx" SG_ 1091 ParkLampTrlrOut_B_Stat 1;
BA_ "U_CD42_MY14_Gas_Tx" SG_ 1091 ParkLampTrlrOut_B_Stat 1;
BA_ "U_P552_MY15_Gas_Tx" SG_ 1091 ParkLampTrlrOut_B_Stat 1;
BA_ "U_C489_MY14_Gas_Tx" SG_ 1091 ParkLampTrlrOut_B_Stat 1;
BA_ "U_UP375_MY15_Gas_Tx" SG_ 1091 ParkLampTrlrOut_B_Stat 1;
BA_ "U_UP375_MY15_Diesel_Tx" SG_ 1091 ParkLampTrlrOut_B_Stat 1;
BA_ "CrossOver_InfoCAN" SG_ 1091 TrlrLampCtl_D_Stat 1;
BA_ "GenSigSendType" SG_ 1091 TrlrLampCtl_D_Stat 3;
BA_ "U_CD4_MY13_Diesel_Tx" SG_ 1091 TrlrLampCtl_D_Stat 1;
BA_ "U_CD4_MY13_Gas_Tx" SG_ 1091 TrlrLampCtl_D_Stat 1;
BA_ "U_CD4_MY13_Hev_Tx" SG_ 1091 TrlrLampCtl_D_Stat 1;
BA_ "U_CD4_MY13_Phev_Tx" SG_ 1091 TrlrLampCtl_D_Stat 1;
BA_ "U_CD42_MY14_Diesel_Tx" SG_ 1091 TrlrLampCtl_D_Stat 1;
BA_ "U_CD42_MY14_Gas_Tx" SG_ 1091 TrlrLampCtl_D_Stat 1;
BA_ "U_P552_MY15_Gas_Tx" SG_ 1091 TrlrLampCtl_D_Stat 1;
BA_ "U_C489_MY14_Gas_Tx" SG_ 1091 TrlrLampCtl_D_Stat 1;
BA_ "U_UP375_MY15_Gas_Tx" SG_ 1091 TrlrLampCtl_D_Stat 1;
BA_ "U_UP375_MY15_Diesel_Tx" SG_ 1091 TrlrLampCtl_D_Stat 1;
BA_ "CrossOver_InfoCAN" SG_ 1091 TrlrBattChrg_D_Stat 1;
BA_ "GenSigSendType" SG_ 1091 TrlrBattChrg_D_Stat 3;
BA_ "U_CD4_MY13_Diesel_Tx" SG_ 1091 TrlrBattChrg_D_Stat 1;
BA_ "U_CD4_MY13_Gas_Tx" SG_ 1091 TrlrBattChrg_D_Stat 1;
BA_ "U_CD4_MY13_Hev_Tx" SG_ 1091 TrlrBattChrg_D_Stat 1;
BA_ "U_CD4_MY13_Phev_Tx" SG_ 1091 TrlrBattChrg_D_Stat 1;
BA_ "U_CD42_MY14_Diesel_Tx" SG_ 1091 TrlrBattChrg_D_Stat 1;
BA_ "U_CD42_MY14_Gas_Tx" SG_ 1091 TrlrBattChrg_D_Stat 1;
BA_ "U_P552_MY15_Gas_Tx" SG_ 1091 TrlrBattChrg_D_Stat 1;
BA_ "U_C489_MY14_Gas_Tx" SG_ 1091 TrlrBattChrg_D_Stat 1;
BA_ "U_UP375_MY15_Gas_Tx" SG_ 1091 TrlrBattChrg_D_Stat 1;
BA_ "U_UP375_MY15_Diesel_Tx" SG_ 1091 TrlrBattChrg_D_Stat 1;
BA_ "CrossOver_InfoCAN" SG_ 1091 StopLampTrlrOut_B_Stat 1;
BA_ "GenSigSendType" SG_ 1091 StopLampTrlrOut_B_Stat 3;
BA_ "U_CD4_MY13_Diesel_Tx" SG_ 1091 StopLampTrlrOut_B_Stat 1;
BA_ "U_CD4_MY13_Gas_Tx" SG_ 1091 StopLampTrlrOut_B_Stat 1;
BA_ "U_CD4_MY13_Hev_Tx" SG_ 1091 StopLampTrlrOut_B_Stat 1;
BA_ "U_CD4_MY13_Phev_Tx" SG_ 1091 StopLampTrlrOut_B_Stat 1;
BA_ "U_CD42_MY14_Diesel_Tx" SG_ 1091 StopLampTrlrOut_B_Stat 1;
BA_ "U_CD42_MY14_Gas_Tx" SG_ 1091 StopLampTrlrOut_B_Stat 1;
BA_ "U_P552_MY15_Gas_Tx" SG_ 1091 StopLampTrlrOut_B_Stat 1;
BA_ "U_C489_MY14_Gas_Tx" SG_ 1091 StopLampTrlrOut_B_Stat 1;
BA_ "U_UP375_MY15_Gas_Tx" SG_ 1091 StopLampTrlrOut_B_Stat 1;
BA_ "U_UP375_MY15_Diesel_Tx" SG_ 1091 StopLampTrlrOut_B_Stat 1;
BA_ "CrossOver_InfoCAN" SG_ 1091 TurnLampTrlrRr_B_Stat 1;
BA_ "GenSigSendType" SG_ 1091 TurnLampTrlrRr_B_Stat 3;
BA_ "U_CD4_MY13_Diesel_Tx" SG_ 1091 TurnLampTrlrRr_B_Stat 1;
BA_ "U_CD4_MY13_Gas_Tx" SG_ 1091 TurnLampTrlrRr_B_Stat 1;
BA_ "U_CD4_MY13_Hev_Tx" SG_ 1091 TurnLampTrlrRr_B_Stat 1;
BA_ "U_CD4_MY13_Phev_Tx" SG_ 1091 TurnLampTrlrRr_B_Stat 1;
BA_ "U_CD42_MY14_Diesel_Tx" SG_ 1091 TurnLampTrlrRr_B_Stat 1;
BA_ "U_CD42_MY14_Gas_Tx" SG_ 1091 TurnLampTrlrRr_B_Stat 1;
BA_ "U_P552_MY15_Gas_Tx" SG_ 1091 TurnLampTrlrRr_B_Stat 1;
BA_ "U_C489_MY14_Gas_Tx" SG_ 1091 TurnLampTrlrRr_B_Stat 1;
BA_ "U_UP375_MY15_Gas_Tx" SG_ 1091 TurnLampTrlrRr_B_Stat 1;
BA_ "U_UP375_MY15_Diesel_Tx" SG_ 1091 TurnLampTrlrRr_B_Stat 1;
BA_ "CrossOver_InfoCAN" SG_ 1091 TurnLampTrlrRl_B_Stat 1;
BA_ "GenSigSendType" SG_ 1091 TurnLampTrlrRl_B_Stat 3;
BA_ "U_CD4_MY13_Diesel_Tx" SG_ 1091 TurnLampTrlrRl_B_Stat 1;
BA_ "U_CD4_MY13_Gas_Tx" SG_ 1091 TurnLampTrlrRl_B_Stat 1;
BA_ "U_CD4_MY13_Hev_Tx" SG_ 1091 TurnLampTrlrRl_B_Stat 1;
BA_ "U_CD4_MY13_Phev_Tx" SG_ 1091 TurnLampTrlrRl_B_Stat 1;
BA_ "U_CD42_MY14_Diesel_Tx" SG_ 1091 TurnLampTrlrRl_B_Stat 1;
BA_ "U_CD42_MY14_Gas_Tx" SG_ 1091 TurnLampTrlrRl_B_Stat 1;
BA_ "U_P552_MY15_Gas_Tx" SG_ 1091 TurnLampTrlrRl_B_Stat 1;
BA_ "U_C489_MY14_Gas_Tx" SG_ 1091 TurnLampTrlrRl_B_Stat 1;
BA_ "U_UP375_MY15_Gas_Tx" SG_ 1091 TurnLampTrlrRl_B_Stat 1;
BA_ "U_UP375_MY15_Diesel_Tx" SG_ 1091 TurnLampTrlrRl_B_Stat 1;
BA_ "CrossOver_InfoCAN" SG_ 1091 TrlrLampCnnct_B_Actl 1;
BA_ "GenSigSendType" SG_ 1091 TrlrLampCnnct_B_Actl 3;
BA_ "U_CD4_MY13_Diesel_Rx" SG_ 1091 TrlrLampCnnct_B_Actl 1;
BA_ "U_CD4_MY13_Gas_Rx" SG_ 1091 TrlrLampCnnct_B_Actl 1;
BA_ "U_CD4_MY13_Hev_Rx" SG_ 1091 TrlrLampCnnct_B_Actl 1;
BA_ "U_CD4_MY13_Phev_Rx" SG_ 1091 TrlrLampCnnct_B_Actl 1;
BA_ "U_CD42_MY14_Diesel_Rx" SG_ 1091 TrlrLampCnnct_B_Actl 1;
BA_ "U_CD42_MY14_Gas_Rx" SG_ 1091 TrlrLampCnnct_B_Actl 1;
BA_ "U_P552_MY15_Gas_Rx" SG_ 1091 TrlrLampCnnct_B_Actl 1;
BA_ "U_S550_MY15_Gas_Rx" SG_ 1091 TrlrLampCnnct_B_Actl 1;
BA_ "U_C489_MY14_Gas_Rx" SG_ 1091 TrlrLampCnnct_B_Actl 1;
BA_ "U_B562LC_MY14_Gas_Rx" SG_ 1091 TrlrLampCnnct_B_Actl 1;
BA_ "U_UP375_MY15_Gas_Rx" SG_ 1091 TrlrLampCnnct_B_Actl 1;
BA_ "U_UP375_MY15_Diesel_Rx" SG_ 1091 TrlrLampCnnct_B_Actl 1;
BA_ "U_CD4_MY13_Diesel_Tx" SG_ 1091 TrlrLampCnnct_B_Actl 1;
BA_ "U_CD4_MY13_Gas_Tx" SG_ 1091 TrlrLampCnnct_B_Actl 1;
BA_ "U_CD4_MY13_Hev_Tx" SG_ 1091 TrlrLampCnnct_B_Actl 1;
BA_ "U_CD4_MY13_Phev_Tx" SG_ 1091 TrlrLampCnnct_B_Actl 1;
BA_ "U_CD42_MY14_Diesel_Tx" SG_ 1091 TrlrLampCnnct_B_Actl 1;
BA_ "U_CD42_MY14_Gas_Tx" SG_ 1091 TrlrLampCnnct_B_Actl 1;
BA_ "U_P552_MY15_Gas_Tx" SG_ 1091 TrlrLampCnnct_B_Actl 1;
BA_ "U_C489_MY14_Gas_Tx" SG_ 1091 TrlrLampCnnct_B_Actl 1;
BA_ "U_UP375_MY15_Gas_Tx" SG_ 1091 TrlrLampCnnct_B_Actl 1;
BA_ "U_UP375_MY15_Diesel_Tx" SG_ 1091 TrlrLampCnnct_B_Actl 1;
BA_ "GenSigSendType" SG_ 1285 PDM_Network_Mgmt 3;
BA_ "U_CD4_MY13_Diesel_Rx" SG_ 1285 PDM_Network_Mgmt 1;
BA_ "U_CD4_MY13_Gas_Rx" SG_ 1285 PDM_Network_Mgmt 1;
BA_ "U_CD4_MY13_Hev_Rx" SG_ 1285 PDM_Network_Mgmt 1;
BA_ "U_CD4_MY13_Phev_Rx" SG_ 1285 PDM_Network_Mgmt 1;
BA_ "U_CD42_MY14_Diesel_Rx" SG_ 1285 PDM_Network_Mgmt 1;
BA_ "U_CD42_MY14_Gas_Rx" SG_ 1285 PDM_Network_Mgmt 1;
BA_ "U_P552_MY15_Gas_Rx" SG_ 1285 PDM_Network_Mgmt 1;
BA_ "U_C489_MY14_Gas_Rx" SG_ 1285 PDM_Network_Mgmt 1;
BA_ "U_UP375_MY15_Gas_Rx" SG_ 1285 PDM_Network_Mgmt 1;
BA_ "U_UP375_MY15_Diesel_Rx" SG_ 1285 PDM_Network_Mgmt 1;
BA_ "U_S550_MY15_Gas_Rx" SG_ 1285 PDM_Network_Mgmt 1;
BA_ "U_U502_MY15_Gas_Rx" SG_ 1285 PDM_Network_Mgmt 1;
BA_ "U_CD43_MY16_Gas_Rx" SG_ 1285 PDM_Network_Mgmt 1;
BA_ "U_CD4_MY14_Diesel_Rx" SG_ 1285 PDM_Network_Mgmt 1;
BA_ "U_CD4_MY14_Gas_Rx" SG_ 1285 PDM_Network_Mgmt 1;
BA_ "U_CD4_MY14_Hev_Rx" SG_ 1285 PDM_Network_Mgmt 1;
BA_ "U_CD4_MY14_Phev_Rx" SG_ 1285 PDM_Network_Mgmt 1;
BA_ "U_CD4_MY13_Diesel_Tx" SG_ 1285 PDM_Network_Mgmt 1;
BA_ "U_CD4_MY13_Gas_Tx" SG_ 1285 PDM_Network_Mgmt 1;
BA_ "U_CD4_MY13_Hev_Tx" SG_ 1285 PDM_Network_Mgmt 1;
BA_ "U_CD4_MY13_Phev_Tx" SG_ 1285 PDM_Network_Mgmt 1;
BA_ "U_CD42_MY14_Diesel_Tx" SG_ 1285 PDM_Network_Mgmt 1;
BA_ "U_CD42_MY14_Gas_Tx" SG_ 1285 PDM_Network_Mgmt 1;
BA_ "U_P552_MY15_Gas_Tx" SG_ 1285 PDM_Network_Mgmt 1;
BA_ "U_S550_MY15_Gas_Tx" SG_ 1285 PDM_Network_Mgmt 1;
BA_ "U_C489_MY14_Gas_Tx" SG_ 1285 PDM_Network_Mgmt 1;
BA_ "U_U502_MY15_Gas_Tx" SG_ 1285 PDM_Network_Mgmt 1;
BA_ "U_UP375_MY15_Gas_Tx" SG_ 1285 PDM_Network_Mgmt 1;
BA_ "U_UP375_MY15_Diesel_Tx" SG_ 1285 PDM_Network_Mgmt 1;
BA_ "U_CD43_MY16_Gas_Tx" SG_ 1285 PDM_Network_Mgmt 1;
BA_ "U_CD4_MY14_Diesel_Tx" SG_ 1285 PDM_Network_Mgmt 1;
BA_ "U_CD4_MY14_Gas_Tx" SG_ 1285 PDM_Network_Mgmt 1;
BA_ "U_CD4_MY14_Hev_Tx" SG_ 1285 PDM_Network_Mgmt 1;
BA_ "U_CD4_MY14_Phev_Tx" SG_ 1285 PDM_Network_Mgmt 1;
BA_ "GenSigSendType" SG_ 1865 TesterPhysicalResPDM 3;
BA_ "U_CD4_MY13_Diesel_Tx" SG_ 1865 TesterPhysicalResPDM 1;
BA_ "U_CD4_MY13_Gas_Tx" SG_ 1865 TesterPhysicalResPDM 1;
BA_ "U_CD4_MY13_Hev_Tx" SG_ 1865 TesterPhysicalResPDM 1;
BA_ "U_CD4_MY13_Phev_Tx" SG_ 1865 TesterPhysicalResPDM 1;
BA_ "U_CD42_MY14_Diesel_Tx" SG_ 1865 TesterPhysicalResPDM 1;
BA_ "U_CD42_MY14_Gas_Tx" SG_ 1865 TesterPhysicalResPDM 1;
BA_ "U_P552_MY15_Gas_Tx" SG_ 1865 TesterPhysicalResPDM 1;
BA_ "U_S550_MY15_Gas_Tx" SG_ 1865 TesterPhysicalResPDM 1;
BA_ "U_C489_MY14_Gas_Tx" SG_ 1865 TesterPhysicalResPDM 1;
BA_ "U_U502_MY15_Gas_Tx" SG_ 1865 TesterPhysicalResPDM 1;
BA_ "U_UP375_MY15_Gas_Tx" SG_ 1865 TesterPhysicalResPDM 1;
BA_ "U_UP375_MY15_Diesel_Tx" SG_ 1865 TesterPhysicalResPDM 1;
BA_ "U_CD43_MY16_Gas_Tx" SG_ 1865 TesterPhysicalResPDM 1;
BA_ "U_CD4_MY14_Diesel_Tx" SG_ 1865 TesterPhysicalResPDM 1;
BA_ "U_CD4_MY14_Gas_Tx" SG_ 1865 TesterPhysicalResPDM 1;
BA_ "U_CD4_MY14_Hev_Tx" SG_ 1865 TesterPhysicalResPDM 1;
BA_ "U_CD4_MY14_Phev_Tx" SG_ 1865 TesterPhysicalResPDM 1;
BA_ "GenSigSendType" SG_ 1857 TesterPhysicalReqPDM 3;
BA_ "U_CD4_MY13_Diesel_Rx" SG_ 1857 TesterPhysicalReqPDM 1;
BA_ "U_CD4_MY13_Gas_Rx" SG_ 1857 TesterPhysicalReqPDM 1;
BA_ "U_CD4_MY13_Hev_Rx" SG_ 1857 TesterPhysicalReqPDM 1;
BA_ "U_CD4_MY13_Phev_Rx" SG_ 1857 TesterPhysicalReqPDM 1;
BA_ "U_CD42_MY14_Diesel_Rx" SG_ 1857 TesterPhysicalReqPDM 1;
BA_ "U_CD42_MY14_Gas_Rx" SG_ 1857 TesterPhysicalReqPDM 1;
BA_ "U_P552_MY15_Gas_Rx" SG_ 1857 TesterPhysicalReqPDM 1;
BA_ "U_S550_MY15_Gas_Rx" SG_ 1857 TesterPhysicalReqPDM 1;
BA_ "U_C489_MY14_Gas_Rx" SG_ 1857 TesterPhysicalReqPDM 1;
BA_ "U_U502_MY15_Gas_Rx" SG_ 1857 TesterPhysicalReqPDM 1;
BA_ "U_UP375_MY15_Gas_Rx" SG_ 1857 TesterPhysicalReqPDM 1;
BA_ "U_UP375_MY15_Diesel_Rx" SG_ 1857 TesterPhysicalReqPDM 1;
BA_ "U_CD43_MY16_Gas_Rx" SG_ 1857 TesterPhysicalReqPDM 1;
BA_ "U_CD4_MY14_Diesel_Rx" SG_ 1857 TesterPhysicalReqPDM 1;
BA_ "U_CD4_MY14_Gas_Rx" SG_ 1857 TesterPhysicalReqPDM 1;
BA_ "U_CD4_MY14_Hev_Rx" SG_ 1857 TesterPhysicalReqPDM 1;
BA_ "U_CD4_MY14_Phev_Rx" SG_ 1857 TesterPhysicalReqPDM 1;
BA_ "GenSigSendType" SG_ 1819 TesterPhysicalResSCMH 3;
BA_ "U_CD4_MY13_Diesel_Tx" SG_ 1819 TesterPhysicalResSCMH 1;
BA_ "U_CD4_MY13_Gas_Tx" SG_ 1819 TesterPhysicalResSCMH 1;
BA_ "U_CD4_MY13_Hev_Tx" SG_ 1819 TesterPhysicalResSCMH 1;
BA_ "U_CD4_MY13_Phev_Tx" SG_ 1819 TesterPhysicalResSCMH 1;
BA_ "U_CD42_MY14_Diesel_Tx" SG_ 1819 TesterPhysicalResSCMH 1;
BA_ "U_CD42_MY14_Gas_Tx" SG_ 1819 TesterPhysicalResSCMH 1;
BA_ "U_P552_MY15_Gas_Tx" SG_ 1819 TesterPhysicalResSCMH 1;
BA_ "U_U502_MY15_Gas_Tx" SG_ 1819 TesterPhysicalResSCMH 1;
BA_ "U_CD43_MY16_Gas_Tx" SG_ 1819 TesterPhysicalResSCMH 1;
BA_ "GenSigSendType" SG_ 1818 TesterPhysicalResSCMG 3;
BA_ "U_CD4_MY13_Diesel_Tx" SG_ 1818 TesterPhysicalResSCMG 1;
BA_ "U_CD4_MY13_Gas_Tx" SG_ 1818 TesterPhysicalResSCMG 1;
BA_ "U_CD4_MY13_Hev_Tx" SG_ 1818 TesterPhysicalResSCMG 1;
BA_ "U_CD4_MY13_Phev_Tx" SG_ 1818 TesterPhysicalResSCMG 1;
BA_ "U_CD42_MY14_Diesel_Tx" SG_ 1818 TesterPhysicalResSCMG 1;
BA_ "U_CD42_MY14_Gas_Tx" SG_ 1818 TesterPhysicalResSCMG 1;
BA_ "U_P552_MY15_Gas_Tx" SG_ 1818 TesterPhysicalResSCMG 1;
BA_ "U_U502_MY15_Gas_Tx" SG_ 1818 TesterPhysicalResSCMG 1;
BA_ "U_CD43_MY16_Gas_Tx" SG_ 1818 TesterPhysicalResSCMG 1;
BA_ "GenSigSendType" SG_ 1811 TesterPhysicalReqSCMH 3;
BA_ "U_CD4_MY13_Diesel_Rx" SG_ 1811 TesterPhysicalReqSCMH 1;
BA_ "U_CD4_MY13_Gas_Rx" SG_ 1811 TesterPhysicalReqSCMH 1;
BA_ "U_CD4_MY13_Hev_Rx" SG_ 1811 TesterPhysicalReqSCMH 1;
BA_ "U_CD4_MY13_Phev_Rx" SG_ 1811 TesterPhysicalReqSCMH 1;
BA_ "U_CD42_MY14_Diesel_Rx" SG_ 1811 TesterPhysicalReqSCMH 1;
BA_ "U_CD42_MY14_Gas_Rx" SG_ 1811 TesterPhysicalReqSCMH 1;
BA_ "U_P552_MY15_Gas_Rx" SG_ 1811 TesterPhysicalReqSCMH 1;
BA_ "U_U502_MY15_Gas_Rx" SG_ 1811 TesterPhysicalReqSCMH 1;
BA_ "U_CD43_MY16_Gas_Rx" SG_ 1811 TesterPhysicalReqSCMH 1;
BA_ "GenSigSendType" SG_ 1810 TesterPhysicalReqSCMG 3;
BA_ "U_CD4_MY13_Diesel_Rx" SG_ 1810 TesterPhysicalReqSCMG 1;
BA_ "U_CD4_MY13_Gas_Rx" SG_ 1810 TesterPhysicalReqSCMG 1;
BA_ "U_CD4_MY13_Hev_Rx" SG_ 1810 TesterPhysicalReqSCMG 1;
BA_ "U_CD4_MY13_Phev_Rx" SG_ 1810 TesterPhysicalReqSCMG 1;
BA_ "U_CD42_MY14_Diesel_Rx" SG_ 1810 TesterPhysicalReqSCMG 1;
BA_ "U_CD42_MY14_Gas_Rx" SG_ 1810 TesterPhysicalReqSCMG 1;
BA_ "U_P552_MY15_Gas_Rx" SG_ 1810 TesterPhysicalReqSCMG 1;
BA_ "U_U502_MY15_Gas_Rx" SG_ 1810 TesterPhysicalReqSCMG 1;
BA_ "U_CD43_MY16_Gas_Rx" SG_ 1810 TesterPhysicalReqSCMG 1;
BA_ "GenSigSendType" SG_ 1373 FCIM_Network_Mgmt 3;
BA_ "U_CD4_MY13_Diesel_Rx" SG_ 1373 FCIM_Network_Mgmt 1;
BA_ "U_CD4_MY13_Gas_Rx" SG_ 1373 FCIM_Network_Mgmt 1;
BA_ "U_CD4_MY13_Hev_Rx" SG_ 1373 FCIM_Network_Mgmt 1;
BA_ "U_CD4_MY13_Phev_Rx" SG_ 1373 FCIM_Network_Mgmt 1;
BA_ "U_CD42_MY14_Diesel_Rx" SG_ 1373 FCIM_Network_Mgmt 1;
BA_ "U_CD42_MY14_Gas_Rx" SG_ 1373 FCIM_Network_Mgmt 1;
BA_ "U_P552_MY15_Gas_Rx" SG_ 1373 FCIM_Network_Mgmt 1;
BA_ "U_C489_MY14_Gas_Rx" SG_ 1373 FCIM_Network_Mgmt 1;
BA_ "U_UP375_MY15_Gas_Rx" SG_ 1373 FCIM_Network_Mgmt 1;
BA_ "U_UP375_MY15_Diesel_Rx" SG_ 1373 FCIM_Network_Mgmt 1;
BA_ "U_S550_MY15_Gas_Rx" SG_ 1373 FCIM_Network_Mgmt 1;
BA_ "U_U502_MY15_Gas_Rx" SG_ 1373 FCIM_Network_Mgmt 1;
BA_ "U_CD43_MY16_Gas_Rx" SG_ 1373 FCIM_Network_Mgmt 1;
BA_ "U_CD4_MY14_Diesel_Rx" SG_ 1373 FCIM_Network_Mgmt 1;
BA_ "U_CD4_MY14_Gas_Rx" SG_ 1373 FCIM_Network_Mgmt 1;
BA_ "U_CD4_MY14_Hev_Rx" SG_ 1373 FCIM_Network_Mgmt 1;
BA_ "U_CD4_MY14_Phev_Rx" SG_ 1373 FCIM_Network_Mgmt 1;
BA_ "U_CD4_MY13_Diesel_Tx" SG_ 1373 FCIM_Network_Mgmt 1;
BA_ "U_CD4_MY13_Gas_Tx" SG_ 1373 FCIM_Network_Mgmt 1;
BA_ "U_CD4_MY13_Hev_Tx" SG_ 1373 FCIM_Network_Mgmt 1;
BA_ "U_CD4_MY13_Phev_Tx" SG_ 1373 FCIM_Network_Mgmt 1;
BA_ "U_CD42_MY14_Diesel_Tx" SG_ 1373 FCIM_Network_Mgmt 1;
BA_ "U_CD42_MY14_Gas_Tx" SG_ 1373 FCIM_Network_Mgmt 1;
BA_ "U_P552_MY15_Gas_Tx" SG_ 1373 FCIM_Network_Mgmt 1;
BA_ "U_S550_MY15_Gas_Tx" SG_ 1373 FCIM_Network_Mgmt 1;
BA_ "U_C489_MY14_Gas_Tx" SG_ 1373 FCIM_Network_Mgmt 1;
BA_ "U_U502_MY15_Gas_Tx" SG_ 1373 FCIM_Network_Mgmt 1;
BA_ "U_UP375_MY15_Gas_Tx" SG_ 1373 FCIM_Network_Mgmt 1;
BA_ "U_UP375_MY15_Diesel_Tx" SG_ 1373 FCIM_Network_Mgmt 1;
BA_ "U_CD43_MY16_Gas_Tx" SG_ 1373 FCIM_Network_Mgmt 1;
BA_ "GenSigSendType" SG_ 1339 RTM_Network_Mgmt 3;
BA_ "U_CD4_MY13_Diesel_Rx" SG_ 1339 RTM_Network_Mgmt 1;
BA_ "U_CD4_MY13_Gas_Rx" SG_ 1339 RTM_Network_Mgmt 1;
BA_ "U_CD4_MY13_Hev_Rx" SG_ 1339 RTM_Network_Mgmt 1;
BA_ "U_CD4_MY13_Phev_Rx" SG_ 1339 RTM_Network_Mgmt 1;
BA_ "U_CD42_MY14_Diesel_Rx" SG_ 1339 RTM_Network_Mgmt 1;
BA_ "U_CD42_MY14_Gas_Rx" SG_ 1339 RTM_Network_Mgmt 1;
BA_ "U_P552_MY15_Gas_Rx" SG_ 1339 RTM_Network_Mgmt 1;
BA_ "U_S550_MY15_Gas_Rx" SG_ 1339 RTM_Network_Mgmt 1;
BA_ "U_C489_MY14_Gas_Rx" SG_ 1339 RTM_Network_Mgmt 1;
BA_ "U_U502_MY15_Gas_Rx" SG_ 1339 RTM_Network_Mgmt 1;
BA_ "U_UP375_MY15_Gas_Rx" SG_ 1339 RTM_Network_Mgmt 1;
BA_ "U_UP375_MY15_Diesel_Rx" SG_ 1339 RTM_Network_Mgmt 1;
BA_ "U_CD43_MY16_Gas_Rx" SG_ 1339 RTM_Network_Mgmt 1;
BA_ "U_CD4_MY14_Diesel_Rx" SG_ 1339 RTM_Network_Mgmt 1;
BA_ "U_CD4_MY14_Gas_Rx" SG_ 1339 RTM_Network_Mgmt 1;
BA_ "U_CD4_MY14_Hev_Rx" SG_ 1339 RTM_Network_Mgmt 1;
BA_ "U_CD4_MY14_Phev_Rx" SG_ 1339 RTM_Network_Mgmt 1;
BA_ "U_CD4_MY13_Diesel_Tx" SG_ 1339 RTM_Network_Mgmt 1;
BA_ "U_CD4_MY13_Gas_Tx" SG_ 1339 RTM_Network_Mgmt 1;
BA_ "U_CD4_MY13_Hev_Tx" SG_ 1339 RTM_Network_Mgmt 1;
BA_ "U_CD4_MY13_Phev_Tx" SG_ 1339 RTM_Network_Mgmt 1;
BA_ "U_CD42_MY14_Diesel_Tx" SG_ 1339 RTM_Network_Mgmt 1;
BA_ "U_CD42_MY14_Gas_Tx" SG_ 1339 RTM_Network_Mgmt 1;
BA_ "U_P552_MY15_Gas_Tx" SG_ 1339 RTM_Network_Mgmt 1;
BA_ "U_S550_MY15_Gas_Tx" SG_ 1339 RTM_Network_Mgmt 1;
BA_ "U_C489_MY14_Gas_Tx" SG_ 1339 RTM_Network_Mgmt 1;
BA_ "U_U502_MY15_Gas_Tx" SG_ 1339 RTM_Network_Mgmt 1;
BA_ "U_UP375_MY15_Gas_Tx" SG_ 1339 RTM_Network_Mgmt 1;
BA_ "U_UP375_MY15_Diesel_Tx" SG_ 1339 RTM_Network_Mgmt 1;
BA_ "U_CD43_MY16_Gas_Tx" SG_ 1339 RTM_Network_Mgmt 1;
BA_ "GenSigSendType" SG_ 1310 GWM_Network_Mgmt_MS1 3;
BA_ "U_CD4_MY13_Diesel_Rx" SG_ 1310 GWM_Network_Mgmt_MS1 1;
BA_ "U_CD4_MY13_Gas_Rx" SG_ 1310 GWM_Network_Mgmt_MS1 1;
BA_ "U_CD4_MY13_Hev_Rx" SG_ 1310 GWM_Network_Mgmt_MS1 1;
BA_ "U_CD4_MY13_Phev_Rx" SG_ 1310 GWM_Network_Mgmt_MS1 1;
BA_ "U_CD42_MY14_Diesel_Rx" SG_ 1310 GWM_Network_Mgmt_MS1 1;
BA_ "U_CD42_MY14_Gas_Rx" SG_ 1310 GWM_Network_Mgmt_MS1 1;
BA_ "U_P552_MY15_Gas_Rx" SG_ 1310 GWM_Network_Mgmt_MS1 1;
BA_ "U_C489_MY14_Gas_Rx" SG_ 1310 GWM_Network_Mgmt_MS1 1;
BA_ "U_UP375_MY15_Gas_Rx" SG_ 1310 GWM_Network_Mgmt_MS1 1;
BA_ "U_UP375_MY15_Diesel_Rx" SG_ 1310 GWM_Network_Mgmt_MS1 1;
BA_ "U_S550_MY15_Gas_Rx" SG_ 1310 GWM_Network_Mgmt_MS1 1;
BA_ "U_U502_MY15_Gas_Rx" SG_ 1310 GWM_Network_Mgmt_MS1 1;
BA_ "U_CD43_MY16_Gas_Rx" SG_ 1310 GWM_Network_Mgmt_MS1 1;
BA_ "U_CD4_MY14_Diesel_Rx" SG_ 1310 GWM_Network_Mgmt_MS1 1;
BA_ "U_CD4_MY14_Gas_Rx" SG_ 1310 GWM_Network_Mgmt_MS1 1;
BA_ "U_CD4_MY14_Hev_Rx" SG_ 1310 GWM_Network_Mgmt_MS1 1;
BA_ "U_CD4_MY14_Phev_Rx" SG_ 1310 GWM_Network_Mgmt_MS1 1;
BA_ "U_CD4_MY13_Diesel_Rx" SG_ 1066 BattULo_U_Actl_UB 1;
BA_ "U_CD4_MY13_Gas_Rx" SG_ 1066 BattULo_U_Actl_UB 1;
BA_ "U_CD4_MY13_Hev_Rx" SG_ 1066 BattULo_U_Actl_UB 1;
BA_ "U_CD4_MY13_Phev_Rx" SG_ 1066 BattULo_U_Actl_UB 1;
BA_ "U_CD42_MY14_Diesel_Rx" SG_ 1066 BattULo_U_Actl_UB 1;
BA_ "U_CD42_MY14_Gas_Rx" SG_ 1066 BattULo_U_Actl_UB 1;
BA_ "U_P552_MY15_Gas_Rx" SG_ 1066 BattULo_U_Actl_UB 1;
BA_ "U_S550_MY15_Gas_Rx" SG_ 1066 BattULo_U_Actl_UB 1;
BA_ "U_C489_MY14_Gas_Rx" SG_ 1066 BattULo_U_Actl_UB 1;
BA_ "U_U502_MY15_Gas_Rx" SG_ 1066 BattULo_U_Actl_UB 1;
BA_ "U_UP375_MY15_Gas_Rx" SG_ 1066 BattULo_U_Actl_UB 1;
BA_ "U_UP375_MY15_Diesel_Rx" SG_ 1066 BattULo_U_Actl_UB 1;
BA_ "U_CD43_MY16_Gas_Rx" SG_ 1066 BattULo_U_Actl_UB 1;
BA_ "GenSigStartValue" SG_ 1066 BattULo_U_Actl 255;
BA_ "U_CD4_MY13_Diesel_Rx" SG_ 1066 BattULo_U_Actl 1;
BA_ "U_CD4_MY13_Gas_Rx" SG_ 1066 BattULo_U_Actl 1;
BA_ "U_CD4_MY13_Hev_Rx" SG_ 1066 BattULo_U_Actl 1;
BA_ "U_CD4_MY13_Phev_Rx" SG_ 1066 BattULo_U_Actl 1;
BA_ "U_CD42_MY14_Diesel_Rx" SG_ 1066 BattULo_U_Actl 1;
BA_ "U_CD42_MY14_Gas_Rx" SG_ 1066 BattULo_U_Actl 1;
BA_ "U_P552_MY15_Gas_Rx" SG_ 1066 BattULo_U_Actl 1;
BA_ "U_S550_MY15_Gas_Rx" SG_ 1066 BattULo_U_Actl 1;
BA_ "U_C489_MY14_Gas_Rx" SG_ 1066 BattULo_U_Actl 1;
BA_ "U_U502_MY15_Gas_Rx" SG_ 1066 BattULo_U_Actl 1;
BA_ "U_UP375_MY15_Gas_Rx" SG_ 1066 BattULo_U_Actl 1;
BA_ "U_UP375_MY15_Diesel_Rx" SG_ 1066 BattULo_U_Actl 1;
BA_ "U_CD43_MY16_Gas_Rx" SG_ 1066 BattULo_U_Actl 1;
BA_ "U_CD4_MY13_Diesel_Rx" SG_ 1066 PwSrcULo_I_Mx 1;
BA_ "U_CD4_MY13_Gas_Rx" SG_ 1066 PwSrcULo_I_Mx 1;
BA_ "U_CD4_MY13_Hev_Rx" SG_ 1066 PwSrcULo_I_Mx 1;
BA_ "U_CD4_MY13_Phev_Rx" SG_ 1066 PwSrcULo_I_Mx 1;
BA_ "U_CD42_MY14_Diesel_Rx" SG_ 1066 PwSrcULo_I_Mx 1;
BA_ "U_CD42_MY14_Gas_Rx" SG_ 1066 PwSrcULo_I_Mx 1;
BA_ "U_P552_MY15_Gas_Rx" SG_ 1066 PwSrcULo_I_Mx 1;
BA_ "U_S550_MY15_Gas_Rx" SG_ 1066 PwSrcULo_I_Mx 1;
BA_ "U_C489_MY14_Gas_Rx" SG_ 1066 PwSrcULo_I_Mx 1;
BA_ "U_U502_MY15_Gas_Rx" SG_ 1066 PwSrcULo_I_Mx 1;
BA_ "U_UP375_MY15_Gas_Rx" SG_ 1066 PwSrcULo_I_Mx 1;
BA_ "U_UP375_MY15_Diesel_Rx" SG_ 1066 PwSrcULo_I_Mx 1;
BA_ "U_CD43_MY16_Gas_Rx" SG_ 1066 PwSrcULo_I_Mx 1;
BA_ "U_CD4_MY13_Diesel_Rx" SG_ 1066 PwSrcULo_I_Actl 1;
BA_ "U_CD4_MY13_Gas_Rx" SG_ 1066 PwSrcULo_I_Actl 1;
BA_ "U_CD4_MY13_Hev_Rx" SG_ 1066 PwSrcULo_I_Actl 1;
BA_ "U_CD4_MY13_Phev_Rx" SG_ 1066 PwSrcULo_I_Actl 1;
BA_ "U_CD42_MY14_Diesel_Rx" SG_ 1066 PwSrcULo_I_Actl 1;
BA_ "U_CD42_MY14_Gas_Rx" SG_ 1066 PwSrcULo_I_Actl 1;
BA_ "U_P552_MY15_Gas_Rx" SG_ 1066 PwSrcULo_I_Actl 1;
BA_ "U_S550_MY15_Gas_Rx" SG_ 1066 PwSrcULo_I_Actl 1;
BA_ "U_C489_MY14_Gas_Rx" SG_ 1066 PwSrcULo_I_Actl 1;
BA_ "U_U502_MY15_Gas_Rx" SG_ 1066 PwSrcULo_I_Actl 1;
BA_ "U_UP375_MY15_Gas_Rx" SG_ 1066 PwSrcULo_I_Actl 1;
BA_ "U_UP375_MY15_Diesel_Rx" SG_ 1066 PwSrcULo_I_Actl 1;
BA_ "U_CD43_MY16_Gas_Rx" SG_ 1066 PwSrcULo_I_Actl 1;
BA_ "U_CD4_MY13_Diesel_Rx" SG_ 1066 PwSrcULo_I_Mx_UB 1;
BA_ "U_CD4_MY13_Gas_Rx" SG_ 1066 PwSrcULo_I_Mx_UB 1;
BA_ "U_CD4_MY13_Hev_Rx" SG_ 1066 PwSrcULo_I_Mx_UB 1;
BA_ "U_CD4_MY13_Phev_Rx" SG_ 1066 PwSrcULo_I_Mx_UB 1;
BA_ "U_CD42_MY14_Diesel_Rx" SG_ 1066 PwSrcULo_I_Mx_UB 1;
BA_ "U_CD42_MY14_Gas_Rx" SG_ 1066 PwSrcULo_I_Mx_UB 1;
BA_ "U_P552_MY15_Gas_Rx" SG_ 1066 PwSrcULo_I_Mx_UB 1;
BA_ "U_S550_MY15_Gas_Rx" SG_ 1066 PwSrcULo_I_Mx_UB 1;
BA_ "U_C489_MY14_Gas_Rx" SG_ 1066 PwSrcULo_I_Mx_UB 1;
BA_ "U_U502_MY15_Gas_Rx" SG_ 1066 PwSrcULo_I_Mx_UB 1;
BA_ "U_UP375_MY15_Gas_Rx" SG_ 1066 PwSrcULo_I_Mx_UB 1;
BA_ "U_UP375_MY15_Diesel_Rx" SG_ 1066 PwSrcULo_I_Mx_UB 1;
BA_ "U_CD43_MY16_Gas_Rx" SG_ 1066 PwSrcULo_I_Mx_UB 1;
BA_ "U_CD4_MY13_Diesel_Rx" SG_ 1066 PwSrcULo_I_Actl_UB 1;
BA_ "U_CD4_MY13_Gas_Rx" SG_ 1066 PwSrcULo_I_Actl_UB 1;
BA_ "U_CD4_MY13_Hev_Rx" SG_ 1066 PwSrcULo_I_Actl_UB 1;
BA_ "U_CD4_MY13_Phev_Rx" SG_ 1066 PwSrcULo_I_Actl_UB 1;
BA_ "U_CD42_MY14_Diesel_Rx" SG_ 1066 PwSrcULo_I_Actl_UB 1;
BA_ "U_CD42_MY14_Gas_Rx" SG_ 1066 PwSrcULo_I_Actl_UB 1;
BA_ "U_P552_MY15_Gas_Rx" SG_ 1066 PwSrcULo_I_Actl_UB 1;
BA_ "U_S550_MY15_Gas_Rx" SG_ 1066 PwSrcULo_I_Actl_UB 1;
BA_ "U_C489_MY14_Gas_Rx" SG_ 1066 PwSrcULo_I_Actl_UB 1;
BA_ "U_U502_MY15_Gas_Rx" SG_ 1066 PwSrcULo_I_Actl_UB 1;
BA_ "U_UP375_MY15_Gas_Rx" SG_ 1066 PwSrcULo_I_Actl_UB 1;
BA_ "U_UP375_MY15_Diesel_Rx" SG_ 1066 PwSrcULo_I_Actl_UB 1;
BA_ "U_CD43_MY16_Gas_Rx" SG_ 1066 PwSrcULo_I_Actl_UB 1;
BA_ "CrossOver_InfoCAN" SG_ 994 Pers4OptIn_B_Stats 1;
BA_ "CrossOver_InfoCAN" SG_ 994 Pers3OptIn_B_Stats 1;
BA_ "CrossOver_InfoCAN" SG_ 994 Pers2OptIn_B_Stats 1;
BA_ "CrossOver_InfoCAN" SG_ 994 Pers1OptIn_B_Stats 1;
BA_ "CrossOver_InfoCAN" SG_ 994 CtrStkPersIndex_D_Actl 1;
BA_ "GenSigStartValue" SG_ 994 CtrStkPersIndex_D_Actl 4;
BA_ "U_CD4_MY13_Diesel_Rx" SG_ 994 CtrStkPersIndex_D_Actl 1;
BA_ "U_CD4_MY13_Gas_Rx" SG_ 994 CtrStkPersIndex_D_Actl 1;
BA_ "U_CD4_MY13_Hev_Rx" SG_ 994 CtrStkPersIndex_D_Actl 1;
BA_ "U_CD4_MY13_Phev_Rx" SG_ 994 CtrStkPersIndex_D_Actl 1;
BA_ "U_CD42_MY14_Diesel_Rx" SG_ 994 CtrStkPersIndex_D_Actl 1;
BA_ "U_CD42_MY14_Gas_Rx" SG_ 994 CtrStkPersIndex_D_Actl 1;
BA_ "U_P552_MY15_Gas_Rx" SG_ 994 CtrStkPersIndex_D_Actl 1;
BA_ "U_S550_MY15_Gas_Rx" SG_ 994 CtrStkPersIndex_D_Actl 1;
BA_ "U_C489_MY14_Gas_Rx" SG_ 994 CtrStkPersIndex_D_Actl 1;
BA_ "U_U502_MY15_Gas_Rx" SG_ 994 CtrStkPersIndex_D_Actl 1;
BA_ "U_UP375_MY15_Gas_Rx" SG_ 994 CtrStkPersIndex_D_Actl 1;
BA_ "U_UP375_MY15_Diesel_Rx" SG_ 994 CtrStkPersIndex_D_Actl 1;
BA_ "U_CD43_MY16_Gas_Rx" SG_ 994 CtrStkPersIndex_D_Actl 1;
BA_ "U_CD4_MY14_Diesel_Rx" SG_ 994 CtrStkPersIndex_D_Actl 1;
BA_ "U_CD4_MY14_Gas_Rx" SG_ 994 CtrStkPersIndex_D_Actl 1;
BA_ "U_CD4_MY14_Hev_Rx" SG_ 994 CtrStkPersIndex_D_Actl 1;
BA_ "U_CD4_MY14_Phev_Rx" SG_ 994 CtrStkPersIndex_D_Actl 1;
BA_ "CrossOver_InfoCAN" SG_ 994 CtrStkFeatNoActl 1;
BA_ "U_CD4_MY13_Diesel_Rx" SG_ 994 CtrStkFeatNoActl 1;
BA_ "U_CD4_MY13_Gas_Rx" SG_ 994 CtrStkFeatNoActl 1;
BA_ "U_CD4_MY13_Hev_Rx" SG_ 994 CtrStkFeatNoActl 1;
BA_ "U_CD4_MY13_Phev_Rx" SG_ 994 CtrStkFeatNoActl 1;
BA_ "U_CD42_MY14_Diesel_Rx" SG_ 994 CtrStkFeatNoActl 1;
BA_ "U_CD42_MY14_Gas_Rx" SG_ 994 CtrStkFeatNoActl 1;
BA_ "U_P552_MY15_Gas_Rx" SG_ 994 CtrStkFeatNoActl 1;
BA_ "U_S550_MY15_Gas_Rx" SG_ 994 CtrStkFeatNoActl 1;
BA_ "U_C489_MY14_Gas_Rx" SG_ 994 CtrStkFeatNoActl 1;
BA_ "U_U502_MY15_Gas_Rx" SG_ 994 CtrStkFeatNoActl 1;
BA_ "U_UP375_MY15_Gas_Rx" SG_ 994 CtrStkFeatNoActl 1;
BA_ "U_UP375_MY15_Diesel_Rx" SG_ 994 CtrStkFeatNoActl 1;
BA_ "U_CD43_MY16_Gas_Rx" SG_ 994 CtrStkFeatNoActl 1;
BA_ "U_CD4_MY14_Diesel_Rx" SG_ 994 CtrStkFeatNoActl 1;
BA_ "U_CD4_MY14_Gas_Rx" SG_ 994 CtrStkFeatNoActl 1;
BA_ "U_CD4_MY14_Hev_Rx" SG_ 994 CtrStkFeatNoActl 1;
BA_ "U_CD4_MY14_Phev_Rx" SG_ 994 CtrStkFeatNoActl 1;
BA_ "CrossOver_InfoCAN" SG_ 994 CtrStkFeatConfigActl 1;
BA_ "U_CD4_MY13_Diesel_Rx" SG_ 994 CtrStkFeatConfigActl 1;
BA_ "U_CD4_MY13_Gas_Rx" SG_ 994 CtrStkFeatConfigActl 1;
BA_ "U_CD4_MY13_Hev_Rx" SG_ 994 CtrStkFeatConfigActl 1;
BA_ "U_CD4_MY13_Phev_Rx" SG_ 994 CtrStkFeatConfigActl 1;
BA_ "U_CD42_MY14_Diesel_Rx" SG_ 994 CtrStkFeatConfigActl 1;
BA_ "U_CD42_MY14_Gas_Rx" SG_ 994 CtrStkFeatConfigActl 1;
BA_ "U_P552_MY15_Gas_Rx" SG_ 994 CtrStkFeatConfigActl 1;
BA_ "U_S550_MY15_Gas_Rx" SG_ 994 CtrStkFeatConfigActl 1;
BA_ "U_C489_MY14_Gas_Rx" SG_ 994 CtrStkFeatConfigActl 1;
BA_ "U_U502_MY15_Gas_Rx" SG_ 994 CtrStkFeatConfigActl 1;
BA_ "U_UP375_MY15_Gas_Rx" SG_ 994 CtrStkFeatConfigActl 1;
BA_ "U_UP375_MY15_Diesel_Rx" SG_ 994 CtrStkFeatConfigActl 1;
BA_ "U_CD43_MY16_Gas_Rx" SG_ 994 CtrStkFeatConfigActl 1;
BA_ "U_CD4_MY14_Diesel_Rx" SG_ 994 CtrStkFeatConfigActl 1;
BA_ "U_CD4_MY14_Gas_Rx" SG_ 994 CtrStkFeatConfigActl 1;
BA_ "U_CD4_MY14_Hev_Rx" SG_ 994 CtrStkFeatConfigActl 1;
BA_ "U_CD4_MY14_Phev_Rx" SG_ 994 CtrStkFeatConfigActl 1;
BA_ "CrossOver_InfoCAN" SG_ 994 CtrStkDsplyOp_D_Rq 1;
BA_ "U_CD4_MY13_Diesel_Rx" SG_ 994 CtrStkDsplyOp_D_Rq 1;
BA_ "U_CD4_MY13_Gas_Rx" SG_ 994 CtrStkDsplyOp_D_Rq 1;
BA_ "U_CD4_MY13_Hev_Rx" SG_ 994 CtrStkDsplyOp_D_Rq 1;
BA_ "U_CD4_MY13_Phev_Rx" SG_ 994 CtrStkDsplyOp_D_Rq 1;
BA_ "U_CD42_MY14_Diesel_Rx" SG_ 994 CtrStkDsplyOp_D_Rq 1;
BA_ "U_CD42_MY14_Gas_Rx" SG_ 994 CtrStkDsplyOp_D_Rq 1;
BA_ "U_P552_MY15_Gas_Rx" SG_ 994 CtrStkDsplyOp_D_Rq 1;
BA_ "U_S550_MY15_Gas_Rx" SG_ 994 CtrStkDsplyOp_D_Rq 1;
BA_ "U_C489_MY14_Gas_Rx" SG_ 994 CtrStkDsplyOp_D_Rq 1;
BA_ "U_U502_MY15_Gas_Rx" SG_ 994 CtrStkDsplyOp_D_Rq 1;
BA_ "U_UP375_MY15_Gas_Rx" SG_ 994 CtrStkDsplyOp_D_Rq 1;
BA_ "U_UP375_MY15_Diesel_Rx" SG_ 994 CtrStkDsplyOp_D_Rq 1;
BA_ "U_CD43_MY16_Gas_Rx" SG_ 994 CtrStkDsplyOp_D_Rq 1;
BA_ "U_CD4_MY14_Diesel_Rx" SG_ 994 CtrStkDsplyOp_D_Rq 1;
BA_ "U_CD4_MY14_Gas_Rx" SG_ 994 CtrStkDsplyOp_D_Rq 1;
BA_ "U_CD4_MY14_Hev_Rx" SG_ 994 CtrStkDsplyOp_D_Rq 1;
BA_ "U_CD4_MY14_Phev_Rx" SG_ 994 CtrStkDsplyOp_D_Rq 1;
BA_ "CrossOver_InfoCAN" SG_ 994 PersStore_D_Rq 1;
BA_ "U_CD4_MY13_Diesel_Rx" SG_ 994 PersStore_D_Rq 1;
BA_ "U_CD4_MY13_Gas_Rx" SG_ 994 PersStore_D_Rq 1;
BA_ "U_CD4_MY13_Hev_Rx" SG_ 994 PersStore_D_Rq 1;
BA_ "U_CD4_MY13_Phev_Rx" SG_ 994 PersStore_D_Rq 1;
BA_ "U_CD42_MY14_Diesel_Rx" SG_ 994 PersStore_D_Rq 1;
BA_ "U_CD42_MY14_Gas_Rx" SG_ 994 PersStore_D_Rq 1;
BA_ "U_P552_MY15_Gas_Rx" SG_ 994 PersStore_D_Rq 1;
BA_ "U_S550_MY15_Gas_Rx" SG_ 994 PersStore_D_Rq 1;
BA_ "U_C489_MY14_Gas_Rx" SG_ 994 PersStore_D_Rq 1;
BA_ "U_U502_MY15_Gas_Rx" SG_ 994 PersStore_D_Rq 1;
BA_ "U_CD43_MY16_Gas_Rx" SG_ 994 PersStore_D_Rq 1;
BA_ "CrossOver_InfoCAN" SG_ 376 EngAout_Aa_Actl 1;
BA_ "ContentDependant" SG_ 376 EngAout_Aa_Actl 1;
BA_ "CrossOver_InfoCAN" SG_ 376 AirAmbTe_D_Qf 1;
BA_ "U_CD4_MY13_Diesel_Rx" SG_ 376 AirAmbTe_D_Qf 1;
BA_ "U_CD4_MY13_Gas_Rx" SG_ 376 AirAmbTe_D_Qf 1;
BA_ "U_CD4_MY13_Hev_Rx" SG_ 376 AirAmbTe_D_Qf 1;
BA_ "U_CD4_MY13_Phev_Rx" SG_ 376 AirAmbTe_D_Qf 1;
BA_ "U_CD42_MY14_Diesel_Rx" SG_ 376 AirAmbTe_D_Qf 1;
BA_ "U_CD42_MY14_Gas_Rx" SG_ 376 AirAmbTe_D_Qf 1;
BA_ "U_P552_MY15_Gas_Rx" SG_ 376 AirAmbTe_D_Qf 1;
BA_ "U_S550_MY15_Gas_Rx" SG_ 376 AirAmbTe_D_Qf 1;
BA_ "U_C489_MY14_Gas_Rx" SG_ 376 AirAmbTe_D_Qf 1;
BA_ "U_U502_MY15_Gas_Rx" SG_ 376 AirAmbTe_D_Qf 1;
BA_ "U_UP375_MY15_Gas_Rx" SG_ 376 AirAmbTe_D_Qf 1;
BA_ "U_UP375_MY15_Diesel_Rx" SG_ 376 AirAmbTe_D_Qf 1;
BA_ "U_CD43_MY16_Gas_Rx" SG_ 376 AirAmbTe_D_Qf 1;
BA_ "CrossOver_InfoCAN" SG_ 376 AirAmb_Te_ActlFilt 1;
BA_ "GenSigStartValue" SG_ 376 AirAmb_Te_ActlFilt 512;
BA_ "U_CD4_MY13_Diesel_Rx" SG_ 376 AirAmb_Te_ActlFilt 1;
BA_ "U_CD4_MY13_Gas_Rx" SG_ 376 AirAmb_Te_ActlFilt 1;
BA_ "U_CD4_MY13_Hev_Rx" SG_ 376 AirAmb_Te_ActlFilt 1;
BA_ "U_CD4_MY13_Phev_Rx" SG_ 376 AirAmb_Te_ActlFilt 1;
BA_ "U_CD42_MY14_Diesel_Rx" SG_ 376 AirAmb_Te_ActlFilt 1;
BA_ "U_CD42_MY14_Gas_Rx" SG_ 376 AirAmb_Te_ActlFilt 1;
BA_ "U_P552_MY15_Gas_Rx" SG_ 376 AirAmb_Te_ActlFilt 1;
BA_ "U_S550_MY15_Gas_Rx" SG_ 376 AirAmb_Te_ActlFilt 1;
BA_ "U_C489_MY14_Gas_Rx" SG_ 376 AirAmb_Te_ActlFilt 1;
BA_ "U_U502_MY15_Gas_Rx" SG_ 376 AirAmb_Te_ActlFilt 1;
BA_ "U_UP375_MY15_Gas_Rx" SG_ 376 AirAmb_Te_ActlFilt 1;
BA_ "U_UP375_MY15_Diesel_Rx" SG_ 376 AirAmb_Te_ActlFilt 1;
BA_ "U_CD43_MY16_Gas_Rx" SG_ 376 AirAmb_Te_ActlFilt 1;
BA_ "CrossOver_InfoCAN" SG_ 376 AirAmb_Te_Actl 1;
BA_ "GenSigStartValue" SG_ 376 AirAmb_Te_Actl 512;
BA_ "U_CD4_MY13_Diesel_Rx" SG_ 376 AirAmb_Te_Actl 1;
BA_ "U_CD4_MY13_Gas_Rx" SG_ 376 AirAmb_Te_Actl 1;
BA_ "U_CD4_MY13_Hev_Rx" SG_ 376 AirAmb_Te_Actl 1;
BA_ "U_CD4_MY13_Phev_Rx" SG_ 376 AirAmb_Te_Actl 1;
BA_ "U_CD42_MY14_Diesel_Rx" SG_ 376 AirAmb_Te_Actl 1;
BA_ "U_CD42_MY14_Gas_Rx" SG_ 376 AirAmb_Te_Actl 1;
BA_ "U_P552_MY15_Gas_Rx" SG_ 376 AirAmb_Te_Actl 1;
BA_ "U_S550_MY15_Gas_Rx" SG_ 376 AirAmb_Te_Actl 1;
BA_ "U_C489_MY14_Gas_Rx" SG_ 376 AirAmb_Te_Actl 1;
BA_ "U_U502_MY15_Gas_Rx" SG_ 376 AirAmb_Te_Actl 1;
BA_ "U_UP375_MY15_Gas_Rx" SG_ 376 AirAmb_Te_Actl 1;
BA_ "U_UP375_MY15_Diesel_Rx" SG_ 376 AirAmb_Te_Actl 1;
BA_ "U_CD43_MY16_Gas_Rx" SG_ 376 AirAmb_Te_Actl 1;
BA_ "CrossOver_InfoCAN" SG_ 376 AirAmb_P_Actl 1;
BA_ "U_CD4_MY13_Diesel_Rx" SG_ 951 TirePress_Info_MaxInd 1;
BA_ "U_CD4_MY13_Gas_Rx" SG_ 951 TirePress_Info_MaxInd 1;
BA_ "U_CD4_MY13_Hev_Rx" SG_ 951 TirePress_Info_MaxInd 1;
BA_ "U_CD4_MY13_Phev_Rx" SG_ 951 TirePress_Info_MaxInd 1;
BA_ "U_CD42_MY14_Diesel_Rx" SG_ 951 TirePress_Info_MaxInd 1;
BA_ "U_CD42_MY14_Gas_Rx" SG_ 951 TirePress_Info_MaxInd 1;
BA_ "U_P552_MY15_Gas_Rx" SG_ 951 TirePress_Info_MaxInd 1;
BA_ "U_S550_MY15_Gas_Rx" SG_ 951 TirePress_Info_MaxInd 1;
BA_ "U_C489_MY14_Gas_Rx" SG_ 951 TirePress_Info_MaxInd 1;
BA_ "U_U502_MY15_Gas_Rx" SG_ 951 TirePress_Info_MaxInd 1;
BA_ "U_UP375_MY15_Gas_Rx" SG_ 951 TirePress_Info_MaxInd 1;
BA_ "U_UP375_MY15_Diesel_Rx" SG_ 951 TirePress_Info_MaxInd 1;
BA_ "U_CD43_MY16_Gas_Rx" SG_ 951 TirePress_Info_MaxInd 1;
BA_ "U_CD4_MY13_Diesel_Rx" SG_ 951 TirePress_Info_Index 1;
BA_ "U_CD4_MY13_Gas_Rx" SG_ 951 TirePress_Info_Index 1;
BA_ "U_CD4_MY13_Hev_Rx" SG_ 951 TirePress_Info_Index 1;
BA_ "U_CD4_MY13_Phev_Rx" SG_ 951 TirePress_Info_Index 1;
BA_ "U_CD42_MY14_Diesel_Rx" SG_ 951 TirePress_Info_Index 1;
BA_ "U_CD42_MY14_Gas_Rx" SG_ 951 TirePress_Info_Index 1;
BA_ "U_P552_MY15_Gas_Rx" SG_ 951 TirePress_Info_Index 1;
BA_ "U_S550_MY15_Gas_Rx" SG_ 951 TirePress_Info_Index 1;
BA_ "U_C489_MY14_Gas_Rx" SG_ 951 TirePress_Info_Index 1;
BA_ "U_U502_MY15_Gas_Rx" SG_ 951 TirePress_Info_Index 1;
BA_ "U_UP375_MY15_Gas_Rx" SG_ 951 TirePress_Info_Index 1;
BA_ "U_UP375_MY15_Diesel_Rx" SG_ 951 TirePress_Info_Index 1;
BA_ "U_CD43_MY16_Gas_Rx" SG_ 951 TirePress_Info_Index 1;
BA_ "U_CD4_MY13_Diesel_Rx" SG_ 951 TirePress_Info_ID 1;
BA_ "U_CD4_MY13_Gas_Rx" SG_ 951 TirePress_Info_ID 1;
BA_ "U_CD4_MY13_Hev_Rx" SG_ 951 TirePress_Info_ID 1;
BA_ "U_CD4_MY13_Phev_Rx" SG_ 951 TirePress_Info_ID 1;
BA_ "U_CD42_MY14_Diesel_Rx" SG_ 951 TirePress_Info_ID 1;
BA_ "U_CD42_MY14_Gas_Rx" SG_ 951 TirePress_Info_ID 1;
BA_ "U_P552_MY15_Gas_Rx" SG_ 951 TirePress_Info_ID 1;
BA_ "U_S550_MY15_Gas_Rx" SG_ 951 TirePress_Info_ID 1;
BA_ "U_C489_MY14_Gas_Rx" SG_ 951 TirePress_Info_ID 1;
BA_ "U_U502_MY15_Gas_Rx" SG_ 951 TirePress_Info_ID 1;
BA_ "U_UP375_MY15_Gas_Rx" SG_ 951 TirePress_Info_ID 1;
BA_ "U_UP375_MY15_Diesel_Rx" SG_ 951 TirePress_Info_ID 1;
BA_ "U_CD43_MY16_Gas_Rx" SG_ 951 TirePress_Info_ID 1;
BA_ "CrossOver_InfoCAN" SG_ 1068 Batt_Lo_SoC_B_UB 1;
BA_ "U_CD4_MY13_Diesel_Rx" SG_ 1068 Batt_Lo_SoC_B_UB 1;
BA_ "U_CD4_MY13_Gas_Rx" SG_ 1068 Batt_Lo_SoC_B_UB 1;
BA_ "U_CD4_MY13_Hev_Rx" SG_ 1068 Batt_Lo_SoC_B_UB 1;
BA_ "U_CD4_MY13_Phev_Rx" SG_ 1068 Batt_Lo_SoC_B_UB 1;
BA_ "U_CD42_MY14_Diesel_Rx" SG_ 1068 Batt_Lo_SoC_B_UB 1;
BA_ "U_CD42_MY14_Gas_Rx" SG_ 1068 Batt_Lo_SoC_B_UB 1;
BA_ "U_P552_MY15_Gas_Rx" SG_ 1068 Batt_Lo_SoC_B_UB 1;
BA_ "U_S550_MY15_Gas_Rx" SG_ 1068 Batt_Lo_SoC_B_UB 1;
BA_ "U_C489_MY14_Gas_Rx" SG_ 1068 Batt_Lo_SoC_B_UB 1;
BA_ "U_U502_MY15_Gas_Rx" SG_ 1068 Batt_Lo_SoC_B_UB 1;
BA_ "U_UP375_MY15_Gas_Rx" SG_ 1068 Batt_Lo_SoC_B_UB 1;
BA_ "U_UP375_MY15_Diesel_Rx" SG_ 1068 Batt_Lo_SoC_B_UB 1;
BA_ "U_CD43_MY16_Gas_Rx" SG_ 1068 Batt_Lo_SoC_B_UB 1;
BA_ "CrossOver_InfoCAN" SG_ 1068 Batt_Lo_SoC_B 1;
BA_ "U_CD4_MY13_Diesel_Rx" SG_ 1068 Batt_Lo_SoC_B 1;
BA_ "U_CD4_MY13_Gas_Rx" SG_ 1068 Batt_Lo_SoC_B 1;
BA_ "U_CD4_MY13_Hev_Rx" SG_ 1068 Batt_Lo_SoC_B 1;
BA_ "U_CD4_MY13_Phev_Rx" SG_ 1068 Batt_Lo_SoC_B 1;
BA_ "U_CD42_MY14_Diesel_Rx" SG_ 1068 Batt_Lo_SoC_B 1;
BA_ "U_CD42_MY14_Gas_Rx" SG_ 1068 Batt_Lo_SoC_B 1;
BA_ "U_P552_MY15_Gas_Rx" SG_ 1068 Batt_Lo_SoC_B 1;
BA_ "U_S550_MY15_Gas_Rx" SG_ 1068 Batt_Lo_SoC_B 1;
BA_ "U_C489_MY14_Gas_Rx" SG_ 1068 Batt_Lo_SoC_B 1;
BA_ "U_U502_MY15_Gas_Rx" SG_ 1068 Batt_Lo_SoC_B 1;
BA_ "U_UP375_MY15_Gas_Rx" SG_ 1068 Batt_Lo_SoC_B 1;
BA_ "U_UP375_MY15_Diesel_Rx" SG_ 1068 Batt_Lo_SoC_B 1;
BA_ "U_CD43_MY16_Gas_Rx" SG_ 1068 Batt_Lo_SoC_B 1;
BA_ "CrossOver_InfoCAN" SG_ 1068 Batt_Crit_SoC_B_UB 1;
BA_ "U_CD4_MY13_Diesel_Rx" SG_ 1068 Batt_Crit_SoC_B_UB 1;
BA_ "U_CD4_MY13_Gas_Rx" SG_ 1068 Batt_Crit_SoC_B_UB 1;
BA_ "U_CD4_MY13_Hev_Rx" SG_ 1068 Batt_Crit_SoC_B_UB 1;
BA_ "U_CD4_MY13_Phev_Rx" SG_ 1068 Batt_Crit_SoC_B_UB 1;
BA_ "U_CD42_MY14_Diesel_Rx" SG_ 1068 Batt_Crit_SoC_B_UB 1;
BA_ "U_CD42_MY14_Gas_Rx" SG_ 1068 Batt_Crit_SoC_B_UB 1;
BA_ "U_P552_MY15_Gas_Rx" SG_ 1068 Batt_Crit_SoC_B_UB 1;
BA_ "U_S550_MY15_Gas_Rx" SG_ 1068 Batt_Crit_SoC_B_UB 1;
BA_ "U_C489_MY14_Gas_Rx" SG_ 1068 Batt_Crit_SoC_B_UB 1;
BA_ "U_U502_MY15_Gas_Rx" SG_ 1068 Batt_Crit_SoC_B_UB 1;
BA_ "U_UP375_MY15_Gas_Rx" SG_ 1068 Batt_Crit_SoC_B_UB 1;
BA_ "U_UP375_MY15_Diesel_Rx" SG_ 1068 Batt_Crit_SoC_B_UB 1;
BA_ "U_CD43_MY16_Gas_Rx" SG_ 1068 Batt_Crit_SoC_B_UB 1;
BA_ "CrossOver_InfoCAN" SG_ 1068 Batt_Crit_SoC_B 1;
BA_ "U_CD4_MY13_Diesel_Rx" SG_ 1068 Batt_Crit_SoC_B 1;
BA_ "U_CD4_MY13_Gas_Rx" SG_ 1068 Batt_Crit_SoC_B 1;
BA_ "U_CD4_MY13_Hev_Rx" SG_ 1068 Batt_Crit_SoC_B 1;
BA_ "U_CD4_MY13_Phev_Rx" SG_ 1068 Batt_Crit_SoC_B 1;
BA_ "U_CD42_MY14_Diesel_Rx" SG_ 1068 Batt_Crit_SoC_B 1;
BA_ "U_CD42_MY14_Gas_Rx" SG_ 1068 Batt_Crit_SoC_B 1;
BA_ "U_P552_MY15_Gas_Rx" SG_ 1068 Batt_Crit_SoC_B 1;
BA_ "U_S550_MY15_Gas_Rx" SG_ 1068 Batt_Crit_SoC_B 1;
BA_ "U_C489_MY14_Gas_Rx" SG_ 1068 Batt_Crit_SoC_B 1;
BA_ "U_U502_MY15_Gas_Rx" SG_ 1068 Batt_Crit_SoC_B 1;
BA_ "U_UP375_MY15_Gas_Rx" SG_ 1068 Batt_Crit_SoC_B 1;
BA_ "U_UP375_MY15_Diesel_Rx" SG_ 1068 Batt_Crit_SoC_B 1;
BA_ "U_CD43_MY16_Gas_Rx" SG_ 1068 Batt_Crit_SoC_B 1;
BA_ "CrossOver_InfoCAN" SG_ 1068 Shed_T_Eng_Off_B_UB 1;
BA_ "U_CD4_MY13_Diesel_Rx" SG_ 1068 Shed_T_Eng_Off_B_UB 1;
BA_ "U_CD4_MY13_Gas_Rx" SG_ 1068 Shed_T_Eng_Off_B_UB 1;
BA_ "U_CD4_MY13_Hev_Rx" SG_ 1068 Shed_T_Eng_Off_B_UB 1;
BA_ "U_CD4_MY13_Phev_Rx" SG_ 1068 Shed_T_Eng_Off_B_UB 1;
BA_ "U_CD42_MY14_Diesel_Rx" SG_ 1068 Shed_T_Eng_Off_B_UB 1;
BA_ "U_CD42_MY14_Gas_Rx" SG_ 1068 Shed_T_Eng_Off_B_UB 1;
BA_ "U_P552_MY15_Gas_Rx" SG_ 1068 Shed_T_Eng_Off_B_UB 1;
BA_ "U_S550_MY15_Gas_Rx" SG_ 1068 Shed_T_Eng_Off_B_UB 1;
BA_ "U_C489_MY14_Gas_Rx" SG_ 1068 Shed_T_Eng_Off_B_UB 1;
BA_ "U_U502_MY15_Gas_Rx" SG_ 1068 Shed_T_Eng_Off_B_UB 1;
BA_ "U_UP375_MY15_Gas_Rx" SG_ 1068 Shed_T_Eng_Off_B_UB 1;
BA_ "U_UP375_MY15_Diesel_Rx" SG_ 1068 Shed_T_Eng_Off_B_UB 1;
BA_ "U_CD43_MY16_Gas_Rx" SG_ 1068 Shed_T_Eng_Off_B_UB 1;
BA_ "CrossOver_InfoCAN" SG_ 1068 Shed_T_Eng_Off_B 1;
BA_ "U_CD4_MY13_Diesel_Rx" SG_ 1068 Shed_T_Eng_Off_B 1;
BA_ "U_CD4_MY13_Gas_Rx" SG_ 1068 Shed_T_Eng_Off_B 1;
BA_ "U_CD4_MY13_Hev_Rx" SG_ 1068 Shed_T_Eng_Off_B 1;
BA_ "U_CD4_MY13_Phev_Rx" SG_ 1068 Shed_T_Eng_Off_B 1;
BA_ "U_CD42_MY14_Diesel_Rx" SG_ 1068 Shed_T_Eng_Off_B 1;
BA_ "U_CD42_MY14_Gas_Rx" SG_ 1068 Shed_T_Eng_Off_B 1;
BA_ "U_P552_MY15_Gas_Rx" SG_ 1068 Shed_T_Eng_Off_B 1;
BA_ "U_S550_MY15_Gas_Rx" SG_ 1068 Shed_T_Eng_Off_B 1;
BA_ "U_C489_MY14_Gas_Rx" SG_ 1068 Shed_T_Eng_Off_B 1;
BA_ "U_U502_MY15_Gas_Rx" SG_ 1068 Shed_T_Eng_Off_B 1;
BA_ "U_UP375_MY15_Gas_Rx" SG_ 1068 Shed_T_Eng_Off_B 1;
BA_ "U_UP375_MY15_Diesel_Rx" SG_ 1068 Shed_T_Eng_Off_B 1;
BA_ "U_CD43_MY16_Gas_Rx" SG_ 1068 Shed_T_Eng_Off_B 1;
BA_ "CrossOver_InfoCAN" SG_ 1068 Shed_Level_Req_UB 1;
BA_ "U_CD4_MY13_Diesel_Rx" SG_ 1068 Shed_Level_Req_UB 1;
BA_ "U_CD4_MY13_Gas_Rx" SG_ 1068 Shed_Level_Req_UB 1;
BA_ "U_CD4_MY13_Hev_Rx" SG_ 1068 Shed_Level_Req_UB 1;
BA_ "U_CD4_MY13_Phev_Rx" SG_ 1068 Shed_Level_Req_UB 1;
BA_ "U_CD42_MY14_Diesel_Rx" SG_ 1068 Shed_Level_Req_UB 1;
BA_ "U_CD42_MY14_Gas_Rx" SG_ 1068 Shed_Level_Req_UB 1;
BA_ "U_P552_MY15_Gas_Rx" SG_ 1068 Shed_Level_Req_UB 1;
BA_ "U_S550_MY15_Gas_Rx" SG_ 1068 Shed_Level_Req_UB 1;
BA_ "U_C489_MY14_Gas_Rx" SG_ 1068 Shed_Level_Req_UB 1;
BA_ "U_U502_MY15_Gas_Rx" SG_ 1068 Shed_Level_Req_UB 1;
BA_ "U_UP375_MY15_Gas_Rx" SG_ 1068 Shed_Level_Req_UB 1;
BA_ "U_UP375_MY15_Diesel_Rx" SG_ 1068 Shed_Level_Req_UB 1;
BA_ "U_CD43_MY16_Gas_Rx" SG_ 1068 Shed_Level_Req_UB 1;
BA_ "U_CD4_MY14_Diesel_Rx" SG_ 1068 Shed_Level_Req_UB 1;
BA_ "U_CD4_MY14_Gas_Rx" SG_ 1068 Shed_Level_Req_UB 1;
BA_ "U_CD4_MY14_Hev_Rx" SG_ 1068 Shed_Level_Req_UB 1;
BA_ "U_CD4_MY14_Phev_Rx" SG_ 1068 Shed_Level_Req_UB 1;
BA_ "WakeupSignal" SG_ 1068 Shed_Level_Req 1;
BA_ "CrossOver_InfoCAN" SG_ 1068 Shed_Level_Req 1;
BA_ "U_CD4_MY13_Diesel_Rx" SG_ 1068 Shed_Level_Req 1;
BA_ "U_CD4_MY13_Gas_Rx" SG_ 1068 Shed_Level_Req 1;
BA_ "U_CD4_MY13_Hev_Rx" SG_ 1068 Shed_Level_Req 1;
BA_ "U_CD4_MY13_Phev_Rx" SG_ 1068 Shed_Level_Req 1;
BA_ "U_CD42_MY14_Diesel_Rx" SG_ 1068 Shed_Level_Req 1;
BA_ "U_CD42_MY14_Gas_Rx" SG_ 1068 Shed_Level_Req 1;
BA_ "U_P552_MY15_Gas_Rx" SG_ 1068 Shed_Level_Req 1;
BA_ "U_S550_MY15_Gas_Rx" SG_ 1068 Shed_Level_Req 1;
BA_ "U_C489_MY14_Gas_Rx" SG_ 1068 Shed_Level_Req 1;
BA_ "U_U502_MY15_Gas_Rx" SG_ 1068 Shed_Level_Req 1;
BA_ "U_UP375_MY15_Gas_Rx" SG_ 1068 Shed_Level_Req 1;
BA_ "U_UP375_MY15_Diesel_Rx" SG_ 1068 Shed_Level_Req 1;
BA_ "U_CD43_MY16_Gas_Rx" SG_ 1068 Shed_Level_Req 1;
BA_ "U_CD4_MY14_Diesel_Rx" SG_ 1068 Shed_Level_Req 1;
BA_ "U_CD4_MY14_Gas_Rx" SG_ 1068 Shed_Level_Req 1;
BA_ "U_CD4_MY14_Hev_Rx" SG_ 1068 Shed_Level_Req 1;
BA_ "U_CD4_MY14_Phev_Rx" SG_ 1068 Shed_Level_Req 1;
BA_ "U_CD4_MY13_Diesel_Rx" SG_ 1068 Shed_Feature_Group_ID_UB 1;
BA_ "U_CD4_MY13_Gas_Rx" SG_ 1068 Shed_Feature_Group_ID_UB 1;
BA_ "U_CD4_MY13_Hev_Rx" SG_ 1068 Shed_Feature_Group_ID_UB 1;
BA_ "U_CD4_MY13_Phev_Rx" SG_ 1068 Shed_Feature_Group_ID_UB 1;
BA_ "U_CD42_MY14_Diesel_Rx" SG_ 1068 Shed_Feature_Group_ID_UB 1;
BA_ "U_CD42_MY14_Gas_Rx" SG_ 1068 Shed_Feature_Group_ID_UB 1;
BA_ "U_P552_MY15_Gas_Rx" SG_ 1068 Shed_Feature_Group_ID_UB 1;
BA_ "U_S550_MY15_Gas_Rx" SG_ 1068 Shed_Feature_Group_ID_UB 1;
BA_ "U_C489_MY14_Gas_Rx" SG_ 1068 Shed_Feature_Group_ID_UB 1;
BA_ "U_U502_MY15_Gas_Rx" SG_ 1068 Shed_Feature_Group_ID_UB 1;
BA_ "U_UP375_MY15_Gas_Rx" SG_ 1068 Shed_Feature_Group_ID_UB 1;
BA_ "U_UP375_MY15_Diesel_Rx" SG_ 1068 Shed_Feature_Group_ID_UB 1;
BA_ "U_CD43_MY16_Gas_Rx" SG_ 1068 Shed_Feature_Group_ID_UB 1;
BA_ "WakeupSignal" SG_ 1068 Shed_Feature_Group_ID 1;
BA_ "U_CD4_MY13_Diesel_Rx" SG_ 1068 Shed_Feature_Group_ID 1;
BA_ "U_CD4_MY13_Gas_Rx" SG_ 1068 Shed_Feature_Group_ID 1;
BA_ "U_CD4_MY13_Hev_Rx" SG_ 1068 Shed_Feature_Group_ID 1;
BA_ "U_CD4_MY13_Phev_Rx" SG_ 1068 Shed_Feature_Group_ID 1;
BA_ "U_CD42_MY14_Diesel_Rx" SG_ 1068 Shed_Feature_Group_ID 1;
BA_ "U_CD42_MY14_Gas_Rx" SG_ 1068 Shed_Feature_Group_ID 1;
BA_ "U_P552_MY15_Gas_Rx" SG_ 1068 Shed_Feature_Group_ID 1;
BA_ "U_S550_MY15_Gas_Rx" SG_ 1068 Shed_Feature_Group_ID 1;
BA_ "U_C489_MY14_Gas_Rx" SG_ 1068 Shed_Feature_Group_ID 1;
BA_ "U_U502_MY15_Gas_Rx" SG_ 1068 Shed_Feature_Group_ID 1;
BA_ "U_UP375_MY15_Gas_Rx" SG_ 1068 Shed_Feature_Group_ID 1;
BA_ "U_UP375_MY15_Diesel_Rx" SG_ 1068 Shed_Feature_Group_ID 1;
BA_ "U_CD43_MY16_Gas_Rx" SG_ 1068 Shed_Feature_Group_ID 1;
BA_ "CrossOver_InfoCAN" SG_ 1068 Shed_Drain_Eng_Off_B_UB 1;
BA_ "U_CD4_MY13_Diesel_Rx" SG_ 1068 Shed_Drain_Eng_Off_B_UB 1;
BA_ "U_CD4_MY13_Gas_Rx" SG_ 1068 Shed_Drain_Eng_Off_B_UB 1;
BA_ "U_CD4_MY13_Hev_Rx" SG_ 1068 Shed_Drain_Eng_Off_B_UB 1;
BA_ "U_CD4_MY13_Phev_Rx" SG_ 1068 Shed_Drain_Eng_Off_B_UB 1;
BA_ "U_CD42_MY14_Diesel_Rx" SG_ 1068 Shed_Drain_Eng_Off_B_UB 1;
BA_ "U_CD42_MY14_Gas_Rx" SG_ 1068 Shed_Drain_Eng_Off_B_UB 1;
BA_ "U_P552_MY15_Gas_Rx" SG_ 1068 Shed_Drain_Eng_Off_B_UB 1;
BA_ "U_S550_MY15_Gas_Rx" SG_ 1068 Shed_Drain_Eng_Off_B_UB 1;
BA_ "U_C489_MY14_Gas_Rx" SG_ 1068 Shed_Drain_Eng_Off_B_UB 1;
BA_ "U_U502_MY15_Gas_Rx" SG_ 1068 Shed_Drain_Eng_Off_B_UB 1;
BA_ "U_UP375_MY15_Gas_Rx" SG_ 1068 Shed_Drain_Eng_Off_B_UB 1;
BA_ "U_UP375_MY15_Diesel_Rx" SG_ 1068 Shed_Drain_Eng_Off_B_UB 1;
BA_ "U_CD43_MY16_Gas_Rx" SG_ 1068 Shed_Drain_Eng_Off_B_UB 1;
BA_ "CrossOver_InfoCAN" SG_ 1068 Shed_Drain_Eng_Off_B 1;
BA_ "U_CD4_MY13_Diesel_Rx" SG_ 1068 Shed_Drain_Eng_Off_B 1;
BA_ "U_CD4_MY13_Gas_Rx" SG_ 1068 Shed_Drain_Eng_Off_B 1;
BA_ "U_CD4_MY13_Hev_Rx" SG_ 1068 Shed_Drain_Eng_Off_B 1;
BA_ "U_CD4_MY13_Phev_Rx" SG_ 1068 Shed_Drain_Eng_Off_B 1;
BA_ "U_CD42_MY14_Diesel_Rx" SG_ 1068 Shed_Drain_Eng_Off_B 1;
BA_ "U_CD42_MY14_Gas_Rx" SG_ 1068 Shed_Drain_Eng_Off_B 1;
BA_ "U_P552_MY15_Gas_Rx" SG_ 1068 Shed_Drain_Eng_Off_B 1;
BA_ "U_S550_MY15_Gas_Rx" SG_ 1068 Shed_Drain_Eng_Off_B 1;
BA_ "U_C489_MY14_Gas_Rx" SG_ 1068 Shed_Drain_Eng_Off_B 1;
BA_ "U_U502_MY15_Gas_Rx" SG_ 1068 Shed_Drain_Eng_Off_B 1;
BA_ "U_UP375_MY15_Gas_Rx" SG_ 1068 Shed_Drain_Eng_Off_B 1;
BA_ "U_UP375_MY15_Diesel_Rx" SG_ 1068 Shed_Drain_Eng_Off_B 1;
BA_ "U_CD43_MY16_Gas_Rx" SG_ 1068 Shed_Drain_Eng_Off_B 1;
BA_ "U_CD4_MY13_Diesel_Rx" SG_ 1068 AirCondRec_B_Rq_UB 1;
BA_ "U_CD4_MY13_Gas_Rx" SG_ 1068 AirCondRec_B_Rq_UB 1;
BA_ "U_CD4_MY13_Hev_Rx" SG_ 1068 AirCondRec_B_Rq_UB 1;
BA_ "U_CD4_MY13_Phev_Rx" SG_ 1068 AirCondRec_B_Rq_UB 1;
BA_ "U_CD42_MY14_Diesel_Rx" SG_ 1068 AirCondRec_B_Rq_UB 1;
BA_ "U_CD42_MY14_Gas_Rx" SG_ 1068 AirCondRec_B_Rq_UB 1;
BA_ "U_P552_MY15_Gas_Rx" SG_ 1068 AirCondRec_B_Rq_UB 1;
BA_ "U_S550_MY15_Gas_Rx" SG_ 1068 AirCondRec_B_Rq_UB 1;
BA_ "U_C489_MY14_Gas_Rx" SG_ 1068 AirCondRec_B_Rq_UB 1;
BA_ "U_U502_MY15_Gas_Rx" SG_ 1068 AirCondRec_B_Rq_UB 1;
BA_ "U_UP375_MY15_Gas_Rx" SG_ 1068 AirCondRec_B_Rq_UB 1;
BA_ "U_UP375_MY15_Diesel_Rx" SG_ 1068 AirCondRec_B_Rq_UB 1;
BA_ "U_CD43_MY16_Gas_Rx" SG_ 1068 AirCondRec_B_Rq_UB 1;
BA_ "U_CD4_MY13_Diesel_Rx" SG_ 1068 AirCondFluidHi_P_Actl_UB 1;
BA_ "U_CD4_MY13_Gas_Rx" SG_ 1068 AirCondFluidHi_P_Actl_UB 1;
BA_ "U_CD4_MY13_Hev_Rx" SG_ 1068 AirCondFluidHi_P_Actl_UB 1;
BA_ "U_CD4_MY13_Phev_Rx" SG_ 1068 AirCondFluidHi_P_Actl_UB 1;
BA_ "U_CD42_MY14_Diesel_Rx" SG_ 1068 AirCondFluidHi_P_Actl_UB 1;
BA_ "U_CD42_MY14_Gas_Rx" SG_ 1068 AirCondFluidHi_P_Actl_UB 1;
BA_ "U_P552_MY15_Gas_Rx" SG_ 1068 AirCondFluidHi_P_Actl_UB 1;
BA_ "U_S550_MY15_Gas_Rx" SG_ 1068 AirCondFluidHi_P_Actl_UB 1;
BA_ "U_C489_MY14_Gas_Rx" SG_ 1068 AirCondFluidHi_P_Actl_UB 1;
BA_ "U_U502_MY15_Gas_Rx" SG_ 1068 AirCondFluidHi_P_Actl_UB 1;
BA_ "U_UP375_MY15_Gas_Rx" SG_ 1068 AirCondFluidHi_P_Actl_UB 1;
BA_ "U_UP375_MY15_Diesel_Rx" SG_ 1068 AirCondFluidHi_P_Actl_UB 1;
BA_ "U_CD43_MY16_Gas_Rx" SG_ 1068 AirCondFluidHi_P_Actl_UB 1;
BA_ "U_CD4_MY13_Diesel_Rx" SG_ 1068 AirCondClutch_B_Stats_UB 1;
BA_ "U_CD4_MY13_Gas_Rx" SG_ 1068 AirCondClutch_B_Stats_UB 1;
BA_ "U_CD4_MY13_Hev_Rx" SG_ 1068 AirCondClutch_B_Stats_UB 1;
BA_ "U_CD4_MY13_Phev_Rx" SG_ 1068 AirCondClutch_B_Stats_UB 1;
BA_ "U_CD42_MY14_Diesel_Rx" SG_ 1068 AirCondClutch_B_Stats_UB 1;
BA_ "U_CD42_MY14_Gas_Rx" SG_ 1068 AirCondClutch_B_Stats_UB 1;
BA_ "U_P552_MY15_Gas_Rx" SG_ 1068 AirCondClutch_B_Stats_UB 1;
BA_ "U_S550_MY15_Gas_Rx" SG_ 1068 AirCondClutch_B_Stats_UB 1;
BA_ "U_C489_MY14_Gas_Rx" SG_ 1068 AirCondClutch_B_Stats_UB 1;
BA_ "U_U502_MY15_Gas_Rx" SG_ 1068 AirCondClutch_B_Stats_UB 1;
BA_ "U_UP375_MY15_Gas_Rx" SG_ 1068 AirCondClutch_B_Stats_UB 1;
BA_ "U_UP375_MY15_Diesel_Rx" SG_ 1068 AirCondClutch_B_Stats_UB 1;
BA_ "U_CD43_MY16_Gas_Rx" SG_ 1068 AirCondClutch_B_Stats_UB 1;
BA_ "CrossOver_InfoCAN" SG_ 1068 AirCondRec_B_Rq 1;
BA_ "ContentDependant" SG_ 1068 AirCondRec_B_Rq 1;
BA_ "U_CD4_MY13_Diesel_Rx" SG_ 1068 AirCondRec_B_Rq 1;
BA_ "U_CD4_MY13_Gas_Rx" SG_ 1068 AirCondRec_B_Rq 1;
BA_ "U_CD4_MY13_Hev_Rx" SG_ 1068 AirCondRec_B_Rq 1;
BA_ "U_CD4_MY13_Phev_Rx" SG_ 1068 AirCondRec_B_Rq 1;
BA_ "U_CD42_MY14_Diesel_Rx" SG_ 1068 AirCondRec_B_Rq 1;
BA_ "U_CD42_MY14_Gas_Rx" SG_ 1068 AirCondRec_B_Rq 1;
BA_ "U_P552_MY15_Gas_Rx" SG_ 1068 AirCondRec_B_Rq 1;
BA_ "U_S550_MY15_Gas_Rx" SG_ 1068 AirCondRec_B_Rq 1;
BA_ "U_C489_MY14_Gas_Rx" SG_ 1068 AirCondRec_B_Rq 1;
BA_ "U_U502_MY15_Gas_Rx" SG_ 1068 AirCondRec_B_Rq 1;
BA_ "U_UP375_MY15_Gas_Rx" SG_ 1068 AirCondRec_B_Rq 1;
BA_ "U_UP375_MY15_Diesel_Rx" SG_ 1068 AirCondRec_B_Rq 1;
BA_ "U_CD43_MY16_Gas_Rx" SG_ 1068 AirCondRec_B_Rq 1;
BA_ "CrossOver_InfoCAN" SG_ 1068 AirCondFluidHi_P_Actl 1;
BA_ "U_CD4_MY13_Diesel_Rx" SG_ 1068 AirCondFluidHi_P_Actl 1;
BA_ "U_CD4_MY13_Gas_Rx" SG_ 1068 AirCondFluidHi_P_Actl 1;
BA_ "U_CD4_MY13_Hev_Rx" SG_ 1068 AirCondFluidHi_P_Actl 1;
BA_ "U_CD4_MY13_Phev_Rx" SG_ 1068 AirCondFluidHi_P_Actl 1;
BA_ "U_CD42_MY14_Diesel_Rx" SG_ 1068 AirCondFluidHi_P_Actl 1;
BA_ "U_CD42_MY14_Gas_Rx" SG_ 1068 AirCondFluidHi_P_Actl 1;
BA_ "U_P552_MY15_Gas_Rx" SG_ 1068 AirCondFluidHi_P_Actl 1;
BA_ "U_S550_MY15_Gas_Rx" SG_ 1068 AirCondFluidHi_P_Actl 1;
BA_ "U_C489_MY14_Gas_Rx" SG_ 1068 AirCondFluidHi_P_Actl 1;
BA_ "U_U502_MY15_Gas_Rx" SG_ 1068 AirCondFluidHi_P_Actl 1;
BA_ "U_UP375_MY15_Gas_Rx" SG_ 1068 AirCondFluidHi_P_Actl 1;
BA_ "U_UP375_MY15_Diesel_Rx" SG_ 1068 AirCondFluidHi_P_Actl 1;
BA_ "U_CD43_MY16_Gas_Rx" SG_ 1068 AirCondFluidHi_P_Actl 1;
BA_ "CrossOver_InfoCAN" SG_ 1068 AirCondClutch_B_Stats 1;
BA_ "ContentDependant" SG_ 1068 AirCondClutch_B_Stats 1;
BA_ "U_CD4_MY13_Diesel_Rx" SG_ 1068 AirCondClutch_B_Stats 1;
BA_ "U_CD4_MY13_Gas_Rx" SG_ 1068 AirCondClutch_B_Stats 1;
BA_ "U_CD4_MY13_Hev_Rx" SG_ 1068 AirCondClutch_B_Stats 1;
BA_ "U_CD4_MY13_Phev_Rx" SG_ 1068 AirCondClutch_B_Stats 1;
BA_ "U_CD42_MY14_Diesel_Rx" SG_ 1068 AirCondClutch_B_Stats 1;
BA_ "U_CD42_MY14_Gas_Rx" SG_ 1068 AirCondClutch_B_Stats 1;
BA_ "U_P552_MY15_Gas_Rx" SG_ 1068 AirCondClutch_B_Stats 1;
BA_ "U_S550_MY15_Gas_Rx" SG_ 1068 AirCondClutch_B_Stats 1;
BA_ "U_C489_MY14_Gas_Rx" SG_ 1068 AirCondClutch_B_Stats 1;
BA_ "U_U502_MY15_Gas_Rx" SG_ 1068 AirCondClutch_B_Stats 1;
BA_ "U_UP375_MY15_Gas_Rx" SG_ 1068 AirCondClutch_B_Stats 1;
BA_ "U_UP375_MY15_Diesel_Rx" SG_ 1068 AirCondClutch_B_Stats 1;
BA_ "U_CD43_MY16_Gas_Rx" SG_ 1068 AirCondClutch_B_Stats 1;
BA_ "U_U55x_MY18_Gas_Rx" SG_ 963 PudLampPsngr_D_Rq 1;
BA_ "U_V408_MY18_Gas_Rx" SG_ 963 PudLampPsngr_D_Rq 1;
BA_ "U_V408_MY18_Diesel_Rx" SG_ 963 PudLampPsngr_D_Rq 1;
BA_ "U_V36X_MY18_5_Diesel_Rx" SG_ 963 PudLampPsngr_D_Rq 1;
BA_ "U_V36X_MY19_5_Diesel_Rx" SG_ 963 PudLampPsngr_D_Rq 1;
BA_ "U_V36X_MY18_5_Gas_Rx" SG_ 963 PudLampPsngr_D_Rq 1;
BA_ "U_V36X_MY18_5_Hev_Rx" SG_ 963 PudLampPsngr_D_Rq 1;
BA_ "U_U55x_MY18_Gas_Rx" SG_ 963 PudLampDrv_D_Rq 1;
BA_ "U_V408_MY18_Gas_Rx" SG_ 963 PudLampDrv_D_Rq 1;
BA_ "U_V36X_MY18_5_Diesel_Rx" SG_ 963 PudLampDrv_D_Rq 1;
BA_ "U_V36X_MY19_5_Diesel_Rx" SG_ 963 PudLampDrv_D_Rq 1;
BA_ "U_V36X_MY18_5_Gas_Rx" SG_ 963 PudLampDrv_D_Rq 1;
BA_ "U_V36X_MY18_5_Hev_Rx" SG_ 963 PudLampDrv_D_Rq 1;
BA_ "WakeupSignal" SG_ 963 ImpactEvntFdbck_D_Stat 1;
BA_ "CrossOver_InfoCAN" SG_ 963 ImpactEvntFdbck_D_Stat 1;
BA_ "CrossOver_InfoCAN" SG_ 963 HeadLampLoOut_B_Stat 1;
BA_ "CrossOver_InfoCAN" SG_ 963 CrnrLghtRight_Pc_Rq 1;
BA_ "CrossOver_InfoCAN" SG_ 963 CrnrLghtLeft_Pc_Rq 1;
BA_ "CrossOver_InfoCAN" SG_ 963 HeadLghtHiFdbck_D_Stat 1;
BA_ "CrossOver_InfoCAN" SG_ 963 PrkLightChime_B_Rq 1;
BA_ "CrossOver_InfoCAN" SG_ 963 TrnNotInPrkChime_B_Rq 1;
BA_ "WakeupSignal" SG_ 963 HomeSafeLtChime_B_Rq 1;
BA_ "CrossOver_InfoCAN" SG_ 963 HomeSafeLtChime_B_Rq 1;
BA_ "WakeupSignal" SG_ 963 StopLghtOn_B_Stat 1;
BA_ "CrossOver_InfoCAN" SG_ 963 StopLghtOn_B_Stat 1;
BA_ "CrossOver_LIN" SG_ 963 StopLghtOn_B_Stat 1;
BA_ "U_CD4_MY13_Diesel_Rx" SG_ 963 StopLghtOn_B_Stat 1;
BA_ "U_CD4_MY13_Gas_Rx" SG_ 963 StopLghtOn_B_Stat 1;
BA_ "U_CD4_MY13_Hev_Rx" SG_ 963 StopLghtOn_B_Stat 1;
BA_ "U_CD4_MY13_Phev_Rx" SG_ 963 StopLghtOn_B_Stat 1;
BA_ "U_CD42_MY14_Diesel_Rx" SG_ 963 StopLghtOn_B_Stat 1;
BA_ "U_CD42_MY14_Gas_Rx" SG_ 963 StopLghtOn_B_Stat 1;
BA_ "U_P552_MY15_Gas_Rx" SG_ 963 StopLghtOn_B_Stat 1;
BA_ "U_C489_MY14_Gas_Rx" SG_ 963 StopLghtOn_B_Stat 1;
BA_ "U_UP375_MY15_Gas_Rx" SG_ 963 StopLghtOn_B_Stat 1;
BA_ "U_UP375_MY15_Diesel_Rx" SG_ 963 StopLghtOn_B_Stat 1;
BA_ "U_S550_MY15_Gas_Rx" SG_ 963 StopLghtOn_B_Stat 1;
BA_ "U_U502_MY15_Gas_Rx" SG_ 963 StopLghtOn_B_Stat 1;
BA_ "U_CD43_MY16_Gas_Rx" SG_ 963 StopLghtOn_B_Stat 1;
BA_ "U_CD4_MY14_Diesel_Rx" SG_ 963 StopLghtOn_B_Stat 1;
BA_ "U_CD4_MY14_Gas_Rx" SG_ 963 StopLghtOn_B_Stat 1;
BA_ "U_CD4_MY14_Hev_Rx" SG_ 963 StopLghtOn_B_Stat 1;
BA_ "U_CD4_MY14_Phev_Rx" SG_ 963 StopLghtOn_B_Stat 1;
BA_ "CrossOver_InfoCAN" SG_ 963 RvrseLghtOn_B_Stat 1;
BA_ "CrossOver_LIN" SG_ 963 RvrseLghtOn_B_Stat 1;
BA_ "U_CD4_MY13_Diesel_Rx" SG_ 963 RvrseLghtOn_B_Stat 1;
BA_ "U_CD4_MY13_Gas_Rx" SG_ 963 RvrseLghtOn_B_Stat 1;
BA_ "U_CD4_MY13_Hev_Rx" SG_ 963 RvrseLghtOn_B_Stat 1;
BA_ "U_CD4_MY13_Phev_Rx" SG_ 963 RvrseLghtOn_B_Stat 1;
BA_ "U_CD42_MY14_Diesel_Rx" SG_ 963 RvrseLghtOn_B_Stat 1;
BA_ "U_CD42_MY14_Gas_Rx" SG_ 963 RvrseLghtOn_B_Stat 1;
BA_ "U_P552_MY15_Gas_Rx" SG_ 963 RvrseLghtOn_B_Stat 1;
BA_ "U_C489_MY14_Gas_Rx" SG_ 963 RvrseLghtOn_B_Stat 1;
BA_ "U_UP375_MY15_Gas_Rx" SG_ 963 RvrseLghtOn_B_Stat 1;
BA_ "U_UP375_MY15_Diesel_Rx" SG_ 963 RvrseLghtOn_B_Stat 1;
BA_ "WakeupSignal" SG_ 963 PrkLght_D_Stat 1;
BA_ "CrossOver_InfoCAN" SG_ 963 PrkLght_D_Stat 1;
BA_ "U_CD4_MY13_Diesel_Rx" SG_ 963 PrkLght_D_Stat 1;
BA_ "U_CD4_MY13_Gas_Rx" SG_ 963 PrkLght_D_Stat 1;
BA_ "U_CD4_MY13_Hev_Rx" SG_ 963 PrkLght_D_Stat 1;
BA_ "U_CD4_MY13_Phev_Rx" SG_ 963 PrkLght_D_Stat 1;
BA_ "U_CD42_MY14_Diesel_Rx" SG_ 963 PrkLght_D_Stat 1;
BA_ "U_CD42_MY14_Gas_Rx" SG_ 963 PrkLght_D_Stat 1;
BA_ "U_P552_MY15_Gas_Rx" SG_ 963 PrkLght_D_Stat 1;
BA_ "U_C489_MY14_Gas_Rx" SG_ 963 PrkLght_D_Stat 1;
BA_ "U_UP375_MY15_Gas_Rx" SG_ 963 PrkLght_D_Stat 1;
BA_ "U_UP375_MY15_Diesel_Rx" SG_ 963 PrkLght_D_Stat 1;
BA_ "WakeupSignal" SG_ 963 HeadLghtSwtch_D_Stat 1;
BA_ "CrossOver_InfoCAN" SG_ 963 HeadLghtSwtch_D_Stat 1;
BA_ "GenSigStartValue" SG_ 963 HeadLghtSwtch_D_Stat 2;
BA_ "WakeupSignal" SG_ 963 KeyInIgnWarn_B_Cmd 1;
BA_ "CrossOver_InfoCAN" SG_ 963 KeyInIgnWarn_B_Cmd 1;
BA_ "CrossOver_InfoCAN" SG_ 963 HeadLampLoFrOn_B_Stat 1;
BA_ "GenSigStartValue" SG_ 963 HeadLampLoFrOn_B_Stat 1;
BA_ "CrossOver_InfoCAN" SG_ 963 HeadLampLoFlOn_B_Stat 1;
BA_ "GenSigStartValue" SG_ 963 HeadLampLoFlOn_B_Stat 1;
BA_ "WakeupSignal" SG_ 963 Headlamp_On_Wrning_Cmd 1;
BA_ "CrossOver_InfoCAN" SG_ 963 Headlamp_On_Wrning_Cmd 1;
BA_ "CrossOver_InfoCAN" SG_ 963 HeadLampLoActv_B_Stat 1;
BA_ "GenSigStartValue" SG_ 963 HeadLampLoActv_B_Stat 1;
BA_ "WakeupSignal" SG_ 963 HeadLghtHiOn_B_Stat 1;
BA_ "CrossOver_InfoCAN" SG_ 963 HeadLghtHiOn_B_Stat 1;
BA_ "CrossOver_InfoCAN" SG_ 963 Park_Brake_Chime_Rqst 1;
BA_ "WakeupSignal" SG_ 963 BrkWarnInd_B_Rq 1;
BA_ "CrossOver_InfoCAN" SG_ 963 BrkWarnInd_B_Rq 1;
BA_ "CrossOver_InfoCAN" SG_ 963 Brk_Fluid_Lvl_Low 1;
BA_ "CrossOver_InfoCAN" SG_ 963 ReducedGuard_D_Stat 1;
BA_ "WakeupSignal" SG_ 963 Courtesy_BSave_Stat 1;
BA_ "CrossOver_InfoCAN" SG_ 963 Courtesy_BSave_Stat 1;
BA_ "GenSigStartValue" SG_ 963 Courtesy_BSave_Stat 1;
BA_ "U_CD4_MY13_Diesel_Rx" SG_ 963 Courtesy_BSave_Stat 1;
BA_ "U_CD4_MY13_Gas_Rx" SG_ 963 Courtesy_BSave_Stat 1;
BA_ "U_CD4_MY13_Hev_Rx" SG_ 963 Courtesy_BSave_Stat 1;
BA_ "U_CD4_MY13_Phev_Rx" SG_ 963 Courtesy_BSave_Stat 1;
BA_ "U_CD42_MY14_Diesel_Rx" SG_ 963 Courtesy_BSave_Stat 1;
BA_ "U_CD42_MY14_Gas_Rx" SG_ 963 Courtesy_BSave_Stat 1;
BA_ "U_P552_MY15_Gas_Rx" SG_ 963 Courtesy_BSave_Stat 1;
BA_ "U_S550_MY15_Gas_Rx" SG_ 963 Courtesy_BSave_Stat 1;
BA_ "U_C489_MY14_Gas_Rx" SG_ 963 Courtesy_BSave_Stat 1;
BA_ "U_U502_MY15_Gas_Rx" SG_ 963 Courtesy_BSave_Stat 1;
BA_ "U_UP375_MY15_Gas_Rx" SG_ 963 Courtesy_BSave_Stat 1;
BA_ "U_UP375_MY15_Diesel_Rx" SG_ 963 Courtesy_BSave_Stat 1;
BA_ "U_CD43_MY16_Gas_Rx" SG_ 963 Courtesy_BSave_Stat 1;
BA_ "U_CD4_MY14_Diesel_Rx" SG_ 963 Courtesy_BSave_Stat 1;
BA_ "U_CD4_MY14_Gas_Rx" SG_ 963 Courtesy_BSave_Stat 1;
BA_ "U_CD4_MY14_Hev_Rx" SG_ 963 Courtesy_BSave_Stat 1;
BA_ "U_CD4_MY14_Phev_Rx" SG_ 963 Courtesy_BSave_Stat 1;
BA_ "CrossOver_InfoCAN" SG_ 963 DayRnngLampOn_B_Stat 1;
BA_ "WakeupSignal" SG_ 963 PerimeterAlarmChimeRq 1;
BA_ "CrossOver_InfoCAN" SG_ 963 PerimeterAlarmChimeRq 1;
BA_ "WakeupSignal" SG_ 963 Perimeter_Alarm_Status 1;
BA_ "CrossOver_InfoCAN" SG_ 963 Perimeter_Alarm_Status 1;
BA_ "U_CD4_MY13_Diesel_Rx" SG_ 963 Perimeter_Alarm_Status 1;
BA_ "U_CD4_MY13_Gas_Rx" SG_ 963 Perimeter_Alarm_Status 1;
BA_ "U_CD42_MY14_Diesel_Rx" SG_ 963 Perimeter_Alarm_Status 1;
BA_ "U_CD42_MY14_Gas_Rx" SG_ 963 Perimeter_Alarm_Status 1;
BA_ "U_P552_MY15_Gas_Rx" SG_ 963 Perimeter_Alarm_Status 1;
BA_ "U_S550_MY15_Gas_Rx" SG_ 963 Perimeter_Alarm_Status 1;
BA_ "U_C489_MY14_Gas_Rx" SG_ 963 Perimeter_Alarm_Status 1;
BA_ "U_U502_MY15_Gas_Rx" SG_ 963 Perimeter_Alarm_Status 1;
BA_ "U_CD43_MY16_Gas_Rx" SG_ 963 Perimeter_Alarm_Status 1;
BA_ "U_CD4_MY14_Diesel_Rx" SG_ 963 Perimeter_Alarm_Status 1;
BA_ "U_CD4_MY14_Gas_Rx" SG_ 963 Perimeter_Alarm_Status 1;
BA_ "U_CD4_MY14_Hev_Rx" SG_ 963 Perimeter_Alarm_Status 1;
BA_ "U_CD4_MY14_Phev_Rx" SG_ 963 Perimeter_Alarm_Status 1;
BA_ "WakeupSignal" SG_ 963 WndwGlbl_D_Cmd 1;
BA_ "CrossOver_InfoCAN" SG_ 963 WndwGlbl_D_Cmd 1;
BA_ "U_CD4_MY13_Diesel_Rx" SG_ 963 WndwGlbl_D_Cmd 1;
BA_ "U_CD4_MY13_Gas_Rx" SG_ 963 WndwGlbl_D_Cmd 1;
BA_ "U_CD4_MY13_Hev_Rx" SG_ 963 WndwGlbl_D_Cmd 1;
BA_ "U_CD4_MY13_Phev_Rx" SG_ 963 WndwGlbl_D_Cmd 1;
BA_ "U_CD42_MY14_Diesel_Rx" SG_ 963 WndwGlbl_D_Cmd 1;
BA_ "U_CD42_MY14_Gas_Rx" SG_ 963 WndwGlbl_D_Cmd 1;
BA_ "U_P552_MY15_Gas_Rx" SG_ 963 WndwGlbl_D_Cmd 1;
BA_ "U_S550_MY15_Gas_Rx" SG_ 963 WndwGlbl_D_Cmd 1;
BA_ "U_C489_MY14_Gas_Rx" SG_ 963 WndwGlbl_D_Cmd 1;
BA_ "U_U502_MY15_Gas_Rx" SG_ 963 WndwGlbl_D_Cmd 1;
BA_ "U_UP375_MY15_Gas_Rx" SG_ 963 WndwGlbl_D_Cmd 1;
BA_ "U_UP375_MY15_Diesel_Rx" SG_ 963 WndwGlbl_D_Cmd 1;
BA_ "U_CD43_MY16_Gas_Rx" SG_ 963 WndwGlbl_D_Cmd 1;
BA_ "U_CD4_MY14_Diesel_Rx" SG_ 963 WndwGlbl_D_Cmd 1;
BA_ "U_CD4_MY14_Gas_Rx" SG_ 963 WndwGlbl_D_Cmd 1;
BA_ "U_CD4_MY14_Hev_Rx" SG_ 963 WndwGlbl_D_Cmd 1;
BA_ "U_CD4_MY14_Phev_Rx" SG_ 963 WndwGlbl_D_Cmd 1;
BA_ "WakeupSignal" SG_ 963 PudLamp_D_Rq 1;
BA_ "CrossOver_InfoCAN" SG_ 963 PudLamp_D_Rq 1;
BA_ "U_CD4_MY13_Diesel_Rx" SG_ 963 PudLamp_D_Rq 1;
BA_ "U_CD4_MY13_Gas_Rx" SG_ 963 PudLamp_D_Rq 1;
BA_ "U_CD4_MY13_Hev_Rx" SG_ 963 PudLamp_D_Rq 1;
BA_ "U_CD4_MY13_Phev_Rx" SG_ 963 PudLamp_D_Rq 1;
BA_ "U_CD42_MY14_Diesel_Rx" SG_ 963 PudLamp_D_Rq 1;
BA_ "U_CD42_MY14_Gas_Rx" SG_ 963 PudLamp_D_Rq 1;
BA_ "U_P552_MY15_Gas_Rx" SG_ 963 PudLamp_D_Rq 1;
BA_ "U_S550_MY15_Gas_Rx" SG_ 963 PudLamp_D_Rq 1;
BA_ "U_C489_MY14_Gas_Rx" SG_ 963 PudLamp_D_Rq 1;
BA_ "U_U502_MY15_Gas_Rx" SG_ 963 PudLamp_D_Rq 1;
BA_ "U_UP375_MY15_Gas_Rx" SG_ 963 PudLamp_D_Rq 1;
BA_ "U_UP375_MY15_Diesel_Rx" SG_ 963 PudLamp_D_Rq 1;
BA_ "U_CD43_MY16_Gas_Rx" SG_ 963 PudLamp_D_Rq 1;
BA_ "U_CD4_MY14_Diesel_Rx" SG_ 963 PudLamp_D_Rq 1;
BA_ "U_CD4_MY14_Gas_Rx" SG_ 963 PudLamp_D_Rq 1;
BA_ "U_CD4_MY14_Hev_Rx" SG_ 963 PudLamp_D_Rq 1;
BA_ "U_CD4_MY14_Phev_Rx" SG_ 963 PudLamp_D_Rq 1;
BA_ "U_CD4_MY13_Diesel_Rx" SG_ 964 Cta_D_Rq_UB 1;
BA_ "U_CD4_MY13_Gas_Rx" SG_ 964 Cta_D_Rq_UB 1;
BA_ "U_CD4_MY13_Hev_Rx" SG_ 964 Cta_D_Rq_UB 1;
BA_ "U_CD4_MY13_Phev_Rx" SG_ 964 Cta_D_Rq_UB 1;
BA_ "U_CD42_MY14_Diesel_Rx" SG_ 964 Cta_D_Rq_UB 1;
BA_ "U_CD42_MY14_Gas_Rx" SG_ 964 Cta_D_Rq_UB 1;
BA_ "U_P552_MY15_Gas_Rx" SG_ 964 Cta_D_Rq_UB 1;
BA_ "U_S550_MY15_Gas_Rx" SG_ 964 Cta_D_Rq_UB 1;
BA_ "U_C489_MY14_Gas_Rx" SG_ 964 Cta_D_Rq_UB 1;
BA_ "U_B562LC_MY14_Gas_Rx" SG_ 964 Cta_D_Rq_UB 1;
BA_ "U_U502_MY15_Gas_Rx" SG_ 964 Cta_D_Rq_UB 1;
BA_ "U_UP375_MY15_Gas_Rx" SG_ 964 Cta_D_Rq_UB 1;
BA_ "U_UP375_MY15_Diesel_Rx" SG_ 964 Cta_D_Rq_UB 1;
BA_ "U_CD43_MY16_Gas_Rx" SG_ 964 Cta_D_Rq_UB 1;
BA_ "CrossOver_InfoCAN" SG_ 964 Cta_D_Rq 1;
BA_ "GenSigStartValue" SG_ 964 Cta_D_Rq 1;
BA_ "GenSigSendType" SG_ 964 Cta_D_Rq 3;
BA_ "U_CD4_MY13_Diesel_Rx" SG_ 964 Cta_D_Rq 1;
BA_ "U_CD4_MY13_Gas_Rx" SG_ 964 Cta_D_Rq 1;
BA_ "U_CD4_MY13_Hev_Rx" SG_ 964 Cta_D_Rq 1;
BA_ "U_CD4_MY13_Phev_Rx" SG_ 964 Cta_D_Rq 1;
BA_ "U_CD42_MY14_Diesel_Rx" SG_ 964 Cta_D_Rq 1;
BA_ "U_CD42_MY14_Gas_Rx" SG_ 964 Cta_D_Rq 1;
BA_ "U_P552_MY15_Gas_Rx" SG_ 964 Cta_D_Rq 1;
BA_ "U_S550_MY15_Gas_Rx" SG_ 964 Cta_D_Rq 1;
BA_ "U_C489_MY14_Gas_Rx" SG_ 964 Cta_D_Rq 1;
BA_ "U_B562LC_MY14_Gas_Rx" SG_ 964 Cta_D_Rq 1;
BA_ "U_U502_MY15_Gas_Rx" SG_ 964 Cta_D_Rq 1;
BA_ "U_UP375_MY15_Gas_Rx" SG_ 964 Cta_D_Rq 1;
BA_ "U_UP375_MY15_Diesel_Rx" SG_ 964 Cta_D_Rq 1;
BA_ "U_CD43_MY16_Gas_Rx" SG_ 964 Cta_D_Rq 1;
BA_ "CrossOver_InfoCAN" SG_ 964 GearRvrse_D_Actl_UB 1;
BA_ "U_CD4_MY13_Diesel_Rx" SG_ 964 GearRvrse_D_Actl_UB 1;
BA_ "U_CD4_MY13_Gas_Rx" SG_ 964 GearRvrse_D_Actl_UB 1;
BA_ "U_CD4_MY13_Hev_Rx" SG_ 964 GearRvrse_D_Actl_UB 1;
BA_ "U_CD4_MY13_Phev_Rx" SG_ 964 GearRvrse_D_Actl_UB 1;
BA_ "U_CD42_MY14_Diesel_Rx" SG_ 964 GearRvrse_D_Actl_UB 1;
BA_ "U_CD42_MY14_Gas_Rx" SG_ 964 GearRvrse_D_Actl_UB 1;
BA_ "U_P552_MY15_Gas_Rx" SG_ 964 GearRvrse_D_Actl_UB 1;
BA_ "U_S550_MY15_Gas_Rx" SG_ 964 GearRvrse_D_Actl_UB 1;
BA_ "U_C489_MY14_Gas_Rx" SG_ 964 GearRvrse_D_Actl_UB 1;
BA_ "U_B562LC_MY14_Gas_Rx" SG_ 964 GearRvrse_D_Actl_UB 1;
BA_ "U_U502_MY15_Gas_Rx" SG_ 964 GearRvrse_D_Actl_UB 1;
BA_ "U_UP375_MY15_Gas_Rx" SG_ 964 GearRvrse_D_Actl_UB 1;
BA_ "U_UP375_MY15_Diesel_Rx" SG_ 964 GearRvrse_D_Actl_UB 1;
BA_ "U_CD43_MY16_Gas_Rx" SG_ 964 GearRvrse_D_Actl_UB 1;
BA_ "GenSigMissingSourceValue" SG_ 964 GearRvrse_D_Actl 3;
BA_ "CrossOver_InfoCAN" SG_ 964 GearRvrse_D_Actl 1;
BA_ "GenSigStartValue" SG_ 964 GearRvrse_D_Actl 7;
BA_ "GenSigSendType" SG_ 964 GearRvrse_D_Actl 3;
BA_ "U_CD4_MY13_Diesel_Rx" SG_ 964 GearRvrse_D_Actl 1;
BA_ "U_CD4_MY13_Gas_Rx" SG_ 964 GearRvrse_D_Actl 1;
BA_ "U_CD4_MY13_Hev_Rx" SG_ 964 GearRvrse_D_Actl 1;
BA_ "U_CD4_MY13_Phev_Rx" SG_ 964 GearRvrse_D_Actl 1;
BA_ "U_CD42_MY14_Diesel_Rx" SG_ 964 GearRvrse_D_Actl 1;
BA_ "U_CD42_MY14_Gas_Rx" SG_ 964 GearRvrse_D_Actl 1;
BA_ "U_P552_MY15_Gas_Rx" SG_ 964 GearRvrse_D_Actl 1;
BA_ "U_S550_MY15_Gas_Rx" SG_ 964 GearRvrse_D_Actl 1;
BA_ "U_C489_MY14_Gas_Rx" SG_ 964 GearRvrse_D_Actl 1;
BA_ "U_B562LC_MY14_Gas_Rx" SG_ 964 GearRvrse_D_Actl 1;
BA_ "U_U502_MY15_Gas_Rx" SG_ 964 GearRvrse_D_Actl 1;
BA_ "U_UP375_MY15_Gas_Rx" SG_ 964 GearRvrse_D_Actl 1;
BA_ "U_UP375_MY15_Diesel_Rx" SG_ 964 GearRvrse_D_Actl 1;
BA_ "U_CD43_MY16_Gas_Rx" SG_ 964 GearRvrse_D_Actl 1;
BA_ "CrossOver_InfoCAN" SG_ 964 TurnLghtSwtch_D_Stat_UB 1;
BA_ "U_CD4_MY13_Diesel_Rx" SG_ 964 TurnLghtSwtch_D_Stat_UB 1;
BA_ "U_CD4_MY13_Gas_Rx" SG_ 964 TurnLghtSwtch_D_Stat_UB 1;
BA_ "U_CD4_MY13_Hev_Rx" SG_ 964 TurnLghtSwtch_D_Stat_UB 1;
BA_ "U_CD4_MY13_Phev_Rx" SG_ 964 TurnLghtSwtch_D_Stat_UB 1;
BA_ "U_CD42_MY14_Diesel_Rx" SG_ 964 TurnLghtSwtch_D_Stat_UB 1;
BA_ "U_CD42_MY14_Gas_Rx" SG_ 964 TurnLghtSwtch_D_Stat_UB 1;
BA_ "U_P552_MY15_Gas_Rx" SG_ 964 TurnLghtSwtch_D_Stat_UB 1;
BA_ "U_S550_MY15_Gas_Rx" SG_ 964 TurnLghtSwtch_D_Stat_UB 1;
BA_ "U_C489_MY14_Gas_Rx" SG_ 964 TurnLghtSwtch_D_Stat_UB 1;
BA_ "U_B562LC_MY14_Gas_Rx" SG_ 964 TurnLghtSwtch_D_Stat_UB 1;
BA_ "U_U502_MY15_Gas_Rx" SG_ 964 TurnLghtSwtch_D_Stat_UB 1;
BA_ "U_UP375_MY15_Gas_Rx" SG_ 964 TurnLghtSwtch_D_Stat_UB 1;
BA_ "U_UP375_MY15_Diesel_Rx" SG_ 964 TurnLghtSwtch_D_Stat_UB 1;
BA_ "U_CD43_MY16_Gas_Rx" SG_ 964 TurnLghtSwtch_D_Stat_UB 1;
BA_ "WakeupSignal" SG_ 964 TurnLghtSwtch_D_Stat 1;
BA_ "CrossOver_InfoCAN" SG_ 964 TurnLghtSwtch_D_Stat 1;
BA_ "GenSigSendType" SG_ 964 TurnLghtSwtch_D_Stat 3;
BA_ "U_CD4_MY13_Diesel_Rx" SG_ 964 TurnLghtSwtch_D_Stat 1;
BA_ "U_CD4_MY13_Gas_Rx" SG_ 964 TurnLghtSwtch_D_Stat 1;
BA_ "U_CD4_MY13_Hev_Rx" SG_ 964 TurnLghtSwtch_D_Stat 1;
BA_ "U_CD4_MY13_Phev_Rx" SG_ 964 TurnLghtSwtch_D_Stat 1;
BA_ "U_CD42_MY14_Diesel_Rx" SG_ 964 TurnLghtSwtch_D_Stat 1;
BA_ "U_CD42_MY14_Gas_Rx" SG_ 964 TurnLghtSwtch_D_Stat 1;
BA_ "U_P552_MY15_Gas_Rx" SG_ 964 TurnLghtSwtch_D_Stat 1;
BA_ "U_S550_MY15_Gas_Rx" SG_ 964 TurnLghtSwtch_D_Stat 1;
BA_ "U_C489_MY14_Gas_Rx" SG_ 964 TurnLghtSwtch_D_Stat 1;
BA_ "U_B562LC_MY14_Gas_Rx" SG_ 964 TurnLghtSwtch_D_Stat 1;
BA_ "U_U502_MY15_Gas_Rx" SG_ 964 TurnLghtSwtch_D_Stat 1;
BA_ "U_UP375_MY15_Gas_Rx" SG_ 964 TurnLghtSwtch_D_Stat 1;
BA_ "U_UP375_MY15_Diesel_Rx" SG_ 964 TurnLghtSwtch_D_Stat 1;
BA_ "U_CD43_MY16_Gas_Rx" SG_ 964 TurnLghtSwtch_D_Stat 1;
BA_ "WakeupSignal" SG_ 964 Power_Liftgate_Mode_Cmd 1;
BA_ "CrossOver_InfoCAN" SG_ 964 Power_Liftgate_Mode_Cmd 1;
BA_ "GenSigSendType" SG_ 964 Power_Liftgate_Mode_Cmd 3;
BA_ "U_CD4_MY13_Diesel_Rx" SG_ 964 MetricActvTe_B_Actl_UB 1;
BA_ "U_CD4_MY13_Gas_Rx" SG_ 964 MetricActvTe_B_Actl_UB 1;
BA_ "U_CD4_MY13_Hev_Rx" SG_ 964 MetricActvTe_B_Actl_UB 1;
BA_ "U_CD4_MY13_Phev_Rx" SG_ 964 MetricActvTe_B_Actl_UB 1;
BA_ "U_CD42_MY14_Diesel_Rx" SG_ 964 MetricActvTe_B_Actl_UB 1;
BA_ "U_CD42_MY14_Gas_Rx" SG_ 964 MetricActvTe_B_Actl_UB 1;
BA_ "U_P552_MY15_Gas_Rx" SG_ 964 MetricActvTe_B_Actl_UB 1;
BA_ "U_S550_MY15_Gas_Rx" SG_ 964 MetricActvTe_B_Actl_UB 1;
BA_ "U_C489_MY14_Gas_Rx" SG_ 964 MetricActvTe_B_Actl_UB 1;
BA_ "U_U502_MY15_Gas_Rx" SG_ 964 MetricActvTe_B_Actl_UB 1;
BA_ "U_UP375_MY15_Gas_Rx" SG_ 964 MetricActvTe_B_Actl_UB 1;
BA_ "U_UP375_MY15_Diesel_Rx" SG_ 964 MetricActvTe_B_Actl_UB 1;
BA_ "U_CD43_MY16_Gas_Rx" SG_ 964 MetricActvTe_B_Actl_UB 1;
BA_ "CrossOver_InfoCAN" SG_ 964 MetricActvTe_B_Actl 1;
BA_ "GenSigSendType" SG_ 964 MetricActvTe_B_Actl 3;
BA_ "U_CD4_MY13_Diesel_Rx" SG_ 964 MetricActvTe_B_Actl 1;
BA_ "U_CD4_MY13_Gas_Rx" SG_ 964 MetricActvTe_B_Actl 1;
BA_ "U_CD4_MY13_Hev_Rx" SG_ 964 MetricActvTe_B_Actl 1;
BA_ "U_CD4_MY13_Phev_Rx" SG_ 964 MetricActvTe_B_Actl 1;
BA_ "U_CD42_MY14_Diesel_Rx" SG_ 964 MetricActvTe_B_Actl 1;
BA_ "U_CD42_MY14_Gas_Rx" SG_ 964 MetricActvTe_B_Actl 1;
BA_ "U_P552_MY15_Gas_Rx" SG_ 964 MetricActvTe_B_Actl 1;
BA_ "U_S550_MY15_Gas_Rx" SG_ 964 MetricActvTe_B_Actl 1;
BA_ "U_C489_MY14_Gas_Rx" SG_ 964 MetricActvTe_B_Actl 1;
BA_ "U_U502_MY15_Gas_Rx" SG_ 964 MetricActvTe_B_Actl 1;
BA_ "U_UP375_MY15_Gas_Rx" SG_ 964 MetricActvTe_B_Actl 1;
BA_ "U_UP375_MY15_Diesel_Rx" SG_ 964 MetricActvTe_B_Actl 1;
BA_ "U_CD43_MY16_Gas_Rx" SG_ 964 MetricActvTe_B_Actl 1;
BA_ "CrossOver_InfoCAN" SG_ 964 EngClntTe_D_Qf 1;
BA_ "GenSigSendType" SG_ 964 EngClntTe_D_Qf 3;
BA_ "U_CD4_MY13_Diesel_Rx" SG_ 964 EngClntTe_D_Qf 1;
BA_ "U_CD4_MY13_Gas_Rx" SG_ 964 EngClntTe_D_Qf 1;
BA_ "U_CD4_MY13_Hev_Rx" SG_ 964 EngClntTe_D_Qf 1;
BA_ "U_CD4_MY13_Phev_Rx" SG_ 964 EngClntTe_D_Qf 1;
BA_ "U_CD42_MY14_Diesel_Rx" SG_ 964 EngClntTe_D_Qf 1;
BA_ "U_CD42_MY14_Gas_Rx" SG_ 964 EngClntTe_D_Qf 1;
BA_ "U_P552_MY15_Gas_Rx" SG_ 964 EngClntTe_D_Qf 1;
BA_ "U_S550_MY15_Gas_Rx" SG_ 964 EngClntTe_D_Qf 1;
BA_ "U_C489_MY14_Gas_Rx" SG_ 964 EngClntTe_D_Qf 1;
BA_ "U_U502_MY15_Gas_Rx" SG_ 964 EngClntTe_D_Qf 1;
BA_ "U_UP375_MY15_Gas_Rx" SG_ 964 EngClntTe_D_Qf 1;
BA_ "U_UP375_MY15_Diesel_Rx" SG_ 964 EngClntTe_D_Qf 1;
BA_ "U_CD43_MY16_Gas_Rx" SG_ 964 EngClntTe_D_Qf 1;
BA_ "CrossOver_InfoCAN" SG_ 964 Sod_D_Rq 1;
BA_ "GenSigStartValue" SG_ 964 Sod_D_Rq 2;
BA_ "GenSigSendType" SG_ 964 Sod_D_Rq 3;
BA_ "U_CD4_MY13_Diesel_Rx" SG_ 964 Sod_D_Rq 1;
BA_ "U_CD4_MY13_Gas_Rx" SG_ 964 Sod_D_Rq 1;
BA_ "U_CD4_MY13_Hev_Rx" SG_ 964 Sod_D_Rq 1;
BA_ "U_CD4_MY13_Phev_Rx" SG_ 964 Sod_D_Rq 1;
BA_ "U_CD42_MY14_Diesel_Rx" SG_ 964 Sod_D_Rq 1;
BA_ "U_CD42_MY14_Gas_Rx" SG_ 964 Sod_D_Rq 1;
BA_ "U_P552_MY15_Gas_Rx" SG_ 964 Sod_D_Rq 1;
BA_ "U_S550_MY15_Gas_Rx" SG_ 964 Sod_D_Rq 1;
BA_ "U_C489_MY14_Gas_Rx" SG_ 964 Sod_D_Rq 1;
BA_ "U_B562LC_MY14_Gas_Rx" SG_ 964 Sod_D_Rq 1;
BA_ "U_U502_MY15_Gas_Rx" SG_ 964 Sod_D_Rq 1;
BA_ "U_UP375_MY15_Gas_Rx" SG_ 964 Sod_D_Rq 1;
BA_ "U_UP375_MY15_Diesel_Rx" SG_ 964 Sod_D_Rq 1;
BA_ "U_CD43_MY16_Gas_Rx" SG_ 964 Sod_D_Rq 1;
BA_ "CrossOver_InfoCAN" SG_ 964 MetricActv_B_Actl 1;
BA_ "GenSigSendType" SG_ 964 MetricActv_B_Actl 3;
BA_ "U_CD4_MY13_Diesel_Rx" SG_ 964 MetricActv_B_Actl 1;
BA_ "U_CD4_MY13_Gas_Rx" SG_ 964 MetricActv_B_Actl 1;
BA_ "U_CD4_MY13_Hev_Rx" SG_ 964 MetricActv_B_Actl 1;
BA_ "U_CD4_MY13_Phev_Rx" SG_ 964 MetricActv_B_Actl 1;
BA_ "U_CD42_MY14_Diesel_Rx" SG_ 964 MetricActv_B_Actl 1;
BA_ "U_CD42_MY14_Gas_Rx" SG_ 964 MetricActv_B_Actl 1;
BA_ "U_P552_MY15_Gas_Rx" SG_ 964 MetricActv_B_Actl 1;
BA_ "U_S550_MY15_Gas_Rx" SG_ 964 MetricActv_B_Actl 1;
BA_ "U_C489_MY14_Gas_Rx" SG_ 964 MetricActv_B_Actl 1;
BA_ "U_U502_MY15_Gas_Rx" SG_ 964 MetricActv_B_Actl 1;
BA_ "U_UP375_MY15_Gas_Rx" SG_ 964 MetricActv_B_Actl 1;
BA_ "U_UP375_MY15_Diesel_Rx" SG_ 964 MetricActv_B_Actl 1;
BA_ "U_CD43_MY16_Gas_Rx" SG_ 964 MetricActv_B_Actl 1;
BA_ "CrossOver_InfoCAN" SG_ 964 EngClnt_Te_Actl 1;
BA_ "GenSigSendType" SG_ 964 EngClnt_Te_Actl 3;
BA_ "U_CD4_MY13_Diesel_Rx" SG_ 964 EngClnt_Te_Actl 1;
BA_ "U_CD4_MY13_Gas_Rx" SG_ 964 EngClnt_Te_Actl 1;
BA_ "U_CD4_MY13_Hev_Rx" SG_ 964 EngClnt_Te_Actl 1;
BA_ "U_CD4_MY13_Phev_Rx" SG_ 964 EngClnt_Te_Actl 1;
BA_ "U_CD42_MY14_Diesel_Rx" SG_ 964 EngClnt_Te_Actl 1;
BA_ "U_CD42_MY14_Gas_Rx" SG_ 964 EngClnt_Te_Actl 1;
BA_ "U_P552_MY15_Gas_Rx" SG_ 964 EngClnt_Te_Actl 1;
BA_ "U_S550_MY15_Gas_Rx" SG_ 964 EngClnt_Te_Actl 1;
BA_ "U_C489_MY14_Gas_Rx" SG_ 964 EngClnt_Te_Actl 1;
BA_ "U_U502_MY15_Gas_Rx" SG_ 964 EngClnt_Te_Actl 1;
BA_ "U_UP375_MY15_Gas_Rx" SG_ 964 EngClnt_Te_Actl 1;
BA_ "U_UP375_MY15_Diesel_Rx" SG_ 964 EngClnt_Te_Actl 1;
BA_ "U_CD43_MY16_Gas_Rx" SG_ 964 EngClnt_Te_Actl 1;
BA_ "U_CD4_MY13_Diesel_Rx" SG_ 964 MetricActv_B_Actl_UB 1;
BA_ "U_CD4_MY13_Gas_Rx" SG_ 964 MetricActv_B_Actl_UB 1;
BA_ "U_CD4_MY13_Hev_Rx" SG_ 964 MetricActv_B_Actl_UB 1;
BA_ "U_CD4_MY13_Phev_Rx" SG_ 964 MetricActv_B_Actl_UB 1;
BA_ "U_CD42_MY14_Diesel_Rx" SG_ 964 MetricActv_B_Actl_UB 1;
BA_ "U_CD42_MY14_Gas_Rx" SG_ 964 MetricActv_B_Actl_UB 1;
BA_ "U_P552_MY15_Gas_Rx" SG_ 964 MetricActv_B_Actl_UB 1;
BA_ "U_S550_MY15_Gas_Rx" SG_ 964 MetricActv_B_Actl_UB 1;
BA_ "U_C489_MY14_Gas_Rx" SG_ 964 MetricActv_B_Actl_UB 1;
BA_ "U_U502_MY15_Gas_Rx" SG_ 964 MetricActv_B_Actl_UB 1;
BA_ "U_UP375_MY15_Gas_Rx" SG_ 964 MetricActv_B_Actl_UB 1;
BA_ "U_UP375_MY15_Diesel_Rx" SG_ 964 MetricActv_B_Actl_UB 1;
BA_ "U_CD43_MY16_Gas_Rx" SG_ 964 MetricActv_B_Actl_UB 1;
BA_ "U_CD4_MY13_Diesel_Rx" SG_ 964 EngClnt_Te_Actl_UB 1;
BA_ "U_CD4_MY13_Gas_Rx" SG_ 964 EngClnt_Te_Actl_UB 1;
BA_ "U_CD4_MY13_Hev_Rx" SG_ 964 EngClnt_Te_Actl_UB 1;
BA_ "U_CD4_MY13_Phev_Rx" SG_ 964 EngClnt_Te_Actl_UB 1;
BA_ "U_CD42_MY14_Diesel_Rx" SG_ 964 EngClnt_Te_Actl_UB 1;
BA_ "U_CD42_MY14_Gas_Rx" SG_ 964 EngClnt_Te_Actl_UB 1;
BA_ "U_P552_MY15_Gas_Rx" SG_ 964 EngClnt_Te_Actl_UB 1;
BA_ "U_S550_MY15_Gas_Rx" SG_ 964 EngClnt_Te_Actl_UB 1;
BA_ "U_C489_MY14_Gas_Rx" SG_ 964 EngClnt_Te_Actl_UB 1;
BA_ "U_U502_MY15_Gas_Rx" SG_ 964 EngClnt_Te_Actl_UB 1;
BA_ "U_UP375_MY15_Gas_Rx" SG_ 964 EngClnt_Te_Actl_UB 1;
BA_ "U_UP375_MY15_Diesel_Rx" SG_ 964 EngClnt_Te_Actl_UB 1;
BA_ "U_CD43_MY16_Gas_Rx" SG_ 964 EngClnt_Te_Actl_UB 1;
BA_ "U_CD4_MY13_Diesel_Rx" SG_ 964 OCSSensrDataUpperLim_UB 1;
BA_ "U_CD4_MY13_Gas_Rx" SG_ 964 OCSSensrDataUpperLim_UB 1;
BA_ "U_CD4_MY13_Hev_Rx" SG_ 964 OCSSensrDataUpperLim_UB 1;
BA_ "U_CD4_MY13_Phev_Rx" SG_ 964 OCSSensrDataUpperLim_UB 1;
BA_ "U_CD42_MY14_Diesel_Rx" SG_ 964 OCSSensrDataUpperLim_UB 1;
BA_ "U_CD42_MY14_Gas_Rx" SG_ 964 OCSSensrDataUpperLim_UB 1;
BA_ "U_P552_MY15_Gas_Rx" SG_ 964 OCSSensrDataUpperLim_UB 1;
BA_ "U_S550_MY15_Gas_Rx" SG_ 964 OCSSensrDataUpperLim_UB 1;
BA_ "U_C489_MY14_Gas_Rx" SG_ 964 OCSSensrDataUpperLim_UB 1;
BA_ "U_U502_MY15_Gas_Rx" SG_ 964 OCSSensrDataUpperLim_UB 1;
BA_ "U_UP375_MY15_Gas_Rx" SG_ 964 OCSSensrDataUpperLim_UB 1;
BA_ "U_UP375_MY15_Diesel_Rx" SG_ 964 OCSSensrDataUpperLim_UB 1;
BA_ "U_CD43_MY16_Gas_Rx" SG_ 964 OCSSensrDataUpperLim_UB 1;
BA_ "GenSigSendType" SG_ 964 OCSSensrDataUpperLim 3;
BA_ "U_CD4_MY13_Diesel_Rx" SG_ 964 OCSSensrDataUpperLim 1;
BA_ "U_CD4_MY13_Gas_Rx" SG_ 964 OCSSensrDataUpperLim 1;
BA_ "U_CD4_MY13_Hev_Rx" SG_ 964 OCSSensrDataUpperLim 1;
BA_ "U_CD4_MY13_Phev_Rx" SG_ 964 OCSSensrDataUpperLim 1;
BA_ "U_CD42_MY14_Diesel_Rx" SG_ 964 OCSSensrDataUpperLim 1;
BA_ "U_CD42_MY14_Gas_Rx" SG_ 964 OCSSensrDataUpperLim 1;
BA_ "U_P552_MY15_Gas_Rx" SG_ 964 OCSSensrDataUpperLim 1;
BA_ "U_S550_MY15_Gas_Rx" SG_ 964 OCSSensrDataUpperLim 1;
BA_ "U_C489_MY14_Gas_Rx" SG_ 964 OCSSensrDataUpperLim 1;
BA_ "U_U502_MY15_Gas_Rx" SG_ 964 OCSSensrDataUpperLim 1;
BA_ "U_UP375_MY15_Gas_Rx" SG_ 964 OCSSensrDataUpperLim 1;
BA_ "U_UP375_MY15_Diesel_Rx" SG_ 964 OCSSensrDataUpperLim 1;
BA_ "U_CD43_MY16_Gas_Rx" SG_ 964 OCSSensrDataUpperLim 1;
BA_ "U_CD4_MY13_Diesel_Rx" SG_ 964 OCSSensrDataLowerLim_UB 1;
BA_ "U_CD4_MY13_Gas_Rx" SG_ 964 OCSSensrDataLowerLim_UB 1;
BA_ "U_CD4_MY13_Hev_Rx" SG_ 964 OCSSensrDataLowerLim_UB 1;
BA_ "U_CD4_MY13_Phev_Rx" SG_ 964 OCSSensrDataLowerLim_UB 1;
BA_ "U_CD42_MY14_Diesel_Rx" SG_ 964 OCSSensrDataLowerLim_UB 1;
BA_ "U_CD42_MY14_Gas_Rx" SG_ 964 OCSSensrDataLowerLim_UB 1;
BA_ "U_P552_MY15_Gas_Rx" SG_ 964 OCSSensrDataLowerLim_UB 1;
BA_ "U_S550_MY15_Gas_Rx" SG_ 964 OCSSensrDataLowerLim_UB 1;
BA_ "U_C489_MY14_Gas_Rx" SG_ 964 OCSSensrDataLowerLim_UB 1;
BA_ "U_U502_MY15_Gas_Rx" SG_ 964 OCSSensrDataLowerLim_UB 1;
BA_ "U_UP375_MY15_Gas_Rx" SG_ 964 OCSSensrDataLowerLim_UB 1;
BA_ "U_UP375_MY15_Diesel_Rx" SG_ 964 OCSSensrDataLowerLim_UB 1;
BA_ "U_CD43_MY16_Gas_Rx" SG_ 964 OCSSensrDataLowerLim_UB 1;
BA_ "CrossOver_InfoCAN" SG_ 964 PrkAid_D_Falt 1;
BA_ "GenSigSendType" SG_ 964 PrkAid_D_Falt 3;
BA_ "GenSigSendType" SG_ 964 OCSSensrDataLowerLim 3;
BA_ "U_CD4_MY13_Diesel_Rx" SG_ 964 OCSSensrDataLowerLim 1;
BA_ "U_CD4_MY13_Gas_Rx" SG_ 964 OCSSensrDataLowerLim 1;
BA_ "U_CD4_MY13_Hev_Rx" SG_ 964 OCSSensrDataLowerLim 1;
BA_ "U_CD4_MY13_Phev_Rx" SG_ 964 OCSSensrDataLowerLim 1;
BA_ "U_CD42_MY14_Diesel_Rx" SG_ 964 OCSSensrDataLowerLim 1;
BA_ "U_CD42_MY14_Gas_Rx" SG_ 964 OCSSensrDataLowerLim 1;
BA_ "U_P552_MY15_Gas_Rx" SG_ 964 OCSSensrDataLowerLim 1;
BA_ "U_S550_MY15_Gas_Rx" SG_ 964 OCSSensrDataLowerLim 1;
BA_ "U_C489_MY14_Gas_Rx" SG_ 964 OCSSensrDataLowerLim 1;
BA_ "U_U502_MY15_Gas_Rx" SG_ 964 OCSSensrDataLowerLim 1;
BA_ "U_UP375_MY15_Gas_Rx" SG_ 964 OCSSensrDataLowerLim 1;
BA_ "U_UP375_MY15_Diesel_Rx" SG_ 964 OCSSensrDataLowerLim 1;
BA_ "U_CD43_MY16_Gas_Rx" SG_ 964 OCSSensrDataLowerLim 1;
BA_ "U_CD4_MY13_Diesel_Rx" SG_ 964 WiprFront_D_Stat_UB 1;
BA_ "U_CD4_MY13_Gas_Rx" SG_ 964 WiprFront_D_Stat_UB 1;
BA_ "U_CD4_MY13_Hev_Rx" SG_ 964 WiprFront_D_Stat_UB 1;
BA_ "U_CD4_MY13_Phev_Rx" SG_ 964 WiprFront_D_Stat_UB 1;
BA_ "U_CD42_MY14_Diesel_Rx" SG_ 964 WiprFront_D_Stat_UB 1;
BA_ "U_CD42_MY14_Gas_Rx" SG_ 964 WiprFront_D_Stat_UB 1;
BA_ "U_P552_MY15_Gas_Rx" SG_ 964 WiprFront_D_Stat_UB 1;
BA_ "U_S550_MY15_Gas_Rx" SG_ 964 WiprFront_D_Stat_UB 1;
BA_ "U_C489_MY14_Gas_Rx" SG_ 964 WiprFront_D_Stat_UB 1;
BA_ "U_B562LC_MY14_Gas_Rx" SG_ 964 WiprFront_D_Stat_UB 1;
BA_ "U_U502_MY15_Gas_Rx" SG_ 964 WiprFront_D_Stat_UB 1;
BA_ "U_UP375_MY15_Gas_Rx" SG_ 964 WiprFront_D_Stat_UB 1;
BA_ "U_UP375_MY15_Diesel_Rx" SG_ 964 WiprFront_D_Stat_UB 1;
BA_ "U_CD43_MY16_Gas_Rx" SG_ 964 WiprFront_D_Stat_UB 1;
BA_ "GenSigStartValue" SG_ 964 WiprFront_D_Stat 15;
BA_ "GenSigSendType" SG_ 964 WiprFront_D_Stat 3;
BA_ "U_CD4_MY13_Diesel_Rx" SG_ 964 WiprFront_D_Stat 1;
BA_ "U_CD4_MY13_Gas_Rx" SG_ 964 WiprFront_D_Stat 1;
BA_ "U_CD4_MY13_Hev_Rx" SG_ 964 WiprFront_D_Stat 1;
BA_ "U_CD4_MY13_Phev_Rx" SG_ 964 WiprFront_D_Stat 1;
BA_ "U_CD42_MY14_Diesel_Rx" SG_ 964 WiprFront_D_Stat 1;
BA_ "U_CD42_MY14_Gas_Rx" SG_ 964 WiprFront_D_Stat 1;
BA_ "U_P552_MY15_Gas_Rx" SG_ 964 WiprFront_D_Stat 1;
BA_ "U_S550_MY15_Gas_Rx" SG_ 964 WiprFront_D_Stat 1;
BA_ "U_C489_MY14_Gas_Rx" SG_ 964 WiprFront_D_Stat 1;
BA_ "U_B562LC_MY14_Gas_Rx" SG_ 964 WiprFront_D_Stat 1;
BA_ "U_U502_MY15_Gas_Rx" SG_ 964 WiprFront_D_Stat 1;
BA_ "U_UP375_MY15_Gas_Rx" SG_ 964 WiprFront_D_Stat 1;
BA_ "U_UP375_MY15_Diesel_Rx" SG_ 964 WiprFront_D_Stat 1;
BA_ "U_CD43_MY16_Gas_Rx" SG_ 964 WiprFront_D_Stat 1;
BA_ "U_CD4_MY13_Diesel_Rx" SG_ 964 Sod_D_Rq_UB 1;
BA_ "U_CD4_MY13_Gas_Rx" SG_ 964 Sod_D_Rq_UB 1;
BA_ "U_CD4_MY13_Hev_Rx" SG_ 964 Sod_D_Rq_UB 1;
BA_ "U_CD4_MY13_Phev_Rx" SG_ 964 Sod_D_Rq_UB 1;
BA_ "U_CD42_MY14_Diesel_Rx" SG_ 964 Sod_D_Rq_UB 1;
BA_ "U_CD42_MY14_Gas_Rx" SG_ 964 Sod_D_Rq_UB 1;
BA_ "U_P552_MY15_Gas_Rx" SG_ 964 Sod_D_Rq_UB 1;
BA_ "U_S550_MY15_Gas_Rx" SG_ 964 Sod_D_Rq_UB 1;
BA_ "U_C489_MY14_Gas_Rx" SG_ 964 Sod_D_Rq_UB 1;
BA_ "U_B562LC_MY14_Gas_Rx" SG_ 964 Sod_D_Rq_UB 1;
BA_ "U_U502_MY15_Gas_Rx" SG_ 964 Sod_D_Rq_UB 1;
BA_ "U_UP375_MY15_Gas_Rx" SG_ 964 Sod_D_Rq_UB 1;
BA_ "U_UP375_MY15_Diesel_Rx" SG_ 964 Sod_D_Rq_UB 1;
BA_ "U_CD43_MY16_Gas_Rx" SG_ 964 Sod_D_Rq_UB 1;
BA_ "CrossOver_InfoCAN" SG_ 964 CamraDefog_B_Req 1;
BA_ "GenSigSendType" SG_ 964 CamraDefog_B_Req 3;
VAL_ 486 ACU_ARAudioSource_Rsp 15 "iPod" 14 "USB" 13 "BTAudio" 0 "AmfmRadio" 1 "FrontDisc" 2 "SDARS_DAB" 3 "InDashCdChanger" 4 "VoiceRecogniser" 5 "TelematicUnit" 6 "BluetoothPhone" 7 "RearDisc" 8 "APIM" 9 "FrontAuxInput" 10 "Navigation" 11 "RearAux" 12 "NotReq" ;
VAL_ 486 ACU_AROperationType_Rsp 0 "Inactive" 1 "Requestaudioresource" 2 "Releaseaudioresource" 3 "Releaseallaudioresouces" 4 "Getresourceupdate" 5 "Getallresourceupdates" ;
VAL_ 486 ACU_ARReqstrSystem_Rsp 0 "FrontRequester" 1 "RearRequester" ;
VAL_ 486 ACU_ARResponse_Rsp 0 "Inactive" 1 "RequestAccepted" 2 "RequestAcceptedWoCtrl" 3 "RequestDenied" 4 "RessourceUpdateStatus" ;
VAL_ 486 ACU_ARReqstrPriority_Rp 0 "EmergencyServ" 1 "TelService" 2 "AutoAnswer" 3 "Ta" 4 "PttMutevoice" 5 "NavUserVoiceCmd" 6 "NavSysVoiceCmd" 7 "Radio" 8 "Disc" 9 "Alarm" 10 "Ptynews" 11 "Aux_ExtSource" 12 "MobileNavAndTelMute" 13 "ManualAudioMute" 14 "NotReq" ;
VAL_ 486 ACU_RUAudioSource_St 15 "iPod" 14 "USB" 13 "BTAudio" 0 "AmfmRadio" 1 "FrontDisc" 2 "SDARS_DAB" 3 "InDashCdChanger" 4 "VoiceRecogniser" 5 "TelematicUnit" 6 "BluetoothPhone" 7 "RearDisc" 8 "APIM" 9 "FrontAuxInput" 10 "Navigation" 11 "RearAux" 12 "NotReq" ;
VAL_ 486 ACU_RUReqstrSystem_St 0 "FrontRequester" 1 "RearRequester" ;
VAL_ 486 ACU_RUResReqstStatus_St 0 "NoResourceupdate" 1 "Deallocated" 2 "Allocated" 3 "Stacked" 4 "Granted" 5 "GrantedNoControlOfAudioSrc" ;
VAL_ 486 ACU_RUReqstrPriority_St 0 "EmergencyServ" 1 "TelService" 2 "AutoAnswer" 3 "Ta" 4 "PttMutevoice" 5 "NavUserVoiceCmd" 6 "NavSysVoiceCmd" 7 "Radio" 8 "Disc" 9 "Alarm" 10 "Ptynews" 11 "Aux_ExtSource" 12 "MobileNavAndTelMute" 13 "ManualAudioMute" 14 "NotReq" ;
VAL_ 359 ElPw_D_StatStrtStop 15 "NotUsed6" 14 "NotUsed5" 13 "NotUsed4" 12 "NotUsed3" 11 "NotUsed2" 10 "NotUsed1" 9 "Supported_Level_4" 8 "Supported_Level_3" 7 "Supported_Level_2" 6 "Supported_Level_1" 5 "Limited_Support" 4 "Fault_Limited" 3 "LV_Event_in_Progress" 2 "Not_Supported_Imminent" 1 "Supported_All" 0 "Not_Supported" ;
VAL_ 359 PrplWhlTot2_Tq_Actl 65535 "Fault" 65534 "NoDataExists" ;
VAL_ 359 TrnAinTq_D_Qf 3 "OK" 2 "Not_Within_Specifications" 1 "No_Data_Exists" 0 "Faulty" ;
VAL_ 359 PwPckTq_D_Stat 3 "PwPckOn_TqAvailable" 2 "StartInPrgrss_TqNotAvail" 1 "PwPckOn_TqNotAvailable" 0 "PwPckOff_TqNotAvailable" ;
VAL_ 359 Eng_D_Stat 3 "NotUsed" 2 "EngAutoStopped" 1 "EngOn" 0 "EngOff" ;
VAL_ 359 ElPw_D_Stat 7 "NotUsed_3" 6 "NotUsed_2" 5 "NotUsed_1" 4 "Fault_Limited" 3 "LV_Event_In_Progress" 2 "Not_Supported_Imminent" 1 "Supported" 0 "Not_Supported" ;
VAL_ 131 VehYaw_W_Actl_UB 1 "Fresh_data" 0 "Unchanged_data" ;
VAL_ 131 VehYaw_W_Actl 65535 "Faulty" 65534 "NoDataExists" ;
VAL_ 1003 PersRecallSrc_D_Actl 7 "NotUsed_3" 6 "NotUsed_2" 5 "NotUsed_1" 4 "MemorySwitch" 3 "RemoteStart" 2 "KeyFob" 1 "CenterStack" 0 "Null" ;
VAL_ 1003 Pers4Key_D_Stat 3 "NotUsed" 2 "KeyUnassociated" 1 "KeyAssociated" 0 "Null" ;
VAL_ 1003 Pers3Key_D_Stat 3 "NotUsed" 2 "KeyUnassociated" 1 "KeyAssociated" 0 "Null" ;
VAL_ 1003 Pers2Key_D_Stat 3 "NotUsed" 2 "KeyUnassociated" 1 "KeyAssociated" 0 "Null" ;
VAL_ 1003 Pers1Key_D_Stat 3 "NotUsed" 2 "KeyUnassociated" 1 "KeyAssociated" 0 "Null" ;
VAL_ 1003 EmPrflNo_D_Stat 7 "Unused_3" 6 "Unused_2" 5 "Unused_1" 4 "PERS_4" 3 "PERS_3" 2 "PERS_2" 1 "PERS_1" 0 "Null" ;
VAL_ 1003 EmPrflKeyAssoc_D_Stat 7 "WrongDevice" 6 "KeyAssociateFailed" 5 "KeyAssociateSuccess" 4 "KeyAlreadyInUse" 3 "KeyDisassociated" 2 "KeyAssociationExited" 1 "KeyAssociationEntered" 0 "Null" ;
VAL_ 1003 VehKeyActv_D_Stat 15 "NotUsed7" 14 "NotUsed6" 13 "NotUsed5" 12 "NotUsed4" 11 "NotUsed3" 10 "NotUsed2" 9 "NotUsed1" 8 "Key8Active" 7 "Key7Active" 6 "Key6Active" 5 "Key5Active" 4 "Key4Active" 3 "Key3Active" 2 "Key2Active" 1 "Key1Active" 0 "NoKeyActive" ;
VAL_ 1003 PersSetupRestr_D_Actl 3 "Non_Moveable_Person" 2 "Moveable_Person" 1 "Vehicle" 0 "Factory" ;
VAL_ 1003 PersSetupAccessCtrl 1 "Limited" 0 "Full" ;
VAL_ 1003 PersConflict_D_Actl 1 "Conflict" 0 "No_Conflict" ;
VAL_ 1003 AssocConfirm_D_Actl 0 "None" 7 "Associate" 6 "Keycode_Rejected" 5 "Keycode_Accepted" 4 "In_Progress" 3 "Erase" 2 "Duplicate" 1 "Disassociate" ;
VAL_ 1003 PersNo_D_Actl 7 "Unused_3" 6 "Unused_2" 5 "Unused_1" 4 "Vehicle" 3 "PERS_4" 2 "PERS_3" 1 "PERS_2" 0 "PERS_1" ;
VAL_ 1003 PersNoPos_D_Actl 7 "Unused_3" 6 "Unused_2" 5 "Unused_1" 4 "Vehicle" 3 "PERS_4" 2 "PERS_3" 1 "PERS_2" 0 "PERS_1" ;
VAL_ 836 HvacPrecondMode_D_Rq 15 "NotUsed4" 14 "NotUsed3" 13 "NotUsed2" 12 "NotUsed1" 11 "Last_User_Settings" 10 "Auto" 9 "Max_Defrost" 8 "Windshield_Panel_Floor" 7 "Windshield_Panel" 6 "Windshield" 5 "Windshield_Floor" 4 "Floor" 3 "Panel_Floor" 2 "Panel" 1 "MAX_AC" 0 "Off" ;
VAL_ 836 HvacPrecondBlwr_D_Rq 15 "NotUsed6" 14 "NotUsed5" 13 "NotUsed4" 12 "NotUsed3" 11 "NotUsed2" 10 "NotUsed1" 9 "Last_User_Setting" 8 "Auto" 7 "Speed7" 6 "Speed6" 5 "Speed5" 4 "Speed4" 3 "Speed3" 2 "Speed2" 1 "Speed1" 0 "Off" ;
VAL_ 836 Foh_D_Stat 7 "Unused3" 6 "Unused2" 5 "Unused1" 4 "Stopping" 3 "Running" 2 "Starting" 1 "Prestart" 0 "Off" ;
VAL_ 819 BLISLEDStatPassSide 3 "Fault" 2 "Unused" 1 "On" 0 "Off" ;
VAL_ 819 WndwPsngrSide_D_Stat 3 "BothWindow_Operating" 2 "RearWindow_Operating" 1 "FrontWindow_Operating" 0 "NoWindows_Operating" ;
VAL_ 819 Pasngr_Lock_Sw_Stat 3 "Invalid" 2 "Unlock" 1 "Lock" 0 "Null" ;
VAL_ 819 ChildLckFdbckRp_B_Stat 1 "Locked" 0 "Unlock" ;
VAL_ 818 BLISLEDStatDriverSide 3 "Fault" 2 "Unused" 1 "On" 0 "Off" ;
VAL_ 818 WndwDrvSide_D_Stat 3 "BothWindow_Operating" 2 "RearWindow_Operating" 1 "FrontWindow_Operating" 0 "NoWindows_Operating" ;
VAL_ 818 KeyCylSwDrvDr_D_Stat 3 "Not Used" 2 "Unlock" 1 "Lock" 0 "Null" ;
VAL_ 818 Driver_Lock_Sw_Stat 3 "Invalid" 2 "Unlock" 1 "Lock" 0 "Null" ;
VAL_ 818 ChildLckPw_D_Rq 1 "Active" 0 "Null" ;
VAL_ 818 ChildLckFdbckRd_B_Stat 1 "Locked" 0 "Unlock" ;
VAL_ 818 RvrseMirrorChime_B_Rq 1 "Yes" 0 "No" ;
VAL_ 817 R_Pwr_Sliding_Dr_Rqst 1 "Active" 0 "Null" ;
VAL_ 817 L_Pwr_Sliding_Dr_Rqst 1 "Active" 0 "Null" ;
VAL_ 817 ChildLckMde_B_Stat 1 "Enable" 0 "Disable" ;
VAL_ 817 VehLckInd_D_Rq 3 "NotUsed" 2 "On_Day" 1 "On_Night" 0 "Off" ;
VAL_ 817 DrTgateOpen_B_Rq 1 "Open" 0 "Null" ;
VAL_ 817 DrTgateExtSwMde_B_Stat 1 "Enable" 0 "Disable" ;
VAL_ 817 Remote_Device_Feedback 7 "Unused3" 6 "Unused2" 5 "Unused1" 4 "Shutdown" 3 "Running" 2 "Starting" 1 "Acknowledge" 0 "Null" ;
VAL_ 817 Power_Liftgate_Rqst 1 "Active" 0 "Null" ;
VAL_ 817 Power_Decklid_Rqst 1 "Active" 0 "Null" ;
VAL_ 817 Veh_Lock_Requestor 31 "Unused8" 30 "Unused7" 29 "Unused6" 28 "Unused5" 27 "Unused4" 26 "Unused3" 25 "Unused2" 24 "Unused1" 23 "Diagnostics" 22 "Console_Lock" 21 "Child_Lock" 20 "Double_Lock" 19 "Passive_Pasenger" 18 "Passive_Driver" 17 "Slam_Lock_Protect" 16 "SYNC" 15 "Passport" 14 "Passive_Smart_Unlock" 13 "Autorelock" 12 "RemoteStart" 0 "Null" 1 "Autolock" 11 "Smart_Unlock" 10 "Sliding_Door" 9 "Passive" 8 "Remote" 7 "Programming" 6 "Powerslide" 5 "Keypad" 4 "Key_Cylinder" 3 "Interior" 2 "Auto_Unlock" ;
VAL_ 817 Veh_Lock_Sub_Id 15 "Unused7" 14 "Unused6" 13 "Unused5" 12 "Unused4" 11 "Unused3" 10 "Unused2" 9 "Unused1" 8 "Customer_8" 7 "Customer_7" 6 "Customer_6" 5 "Customer_5" 4 "Customer_4" 3 "Customer_3" 2 "Customer_2" 1 "Customer_1" 0 "Null" ;
VAL_ 817 ChildLck_D_Dsply 3 "NOT_SUPPORTED" 2 "ERROR" 1 "CHILD_UNLOCK" 0 "CHILD_LOCK" ;
VAL_ 817 WindowLockout_B_Stat 1 "Locked" 0 "Unlock" ;
VAL_ 817 Lockmsgtxt_D_Rq 7 "MSG7" 6 "MSG6" 5 "MSG5" 4 "MSG4" 3 "MSG3" 2 "MSG2" 1 "MSG1" 0 "NO_WARNING" ;
VAL_ 817 LockInhibit 1 "Inhibit" 0 "No_Inhibit" ;
VAL_ 817 Veh_Lock_Status 3 "UNLOCK_DRV" 2 "UNLOCK_ALL" 1 "LOCK_ALL" 0 "LOCK_DBL" ;
VAL_ 817 FobComm_D_Stat 3 "NotUsed" 2 "RemEngStartOK" 1 "RemEngStartFail" 0 "Null" ;
VAL_ 1091 ParkLampTrlrOut_B_Stat 1 "Out" 0 "Null" ;
VAL_ 1091 TrlrLampCtl_D_Stat 3 "NotUsed" 2 "TrlrLampCnnctDrvFailure" 1 "TrlrLampNotCnnctDrvFailure" 0 "Null" ;
VAL_ 1091 TrlrBattChrg_D_Stat 3 "Reverse" 2 "Normal" 1 "Low" 0 "Null" ;
VAL_ 1091 StopLampTrlrOut_B_Stat 1 "Out" 0 "Null" ;
VAL_ 1091 TurnLampTrlrRr_B_Stat 1 "Out" 0 "Null" ;
VAL_ 1091 TurnLampTrlrRl_B_Stat 1 "Out" 0 "Null" ;
VAL_ 1091 TrlrLampCnnct_B_Actl 1 "Yes" 0 "No" ;
VAL_ 1066 BattULo_U_Actl_UB 1 "Fresh_data" 0 "Unchanged_data" ;
VAL_ 1066 BattULo_U_Actl 255 "Fault" ;
VAL_ 1066 PwSrcULo_I_Mx 255 "Fault" ;
VAL_ 1066 PwSrcULo_I_Actl 255 "Fault" ;
VAL_ 1066 PwSrcULo_I_Mx_UB 1 "Fresh_data" 0 "Unchanged_data" ;
VAL_ 1066 PwSrcULo_I_Actl_UB 1 "Fresh_data" 0 "Unchanged_data" ;
VAL_ 994 Pers4OptIn_B_Stats 1 "OPTED_IN" 0 "NOT_OPTED_IN" ;
VAL_ 994 Pers3OptIn_B_Stats 1 "OPTED_IN" 0 "NOT_OPTED_IN" ;
VAL_ 994 Pers2OptIn_B_Stats 1 "OPTED_IN" 0 "NOT_OPTED_IN" ;
VAL_ 994 Pers1OptIn_B_Stats 1 "OPTED_IN" 0 "NOT_OPTED_IN" ;
VAL_ 994 CtrStkPersIndex_D_Actl 7 "Unused_3" 6 "Unused_2" 5 "Unused_1" 4 "Vehicle" 3 "PERS_4" 2 "PERS_3" 1 "PERS_2" 0 "PERS_1" ;
VAL_ 994 CtrStkDsplyOp_D_Rq 7 "Unused_2" 6 "Unused_1" 5 "Copy" 4 "Restore" 3 "Upload" 2 "Set" 1 "Query" 0 "Null" ;
VAL_ 994 PersStore_D_Rq 7 "Unused_2" 6 "Unused_1" 5 "Vehicle" 4 "PERS_4" 3 "PERS_3" 2 "PERS_2" 1 "PERS_1" 0 "Null" ;
VAL_ 376 PtcHtr_D_Cmd 3 "TurnOn" 2 "AutoMode" 1 "TurnOff" 0 "NoDecision_Initializing" ;
VAL_ 376 GasPrtc_D_RqDsply 7 "NotUsed_5" 6 "NotUsed_4" 5 "NotUsed_3" 4 "NotUsed_2" 3 "NotUsed_1" 2 "GpfOverLimit" 1 "GpfAtLimit" 0 "NormalOperation" ;
VAL_ 376 AslIconDsply_D_Rq 3 "Not_Used" 2 "On_Active" 1 "On_Passive" 0 "Off" ;
VAL_ 376 AslChime_B_Rq 1 "Yes" 0 "No" ;
VAL_ 376 AirAmbTe_D_Qf 3 "OK" 2 "Not_Within_Specifications" 1 "No_Data_Exists" 0 "Faulty" ;
VAL_ 376 DynoMde_B_Cmd 1 "Two_Wheel_Dyno" 0 "Normal_Operation" ;
VAL_ 376 AirAmb_P_Actl 63 "Fault" 62 "NoDataExists" ;
VAL_ 1068 Batt_Lo_SoC_B_UB 1 "Fresh_data" 0 "Unchanged_data" ;
VAL_ 1068 Batt_Lo_SoC_B 1 "Active" 0 "Inactive" ;
VAL_ 1068 Batt_Crit_SoC_B_UB 1 "Fresh_data" 0 "Unchanged_data" ;
VAL_ 1068 Batt_Crit_SoC_B 1 "Active" 0 "Inactive" ;
VAL_ 1068 Shed_T_Eng_Off_B_UB 1 "Fresh_data" 0 "Unchanged_data" ;
VAL_ 1068 Shed_T_Eng_Off_B 1 "Active" 0 "Inactive" ;
VAL_ 1068 Shed_Level_Req_UB 1 "Fresh_data" 0 "Unchanged_data" ;
VAL_ 1068 Shed_Level_Req 7 "Unused_2" 6 "Loads_On" 5 "SHED_ENG_OFF" 4 "SOON_ENG_OFF" 3 "SHED2_CONTIN" 2 "SHED2_TRANS" 1 "SHED1" 0 "NO_SHED" ;
VAL_ 1068 Shed_Feature_Group_ID_UB 1 "Fresh_data" 0 "Unchanged_data" ;
VAL_ 1068 Shed_Feature_Group_ID 14 "HtdMirr" 13 "HvacRearBlwr_Third" 12 "HvacRearBlwr_Second" 11 "HvacRearBlwr_First" 31 "All LSHED1 Features" 10 "Htd_Windscrn" 9 "SpltHtdBcklight_HtdMirr" 8 "HtdBcklight_HtdMirr" 7 "HtdCoolSeat_FrtDriver" 6 "HtdCoolSeat_FrtPass" 5 "HtdCoolSeat_RearPass" 4 "HtdCoolSeat_RearDriver" 3 "SmartTrlrTowBattCharge" 2 "Htd_StrWhl" 1 "Htd_Washer_Fluid" 0 "No_LSHED1_Features" 15 "Engine_Coolant_Fan" ;
VAL_ 1068 Shed_Drain_Eng_Off_B_UB 1 "Fresh_data" 0 "Unchanged_data" ;
VAL_ 1068 Shed_Drain_Eng_Off_B 1 "Active" 0 "Inactive" ;
VAL_ 1068 BSBattSOC_UB 1 "Fresh_data" 0 "Unchanged_data" ;
VAL_ 1068 AirCondRec_B_Rq_UB 1 "Fresh_data" 0 "Unchanged_data" ;
VAL_ 1068 AirCondFluidHi_P_Actl_UB 1 "Fresh_data" 0 "Unchanged_data" ;
VAL_ 1068 BattULoState_D_Qlty_UB 1 "Fresh_data" 0 "Unchanged_data" ;
VAL_ 1068 AirCondClutch_B_Stats_UB 1 "Fresh_data" 0 "Unchanged_data" ;
VAL_ 1068 AirCondRec_B_Rq 1 "Yes" 0 "No" ;
VAL_ 1068 AirCondFluidHi_P_Actl 255 "Fault" 254 "Unknown" ;
VAL_ 1068 AirCondClutch_B_Stats 1 "Yes" 0 "No" ;
VAL_ 1068 BattULoState_D_Qlty 3 "OK" 2 "Not_Within_Specifications" 1 "Eval_In_Progress" 0 "Fault" ;
VAL_ 963 WrlssAcsyChrgInhbt_B_Rq 1 "Yes" 0 "No" ;
VAL_ 963 PudLampPsngr_D_Rq 3 "Ramp_Down" 2 "Ramp_Up" 1 "On" 0 "Off" ;
VAL_ 963 PudLampDrv_D_Rq 3 "Ramp_Down" 2 "Ramp_Up" 1 "On" 0 "Off" ;
VAL_ 963 DrTgateLck_D_Stat 3 "NotUsed" 2 "Unlock" 1 "Lock" 0 "Null" ;
VAL_ 963 Illuminated_Entry_Stat 1 "On" 0 "Off" 3 "Invalid" 2 "Unknown" ;
VAL_ 963 Dr_Courtesy_Light_Stat 1 "On" 0 "Off" 3 "Invalid" 2 "Unknown" ;
VAL_ 963 ImpactEvntFdbck_D_Stat 3 "NotUsed" 2 "EventComplete" 1 "EventInProgress" 0 "Normal" ;
VAL_ 963 HeadLampLoOut_B_Stat 1 "Out" 0 "Null" ;
VAL_ 963 HeadLghtHiFdbck_D_Stat 3 "NotUsed" 2 "Cancel" 1 "Hold" 0 "Allow_Change" ;
VAL_ 963 PrkLightChime_B_Rq 1 "On" 0 "Off" ;
VAL_ 963 TrnNotInPrkChime_B_Rq 1 "On" 0 "Off" ;
VAL_ 963 HomeSafeLtChime_B_Rq 1 "On" 0 "Off" ;
VAL_ 963 StopLghtOn_B_Stat 1 "On" 0 "Off" ;
VAL_ 963 RvrseLghtOn_B_Stat 1 "On" 0 "Off" ;
VAL_ 963 PrkLght_D_Stat 3 "Park_Both" 2 "Park_Right" 1 "Park_Left" 0 "Off" ;
VAL_ 963 HeadLghtSwtch_D_Stat 3 "Autolamp" 2 "Headlamp" 1 "Parklamp" 0 "Off" ;
VAL_ 963 KeyInIgnWarn_B_Cmd 1 "On" 0 "Off" ;
VAL_ 963 HeadLampLoFrOn_B_Stat 1 "Low" 0 "Not_Low" ;
VAL_ 963 HeadLampLoFlOn_B_Stat 1 "Low" 0 "Not_Low" ;
VAL_ 963 Headlamp_On_Wrning_Cmd 1 "On" 0 "Off" ;
VAL_ 963 HeadLampLoActv_B_Stat 1 "On" 0 "Off" ;
VAL_ 963 HeadLghtHiOn_B_Stat 1 "On" 0 "Off" ;
VAL_ 963 Park_Brake_Chime_Rqst 1 "On" 0 "Off" ;
VAL_ 963 BrkWarnInd_B_Rq 1 "On" 0 "Off" ;
VAL_ 963 Brk_Fluid_Lvl_Low 3 "Invalid" 2 "Unknown" 1 "Low" 0 "OK" ;
VAL_ 963 ReducedGuard_D_Stat 3 "NotUsed" 2 "Alarm_On" 1 "Alarm_Off_Previously_On" 0 "Alarm_Off" ;
VAL_ 963 Courtesy_BSave_Stat 3 "Invalid" 2 "Unknown" 1 "No_Effect" 0 "Off" ;
VAL_ 963 DayRnngLampOn_B_Stat 1 "On" 0 "Off" ;
VAL_ 963 PerimeterAlarmChimeRq 1 "On" 0 "Off" ;
VAL_ 963 Courtesy_Delay_Status 3 "Invalid" 2 "Unknown" 1 "On" 0 "Off" ;
VAL_ 963 Perimeter_Alarm_Status 3 "Activated" 2 "Armed" 1 "Prearmed" 0 "Disarmed" ;
VAL_ 963 WndwGlbl_D_Cmd 7 "NotUsed3" 6 "NotUsed2" 5 "NotUsed1" 4 "GLEARN" 3 "GCLOSE" 2 "GOPEN" 1 "GSTOP" 0 "Null" ;
VAL_ 963 PudLamp_D_Rq 3 "RAMP_DOWN" 2 "RAMP_UP" 1 "ON" 0 "OFF" ;
VAL_ 964 Cta_D_Rq_UB 1 "Fresh_data" 0 "Unchanged_data" ;
VAL_ 964 Cta_D_Rq 3 "Unused" 2 "NoDataExists" 1 "On" 0 "Off" ;
VAL_ 964 GearRvrse_D_Actl_UB 1 "Fresh_data" 0 "Unchanged_data" ;
VAL_ 964 GearRvrse_D_Actl 7 "Fault" 6 "NotUsed_3" 5 "NotUsed_2" 4 "NotUsed_1" 3 "Active_confirmed" 2 "Active_not_confirmed" 1 "Inactive_confirmed" 0 "Inactive_not_confirmed" ;
VAL_ 964 TurnLghtSwtch_D_Stat_UB 1 "Fresh_data" 0 "Unchanged_data" ;
VAL_ 964 TurnLghtSwtch_D_Stat 3 "Unused_Treat_As_Off" 2 "Right" 1 "Left" 0 "Off" ;
VAL_ 964 Power_Liftgate_Mode_Cmd_UB 1 "Fresh_data" 0 "Unchanged_data" ;
VAL_ 964 Power_Liftgate_Mode_Cmd 1 "Enable" 0 "Disable" ;
VAL_ 964 MetricActvTe_B_Actl_UB 1 "Fresh_data" 0 "Unchanged_data" ;
VAL_ 964 MetricActvTe_B_Actl 1 "Active" 0 "Inactive" ;
VAL_ 964 EngClntTe_D_Qf 3 "OK" 2 "Not_Within_Specifications" 1 "No_Data_Exists" 0 "Faulty" ;
VAL_ 964 Sod_D_Rq 2 "BLIS_On_Second_Warning_ON" 1 "BLIS_On_Second_Warning_OFF" 0 "Off" ;
VAL_ 964 MetricActv_B_Actl 1 "Active" 0 "Inactive" ;
VAL_ 964 MetricActv_B_Actl_UB 1 "Fresh_data" 0 "Unchanged_data" ;
VAL_ 964 EngClnt_Te_Actl_UB 1 "Fresh_data" 0 "Unchanged_data" ;
VAL_ 964 OCSSensrDataUpperLim_UB 1 "Fresh_data" 0 "Unchanged_data" ;
VAL_ 964 OCSSensrDataUpperLim 255 "Invalid" ;
VAL_ 964 OCSSensrDataLowerLim_UB 1 "Fresh_data" 0 "Unchanged_data" ;
VAL_ 964 PrkAid_D_Falt 7 "NotUsed2" 6 "NotUsed1" 5 "Failure_Front_PSM_Sensors" 4 "No_Data_Exists" 3 "Failure_Rear_Sensors" 2 "Speaker_Fault" 1 "ECU_Fault" 0 "No_Fault" ;
VAL_ 964 OCSSensrDataLowerLim 255 "Invalid" ;
VAL_ 964 PrkAid_D_Falt_UB 1 "Fresh_data" 0 "Unchanged_data" ;
VAL_ 964 WiprFront_D_Stat_UB 1 "Fresh_data" 0 "Unchanged_data" ;
VAL_ 964 WiprFront_D_Stat 15 "NO_DATA_EXISTS" 14 "STALLED" 13 "RESERVED" 12 "AUTO_ADJUST" 11 "COURTESYWIPE" 10 "AUTO_HIGH" 9 "AUTO_LOW" 8 "WASH" 7 "MIST_FLICK" 6 "MAN_HIGH" 5 "MAN_LOW" 4 "MAN_INT_ON" 3 "MAN_INT_OFF" 2 "OFF_MOVING" 1 "AUTO_OFF" 0 "OFF" ;
VAL_ 964 CamraDefog_B_Req_UB 1 "Fresh_data" 0 "Unchanged_data" ;
VAL_ 964 Sod_D_Rq_UB 1 "Fresh_data" 0 "Unchanged_data" ;
VAL_ 964 CamraDefog_B_Req 1 "On" 0 "Off" ;
